VERSION ""

NS_ :

BS_:

BU_: FUSION IVI HMI Meter DataCenter WCM

BO_ 279 FD2_CE100_0: 64 FUSION
 SG_ CreepSW_Sta : 23|1@0+ (1,0) [0|1] "" IVI
 SG_ EngageP_Fail : 22|1@0+ (1,0) [0|1] "" IVI
 SG_ DisengageP_Fail : 21|1@0+ (1,0) [0|1] "" IVI
 SG_ FalseNPrevent_Sta : 20|1@0+ (1,0) [0|1] "" IVI
 SG_ DynoModeStaChk : 19|2@0+ (1,0) [0|2] "" IVI
 SG_ CoastDwModeStaChk : 17|2@0+ (1,0) [0|2] "" IVI
 SG_ DemoModeStaChk : 31|2@0+ (1,0) [0|2] "" IVI
 SG_ MSA_Crl_Sta : 29|3@0+ (1,0) [0|7] "" IVI
 SG_ CC_Crl_Sta : 26|3@0+ (1,0) [0|7] "" IVI
 SG_ LVChrgFuncStaChk : 39|2@0+ (1,0) [0|2] "" IVI
 SG_ ShiftGearPosn : 37|3@0+ (1,0) [0|7] "" IVI,HMI,Meter,DataCenter
 SG_ PwrSta : 34|3@0+ (1,0) [0|7] "" IVI,HMI,Meter,WCM,DataCenter
 SG_ XWDMode : 47|2@0+ (1,0) [0|2] "" IVI
 SG_ CCU_ACLampSts : 45|1@0+ (1,0) [0|1] "" IVI,HMI
 SG_ CCU_Dispaly_Request : 44|1@0+ (1,0) [0|1] "" IVI
 SG_ CCU_EcoSts : 43|1@0+ (1,0) [0|1] "" IVI
 SG_ CCU_AutoMidLampSts : 42|1@0+ (1,0) [0|1] "" IVI
 SG_ CCU_AutoLampSts : 41|1@0+ (1,0) [0|1] "" IVI,HMI,DataCenter
 SG_ CCU_ACMaxLampSts : 40|1@0+ (1,0) [0|1] "" IVI
 SG_ CCU_RrOnOffLampSts : 55|1@0+ (1,0) [0|1] "" IVI
 SG_ sigWindDirZon1St : 54|3@0+ (1,0) [0|7] "" IVI,HMI
 SG_ CCU_FrtOnOffLampSts : 51|1@0+ (1,0) [0|1] "" IVI
 SG_ sigWindDirZon3St : 50|3@0+ (1,0) [0|7] "" IVI
 SG_ sigAirIntenZon1St : 63|4@0+ (1,0) [0|15] "" IVI,HMI
 SG_ sigAirIntenZon3St : 59|4@0+ (1,0) [0|15] "" IVI
 SG_ CCU_SyncLampSts : 71|1@0+ (1,0) [0|1] "" IVI
 SG_ sigDfrstSt : 70|1@0+ (1,0) [0|1] "" IVI,HMI
 SG_ sigSetTempZon3St : 69|6@0+ (0.5,17) [17|32] "Deg^C" IVI
 SG_ sigRecircSt : 79|1@0+ (1,0) [0|1] "" IVI,HMI
 SG_ sigHvacSt : 78|1@0+ (1,0) [0|1] "" IVI
 SG_ sigSetTempZon2St : 77|6@0+ (0.5,17) [17|32] "Deg^C" IVI,HMI
 SG_ VCUBrkSWSta : 87|2@0+ (1,0) [0|2] "" IVI
 SG_ sigSetTempZon1St : 85|6@0+ (0.5,17) [17|32] "Deg^C" IVI,HMI
 SG_ sigCbnAirT : 95|8@0+ (0.5,-40) [-40|85] "Deg^C" IVI
 SG_ sigAmbAirT : 103|8@0+ (0.5,-40) [-40|85] "Deg^C" IVI
 SG_ FD_AGS_Cmd : 111|8@0+ (1,0) [0|255] "" IVI
 SG_ SysPwrSta : 119|4@0+ (1,0) [0|15] "" IVI
 SG_ MCUActDisFail : 115|1@0+ (1,0) [0|1] "" IVI
 SG_ PwrStaONTOIVIPopReq : 114|1@0+ (1,0) [0|1] "" IVI
 SG_ VCUFLDoorSta : 113|1@0+ (1,0) [0|1] "" IVI
 SG_ VCUFRDoorSta : 112|1@0+ (1,0) [0|1] "" IVI
 SG_ VCURLDoorSta : 127|1@0+ (1,0) [0|1] "" IVI
 SG_ VCURRDoorSta : 126|1@0+ (1,0) [0|1] "" IVI
 SG_ HVRlyOpFail : 125|1@0+ (1,0) [0|1] "" IVI
 SG_ SysAllowReadySta : 124|1@0+ (1,0) [0|1] "" IVI
 SG_ PwrStaONTOIVIPopT : 123|12@0+ (1,0) [0|4095] "SECOND" IVI
 SG_ Req_V2LSwOn : 140|1@0+ (1,0) [0|1] "" IVI
 SG_ Req_V2L_IVI_Popup : 139|4@0+ (1,0) [0|7] "" IVI
 SG_ MeterIndSpeed_raw32 : 151|8@0+ (1,0) [0|255] "" IVI,Meter
 SG_ DISC_Sta : 159|2@0+ (1,0) [0|3] "" IVI
 SG_ DISC_ButtSta : 143|1@0+ (1,0) [0|1] "" IVI
 SG_ CCMSA_SpdWar : 167|1@0+ (1,0) [0|1] "" IVI
 SG_ ActAPSPosn : 175|8@0+ (0.394,0) [0|100.076] "%" IVI
 SG_ VCUHoodSWSta : 166|1@0+ (1,0) [0|1] "" IVI
 SG_ VCUTailgateSWSta : 165|1@0+ (1,0) [0|1] "" IVI
 SG_ FD_EPB_Error : 177|2@0+ (1,0) [0|2] "" IVI,Meter
 SG_ FD_Park_Brake_Warning : 189|2@0+ (1,0) [0|2] "" IVI,Meter
 SG_ FD_TCS_Indicator : 163|2@0+ (1,0) [0|2] "" IVI,Meter
 SG_ FD_ABS_Warning : 183|2@0+ (1,0) [0|2] "" IVI,Meter
 SG_ FD_Steering_Warning : 161|2@0+ (1,0) [0|2] "" IVI,Meter
 SG_ FD_HV_Battery_Fault : 191|2@0+ (1,0) [0|2] "" IVI,Meter
 SG_ FD_EDrive_System : 179|2@0+ (1,0) [0|2] "" IVI,Meter
 SG_ FD_Battery_Charge_Warning : 181|2@0+ (1,0) [0|2] "" IVI,Meter
 SG_ FD_Power_limitation : 187|2@0+ (1,0) [0|2] "" IVI,Meter
 SG_ FD_Telltale_Fail : 164|1@0+ (1,0) [0|1] "" IVI,Meter
 SG_ FeatSetSpdFinal_raw32 : 199|8@0+ (1,0) [0|255] "" IVI
 SG_ Eng_ActvDmpDisabSta : 153|2@0+ (1,0) [0|2] "" IVI
 SG_ Eng_CoastDwSta : 155|2@0+ (1,0) [0|2] "" IVI
 SG_ Eng_PwrLockSta : 185|2@0+ (1,0) [0|2] "" IVI
 SG_ EDriveSysErr_AccPedalErr : 141|1@0+ (1,0) [0|1] "" IVI,Meter
 SG_ EDriveSysErr_MCUErr : 203|1@0+ (1,0) [0|1] "" IVI,Meter
 SG_ EDriveSysErr_ShifterErr : 223|1@0+ (1,0) [0|1] "" IVI,Meter
 SG_ EDriveSysErr_VCUErr : 142|1@0+ (1,0) [0|1] "" IVI,Meter
 SG_ Eng_AGSCloseSta : 222|1@0+ (1,0) [0|1] "" IVI
 SG_ Dimmer : 254|7@0+ (1,0) [0|100] "%" IVI
 SG_ VehMalfunLevel : 202|3@0+ (1,0) [0|5] "" IVI
 SG_ AntitheftSta : 244|2@0+ (1,0) [0|3] "" IVI,DataCenter
 SG_ Dr_SeatSta : 239|2@0+ (1,0) [0|2] "" IVI
 SG_ EVDriveMode : 157|2@0+ (1,0) [0|2] "" IVI
 SG_ AllDoorSW : 205|1@0+ (1,0) [0|1] "" IVI
 SG_ BCM_DoorLock_Sta : 240|1@0+ (1,0) [0|1] "" IVI,DataCenter
 SG_ BrakeLamp : 236|1@0+ (1,0) [0|1] "" IVI
 SG_ DoorLockIND : 204|1@0+ (1,0) [0|1] "" IVI
 SG_ DrDoorSW : 225|1@0+ (1,0) [0|1] "" IVI
 SG_ FollowMe : 242|1@0+ (1,0) [0|1] "" IVI
 SG_ Fr_FogLamp : 237|1@0+ (1,0) [0|1] "" IVI
 SG_ HazardSW : 227|1@0+ (1,0) [0|1] "" IVI
 SG_ HoodSW : 213|1@0+ (1,0) [0|1] "" IVI
 SG_ HVSysErr_IsolationErr : 210|1@0+ (1,0) [0|1] "" IVI,Meter
 SG_ HVSysErr_PackErr : 211|1@0+ (1,0) [0|1] "" IVI,Meter
 SG_ HVSysErr_RelayErr : 212|1@0+ (1,0) [0|1] "" IVI,Meter
 SG_ H_Beam : 226|1@0+ (1,0) [0|1] "" IVI
 SG_ LBSD : 230|1@0+ (1,0) [0|1] "" IVI
 SG_ LDRL : 233|1@0+ (1,0) [0|1] "" IVI
 SG_ LimphomeAct : 207|1@0+ (1,0) [0|1] "" IVI,Meter
 SG_ LockSetting : 247|1@0+ (1,0) [0|1] "" IVI
 SG_ LTurnLP : 246|1@0+ (1,0) [0|1] "" IVI,Meter
 SG_ LVSysErr_PwrOutpErr : 208|1@0+ (1,0) [0|1] "" IVI,Meter
 SG_ L_Beam : 224|1@0+ (1,0) [0|1] "" IVI
 SG_ PAS_Sta_F_Sys : 214|1@0+ (1,0) [0|1] "" IVI
 SG_ PosLamp : 232|1@0+ (1,0) [0|1] "" IVI
 SG_ PsDoorSW : 229|1@0+ (1,0) [0|1] "" IVI
 SG_ PwrStaErr : 209|1@0+ (1,0) [0|1] "" IVI,Meter
 SG_ RBSD : 241|1@0+ (1,0) [0|1] "" IVI
 SG_ RDRL : 234|1@0+ (1,0) [0|1] "" IVI
 SG_ ReverseLamp : 235|1@0+ (1,0) [0|1] "" IVI
 SG_ RLDoorSW : 231|1@0+ (1,0) [0|1] "" IVI
 SG_ RRDoorSW : 206|1@0+ (1,0) [0|1] "" IVI
 SG_ Rr_Defog : 215|1@0+ (1,0) [0|1] "" IVI,HMI
 SG_ Rr_FogLamp : 228|1@0+ (1,0) [0|1] "" IVI
 SG_ RTurnLP : 245|1@0+ (1,0) [0|1] "" IVI,Meter
 SG_ Tailgate_SW : 255|1@0+ (1,0) [0|1] "" IVI
 SG_ FD_EBMErrSta : 221|2@0+ (1,0) [0|2] "" IVI,Meter
 SG_ APMDoorControlSta : 219|1@0+ (1,0) [0|1] "" IVI
 SG_ Req_Internal_V2L_Status_Lamp : 217|2@0+ (1,0) [0|3] "" IVI
 SG_ VCU_OPDHold : 218|1@0+ (1,0) [0|1] "" IVI
 SG_ DimmerEN : 15|1@0+ (1,0) [0|1] "" Vector__XXX
 SG_ FDC_VCU_PwrSaveReq_Cmd : 14|1@0+ (1,0) [0|1] "" IVI
 SG_ FDC_THCM_LEVentY_Sta : 7|7@0+ (1,0) [0|127] "%" IVI
 SG_ FDC_THCM_REVentY_Sta : 263|7@0+ (1,0) [0|127] "%" IVI
 SG_ FDC_THCM_CLEVentY_Sta : 271|7@0+ (1,0) [0|127] "%" IVI
 SG_ FDC_THCM_CREVentY_Sta : 279|7@0+ (1,0) [0|127] "%" IVI
 SG_ FDC_THCM_LEVentZ_Sta : 287|7@0+ (1,0) [0|127] "%" IVI
 SG_ FDC_THCM_REVentZ_Sta : 295|7@0+ (1,0) [0|127] "%" IVI
 SG_ FDC_THCM_CLEVentZ_Sta : 303|7@0+ (1,0) [0|127] "%" IVI
 SG_ FDC_THCM_CREVentZ_Sta : 311|7@0+ (1,0) [0|127] "%" IVI
 SG_ FDC_THCM_LEVentMode_Sta : 13|3@0+ (1,0) [0|7] "" IVI
 SG_ FDC_THCM_REVentMode_Sta : 10|3@0+ (1,0) [0|7] "" IVI
 SG_ FDC_THCM_LVent_Sta : 0|1@0+ (1,0) [0|1] "" IVI
 SG_ FDC_THCM_CLVent_Sta : 256|1@0+ (1,0) [0|1] "" IVI
 SG_ FDC_THCM_RVent_Sta : 264|1@0+ (1,0) [0|1] "" IVI
 SG_ FDC_THCM_CRVent_Sta : 272|1@0+ (1,0) [0|1] "" IVI
 SG_ LVSilentChrgSta : 319|2@0+ (1,0) [0|3] "" IVI,DataCenter
 SG_ FDC_THCM_PreWPTCHeat_Sta : 317|2@0+ (1,0) [0|3] "" IVI
 SG_ FDC_RAPS_ErrWarn_Sta : 315|3@0+ (1,0) [0|7] "" IVI
 SG_ FDC_V2L_IVIV2LDischarg_Cmd : 327|2@0+ (1,0) [0|3] "" IVI
 SG_ FDC_BCM_HMIKey1Func_Sta : 335|4@0+ (1,0) [0|15] "" HMI
 SG_ FDC_BCM_HMIKey2Func_Sta : 331|4@0+ (1,0) [0|15] "" HMI
 SG_ FDC_BCM_HMIKey3Func_Sta : 343|4@0+ (1,0) [0|15] "" HMI
 SG_ FDC_BCM_HMIKey4Func_Sta : 339|4@0+ (1,0) [0|15] "" HMI
 SG_ FDC_BCM_HMIKey5Func_Sta : 351|4@0+ (1,0) [0|15] "" HMI
 SG_ FDC_BCM_HMIKey6Func_Sta : 347|4@0+ (1,0) [0|15] "" HMI
 SG_ FDC_BCM_HMIKey7Func_Sta : 359|4@0+ (1,0) [0|15] "" HMI
 SG_ FDC_BCM_HMIKey8Func_Sta : 355|4@0+ (1,0) [0|15] "" HMI
 SG_ LVSilentChrgReq : 280|1@0+ (1,0) [0|1] "" IVI,DataCenter
 SG_ FDC_BCM_AutoWipHSpdEN_Sta : 288|1@0+ (1,0) [0|1] "" IVI
 SG_ FDC_VCU_LVChrgFreq_Sta : 325|2@0+ (1,0) [0|3] "" IVI,Meter,DataCenter
 SG_ FDC_VCU_TrailerDisOPD_Sta : 296|1@0+ (1,0) [0|1] "" IVI
 SG_ FDC_VCU_LVStaTooLow_Sta : 304|1@0+ (1,0) [0|1] "" IVI,Meter,DataCenter
 SG_ FDC_VCU_LVStaDropQuick_Sta : 312|1@0+ (1,0) [0|1] "" IVI,Meter,DataCenter

BO_ 435 GW2_C10_0: 32 FUSION
 SG_ VehSpeed : 23|12@0+ (0.125,0) [0|255.875] "km/h" IVI,HMI,Meter,WCM
 SG_ LF_WhlRotDir : 45|2@0+ (1,0) [0|3] "" IVI
 SG_ RF_WhlRotDir : 47|2@0+ (1,0) [0|3] "" IVI
 SG_ RF_PulseCount : 71|8@0+ (1,0) [0|255] "" IVI
 SG_ RF_PulseCount_V : 55|1@0+ (1,0) [0|1] "" IVI
 SG_ LF_PulseCount_V : 54|1@0+ (1,0) [0|1] "" IVI
 SG_ LF_PulseCount : 79|8@0+ (1,0) [0|255] "" IVI
 SG_ RR_PulseCount_V : 53|1@0+ (1,0) [0|1] "" IVI
 SG_ RR_WhlRotDir : 43|2@0+ (1,0) [0|3] "" IVI
 SG_ RR_PulseCount : 87|8@0+ (1,0) [0|255] "" IVI
 SG_ LR_PulseCount_V : 52|1@0+ (1,0) [0|1] "" IVI
 SG_ LR_WhlRotDir : 41|2@0+ (1,0) [0|3] "" IVI
 SG_ LR_PulseCount : 95|8@0+ (1,0) [0|255] "" IVI
 SG_ ESC_BeepReq : 111|1@0+ (1,0) [0|1] "" IVI
 SG_ ESC_OFF_Status : 99|2@0+ (1,0) [0|2] "" IVI
 SG_ HDD_Failed : 108|1@0+ (1,0) [0|1] "" IVI
 SG_ AVH_Failed : 107|1@0+ (1,0) [0|1] "" IVI
 SG_ HSA_Failed : 106|1@0+ (1,0) [0|1] "" IVI
 SG_ PBA_Failed : 105|1@0+ (1,0) [0|1] "" IVI
 SG_ HBB_Failed : 104|1@0+ (1,0) [0|1] "" IVI
 SG_ ESC_Failed : 119|1@0+ (1,0) [0|1] "" IVI
 SG_ TCS_Failed : 118|1@0+ (1,0) [0|1] "" IVI
 SG_ ABS_Failed : 117|1@0+ (1,0) [0|1] "" IVI
 SG_ EBD_Failed : 116|1@0+ (1,0) [0|1] "" IVI
 SG_ HDD_Active : 115|1@0+ (1,0) [0|1] "" IVI
 SG_ ESS_Active : 114|1@0+ (1,0) [0|1] "" IVI
 SG_ BTCS_Active : 113|1@0+ (1,0) [0|1] "" IVI
 SG_ Amber_WnlmpSta : 112|1@0+ (1,0) [0|1] "" IVI,Meter
 SG_ AVH_Active : 127|1@0+ (1,0) [0|1] "" IVI
 SG_ HSA_Active : 126|1@0+ (1,0) [0|1] "" IVI
 SG_ PBA_Active : 125|1@0+ (1,0) [0|1] "" IVI
 SG_ HBB_Active : 124|1@0+ (1,0) [0|1] "" IVI
 SG_ ABS_Active : 123|1@0+ (1,0) [0|1] "" IVI
 SG_ ESC_WnlmpSta : 97|2@0+ (1,0) [0|2] "" IVI,Meter
 SG_ ESC_Off_lmpSta : 120|1@0+ (1,0) [0|1] "" IVI
 SG_ ABS_WnlmpSta : 109|1@0+ (1,0) [0|1] "" IVI,Meter
 SG_ Red_WnlmpSta : 122|1@0+ (1,0) [0|1] "" IVI
 SG_ eBST_BeepReq : 100|1@0+ (1,0) [0|1] "" IVI
 SG_ eBST_RedWnlmpSta : 101|1@0+ (1,0) [0|1] "" IVI
 SG_ eBST_AmberWnlmpSta : 103|1@0+ (1,0) [0|1] "" IVI,Meter
 SG_ LowBrakeFluid_Sta : 102|1@0+ (1,0) [0|1] "" IVI
 SG_ HVBattVolt : 132|13@0+ (0.1,0) [0|819] "V" IVI
 SG_ DCDCAuxCur : 51|12@0+ (0.1,0) [0|409.5] "A" IVI
 SG_ HVBattCurr : 150|15@0+ (0.1,-1000) [-1000|2276.5] "A" IVI
 SG_ DCDCAuxVolt : 167|8@0+ (0.047,8) [8|19.938] "V" IVI
 SG_ Meter_Ind_VehSpeed : 27|12@0+ (0.125,0) [0|300] "km/h" IVI
 SG_ ESC_ADAS_Sta : 135|3@0+ (1,0) [0|6] "" IVI
 SG_ AEBAvail : 110|1@0+ (1,0) [0|1] "" IVI
 SG_ BrkDiscTempSta : 175|1@0+ (1,0) [0|1] "" IVI
 SG_ BrkSw_Sta : 121|1@0+ (1,0) [0|1] "" IVI
 SG_ BrkSw_V : 151|1@0+ (1,0) [0|1] "" IVI
 SG_ EBMErrSta : 174|2@0+ (1,0) [0|2] "" IVI,Meter
 SG_ EBMRLampSta : 172|2@0+ (1,0) [0|2] "" IVI,Meter
 SG_ LADB_Hibeam_Indication : 183|1@0+ (1,0) [0|1] "" IVI,Meter
 SG_ LADB_Operation_Status : 182|1@0+ (1,0) [0|1] "" IVI,Meter
 SG_ LADB_Warning : 181|1@0+ (1,0) [0|1] "" IVI,Meter
 SG_ LLB_Warning : 180|1@0+ (1,0) [0|1] "" IVI,Meter
 SG_ LAHB_Warning : 179|1@0+ (1,0) [0|1] "" IVI,Meter
 SG_ FLTurn_Light_Warning : 178|1@0+ (1,0) [0|1] "" IVI,Meter
 SG_ LDRL_Warning : 177|1@0+ (1,0) [0|1] "" IVI,Meter
 SG_ Lposition_Lamp_Warning : 176|1@0+ (1,0) [0|1] "" IVI,Meter
 SG_ RADB_Hibeam_Indication : 191|1@0+ (1,0) [0|1] "" IVI,Meter
 SG_ RADB_Operation_Status : 190|1@0+ (1,0) [0|1] "" IVI,Meter
 SG_ RADB_Warning : 189|1@0+ (1,0) [0|1] "" IVI,Meter
 SG_ RLB_Warning : 188|1@0+ (1,0) [0|1] "" IVI,Meter
 SG_ RAHB_Warning : 187|1@0+ (1,0) [0|1] "" IVI,Meter
 SG_ FRTurn_Light_Warning : 186|1@0+ (1,0) [0|1] "" IVI,Meter
 SG_ RDRL_Warning : 185|1@0+ (1,0) [0|1] "" IVI,Meter
 SG_ Rposition_Lamp_Warning : 184|1@0+ (1,0) [0|1] "" IVI,Meter
 SG_ SAS_Angle : 231|16@0+ (0.1,-900) [-900|900] "Deg" IVI
 SG_ CrashOutputSts : 247|8@0+ (1,0) [0|255] "" IVI
 SG_ EpasFailed : 217|2@0+ (1,0) [0|2] "" IVI,Meter
 SG_ AirBagFailCmd : 219|1@0+ (1,0) [0|1] "" IVI
 SG_ DriverSeatBeltCmd : 199|1@0+ (1,0) [0|1] "" IVI
 SG_ DrPMMLVOutPErrLmp : 206|1@0+ (1,0) [0|1] "" IVI,Meter
 SG_ DrPMMSysErrLmp : 207|1@0+ (1,0) [0|1] "" IVI,Meter
 SG_ DrSCPSysErrLmp : 205|1@0+ (1,0) [0|1] "" IVI,Meter
 SG_ FireDetErr : 220|1@0+ (1,0) [0|1] "" IVI
 SG_ FrPMMLimpHomeActReq : 204|1@0+ (1,0) [0|1] "" IVI,Meter
 SG_ HVBattErr : 218|1@0+ (1,0) [0|1] "" IVI,Meter
 SG_ PABSwitchCmd : 192|1@0+ (1,0) [0|1] "" IVI
 SG_ PsngrSeatBeltCmd : 197|1@0+ (1,0) [0|1] "" IVI
 SG_ RCenterSeatBeltCmd : 193|1@0+ (1,0) [0|1] "" IVI
 SG_ RDriverSeatBeltCmd : 198|1@0+ (1,0) [0|1] "" IVI
 SG_ RPsngrSeatBeltCmd : 196|1@0+ (1,0) [0|1] "" IVI
 SG_ SAS_V : 221|1@0+ (1,0) [0|1] "" IVI
 SG_ TLHPsngrSeatBeltCmd : 195|1@0+ (1,0) [0|1] "" IVI
 SG_ TRHPsngrSeatBeltCmd : 194|1@0+ (1,0) [0|1] "" IVI
 SG_ ABM_Passenger_ODS_Sta : 203|1@0+ (1,0) [0|1] "" IVI,Meter
 SG_ ABM_RearPassengerLH_ODS_Sta : 202|1@0+ (1,0) [0|1] "" IVI,Meter
 SG_ ABM_RearPassengerCTR_ODS_Sta : 201|1@0+ (1,0) [0|1] "" IVI,Meter
 SG_ ABM_RearPassengerRH_ODS_Sta : 200|1@0+ (1,0) [0|1] "" IVI,Meter
 SG_ LADBErr : 208|1@0+ (1,0) [0|1] "" IVI,Meter
 SG_ LH_BeamErr : 210|1@0+ (1,0) [0|1] "" IVI,Meter
 SG_ LL_BeamErr : 209|1@0+ (1,0) [0|1] "" IVI,Meter
 SG_ RADBErr : 168|1@0+ (1,0) [0|1] "" IVI,Meter
 SG_ RH_BeamErr : 170|1@0+ (1,0) [0|1] "" IVI,Meter
 SG_ RL_BeamErr : 169|1@0+ (1,0) [0|1] "" IVI,Meter
 SG_ RLTurnLPErr : 223|1@0+ (1,0) [0|1] "" IVI,Meter
 SG_ RRTurnLPErr : 222|1@0+ (1,0) [0|1] "" IVI,Meter
 SG_ FLTurnLPErr : 215|1@0+ (1,0) [0|1] "" IVI,Meter
 SG_ FRTurnLPErr : 214|1@0+ (1,0) [0|1] "" IVI,Meter

BO_ 372 GW2_CE200_0: 32 FUSION
 SG_ ADAS_VehSpdLim : 23|8@0+ (1,0) [0|254] "" IVI
 SG_ ADAS_LFC_Warn_Sound : 31|8@0+ (1,0) [0|255] "" IVI
 SG_ ACC_ObjDist : 98|11@0+ (0.1,0) [0|204.6] "m" IVI
 SG_ ACC_ObjRelSpd : 82|11@0+ (0.1,-100) [-100|104.6] "m/s" IVI
 SG_ ADAS_CAM_SpdLim : 44|5@0+ (1,0) [0|31] "" IVI
 SG_ ADAS_SLIF_SpdLim : 36|5@0+ (1,0) [0|31] "" IVI
 SG_ ADAS_ISA_Sta : 87|4@0+ (1,0) [0|6] "" IVI
 SG_ ADAS_WarningMsg : 55|4@0+ (1,0) [0|15] "" IVI
 SG_ ACC_ObjDstLvl : 70|3@0+ (1,0) [0|7] "" IVI
 SG_ ADAS_ACC_Sta : 47|3@0+ (1,0) [0|7] "" IVI
 SG_ ADAS_AEBReq : 115|3@0+ (1,0) [0|7] "" IVI
 SG_ ADAS_AEB_Sta : 66|3@0+ (1,0) [0|7] "" IVI
 SG_ ADAS_FCW_Sta : 39|3@0+ (1,0) [0|7] "" IVI
 SG_ ADAS_LaneModeL : 118|3@0+ (1,0) [0|7] "" IVI
 SG_ ADAS_LaneModeR : 190|3@0+ (1,0) [0|7] "" IVI
 SG_ ADAS_LDW_Sta : 78|3@0+ (1,0) [0|7] "" IVI
 SG_ ADAS_LFC_Sta : 102|3@0+ (1,0) [0|7] "" IVI
 SG_ ADAS_LKA_Sta : 187|3@0+ (1,0) [0|7] "" IVI
 SG_ ADAS_SLIF_Sta : 74|3@0+ (1,0) [0|5] "" IVI
 SG_ ADAS_LFC_Hands_Off_Warning : 207|2@0+ (1,0) [0|3] "" IVI
 SG_ ACC_TakeoverReq : 83|1@0+ (1,0) [0|1] "" IVI
 SG_ ActBrkLamp_Sta : 119|1@0+ (1,0) [0|1] "" IVI
 SG_ ADAS_FCW_Mute : 191|1@0+ (1,0) [0|1] "" IVI
 SG_ ADAS_FltWrnReq : 103|1@0+ (1,0) [0|1] "" IVI
 SG_ ADAS_LDW_Mute : 99|1@0+ (1,0) [0|1] "" IVI
 SG_ LVDA_Mute_Sta : 135|2@0+ (1,0) [0|3] "" IVI
 SG_ LKA_HOD_Display_Warning : 67|1@0+ (1,0) [0|1] "" IVI
 SG_ LKA_HOD_Sound_Warning : 75|1@0+ (1,0) [0|1] "" IVI
 SG_ LVDA_ACCStatusInformation : 2|1@0+ (1,0) [0|1] "" IVI
 SG_ LVDA_Disabled : 3|1@0+ (1,0) [0|1] "" IVI
 SG_ LVDA_Failinfo : 59|1@0+ (1,0) [0|1] "" IVI
 SG_ LVDA_Warning : 63|1@0+ (1,0) [0|1] "" IVI
 SG_ ISA_WarningMsg : 51|4@0+ (1,0) [0|6] "" IVI
 SG_ ForceLowBeam : 1|2@0+ (1,0) [0|2] "" IVI
 SG_ CameraBlockage : 4|1@0+ (1,0) [0|1] "" IVI
 SG_ HazardWarningReq : 15|1@0+ (1,0) [0|1] "" IVI
 SG_ LeftTurnLightReq : 71|1@0+ (1,0) [0|1] "" IVI
 SG_ Target_Type : 11|4@0+ (1,0) [0|15] "" IVI
 SG_ RightTurnLightReq : 79|1@0+ (1,0) [0|1] "" IVI
 SG_ ADAS_FCW_Sensitivity : 6|1@0+ (1,0) [0|1] "" IVI
 SG_ ADAS_LDW_Sensitivity : 5|1@0+ (1,0) [0|1] "" IVI
 SG_ MCU_B_R_RealPwrKw_Sta : 159|16@0+ (0.1,-530) [-530|6023.4] "KW" IVI
 SG_ MCU_B_F_RealPwrKw_Sta : 143|16@0+ (0.1,-530) [-530|6023.4] "KW" IVI
 SG_ HVBSOH : 175|8@0+ (0.4,0) [0|100] "%" IVI
 SG_ FDC_BCM_TimeGapLevel_Sta : 14|3@0+ (1,0) [0|7] "" IVI
 SG_ HVBPwrAvailChrg : 235|12@0+ (0.2,0) [0|819] "KW" IVI
 SG_ HVBPwrAvailChrg30 : 231|12@0+ (0.2,0) [0|819] "KW" IVI
 SG_ HVBPwrAvailChrg60 : 211|12@0+ (0.2,0) [0|819] "KW" IVI
 SG_ HVBFullChrgPwr : 205|10@0+ (0.1,0) [0|102.2] "KWh" IVI

BO_ 450 GW2_CE100_0: 32 FUSION
 SG_ HVBChrgErr : 23|8@0+ (1,0) [0|255] "" IVI
 SG_ V2LSta : 31|2@0+ (1,0) [0|3] "" IVI
 SG_ DisChrgPlugErr : 29|2@0+ (1,0) [0|3] "" IVI
 SG_ ExtChrgSta : 27|2@0+ (1,0) [0|3] "" IVI
 SG_ ChrgPlugSta : 25|2@0+ (1,0) [0|3] "" IVI
 SG_ HVBOvrTempErr : 39|1@0+ (1,0) [0|1] "" IVI
 SG_ OBC_AC_Cur_Lim : 38|2@0+ (1,0) [0|3] "" IVI
 SG_ HVBOvrTempWarn : 36|2@0+ (1,0) [0|2] "" IVI
 SG_ Shifter_Fail_sta : 34|3@0+ (1,0) [0|7] "" IVI
 SG_ Shifter_Handle_Cmd : 47|8@0+ (1,0) [0|255] "" IVI
 SG_ OBCACVoltInf : 55|12@0+ (0.1,0) [0|409.4] "V" IVI
 SG_ OBCFaultSta : 59|2@0+ (1,0) [0|3] "" IVI
 SG_ OBCACCurrInf : 57|10@0+ (0.125,-40) [-40|87.75] "A" IVI
 SG_ FrntPTCLeActHeatPwr : 79|8@0+ (25,0) [0|6375] "W" IVI
 SG_ FrntPTCRiActHeatPwr : 87|8@0+ (25,0) [0|6375] "W" IVI
 SG_ FrntPTCRearLeActHeatPwr : 95|8@0+ (25,0) [0|6375] "W" IVI
 SG_ FrntPTCRearRiActHeatPwr : 103|8@0+ (25,0) [0|6375] "W" IVI
 SG_ HVBContactorSta : 111|1@0+ (1,0) [0|1] "" IVI
 SG_ RLS_Lamp_Sta : 110|1@0+ (1,0) [0|1] "" IVI
 SG_ SWC_ACC_Sta : 119|1@0+ (1,0) [0|1] "" IVI
 SG_ SWC_Down_Sta : 118|1@0+ (1,0) [0|1] "" IVI
 SG_ SWC_RegenUp : 117|1@0+ (1,0) [0|1] "" IVI
 SG_ SWC_Left_Sta : 116|1@0+ (1,0) [0|1] "" IVI
 SG_ SWC_mode_Sta : 115|1@0+ (1,0) [0|1] "" IVI
 SG_ SWC_Right_Sta : 114|1@0+ (1,0) [0|1] "" IVI
 SG_ SWC_Trip_Sta : 113|1@0+ (1,0) [0|1] "" IVI
 SG_ SWC_Up_Sta : 112|1@0+ (1,0) [0|1] "" IVI
 SG_ SWC_LKA_Sta : 127|1@0+ (1,0) [0|1] "" IVI
 SG_ SWC_Undefined_Sta : 135|1@0+ (1,0) [0|1] "" IVI
 SG_ SWC_VR_Sta : 143|1@0+ (1,0) [0|1] "" IVI
 SG_ ChargeInletLockSta : 151|1@0+ (1,0) [0|1] "" IVI
 SG_ COMP_ActualPwr : 180|13@0+ (1,0) [0|6000] "W" IVI
 SG_ MainRlyPosSta : 199|8@0+ (1,0) [0|255] "" IVI
 SG_ MainRlyNegSta : 207|8@0+ (1,0) [0|255] "" IVI
 SG_ P_Dkey_Show_IVI : 215|4@0+ (1,0) [0|15] "" IVI
 SG_ P_KeyMiss : 211|1@0+ (1,0) [0|1] "" IVI
 SG_ P_UID_LowPower : 231|1@0+ (1,0) [0|1] "" IVI
 SG_ HVBMTempMax : 239|8@0+ (1,-40) [-40|213] "Deg^C" IVI
 SG_ TBOX_NET_SIG_STR : 219|4@0+ (1,0) [0|8] "" IVI
 SG_ TBOX_TEST_STATUS : 227|4@0+ (1,0) [0|15] "" IVI
 SG_ CbnPreACEnaReq : 229|2@0+ (1,0) [0|3] "" IVI
 SG_ Re_Radio : 181|1@0+ (1,0) [0|1] "" IVI
 SG_ TrailerModeSta : 255|2@0+ (1,0) [0|3] "" IVI
 SG_ TrailerCheck : 253|1@0+ (1,0) [0|1] "" IVI
 SG_ SWC_RegenDown : 230|1@0+ (1,0) [0|1] "" IVI
 SG_ FDC_BCM_FWipSw_Sta : 109|3@0+ (1,0) [0|7] "" IVI
 SG_ FDC_BCM_TurnSw_Sta : 106|2@0+ (1,0) [0|3] "" IVI,Meter
 SG_ FDC_BCM_DimSw : 104|1@0+ (1,0) [0|1] "" IVI
 SG_ OBCACCSLimit : 15|8@0+ (1,0) [0|80] "A" IVI
 SG_ ZFR_BCM_ChargerDoorSW_Sta : 126|1@0+ (1,0) [0|1] "" IVI
 SG_ DKC_KeyType_Sta : 125|2@0+ (1,0) [0|3] "" IVI
 SG_ DKC_KeyNum_Sta : 123|4@0+ (1,0) [0|15] "" IVI
 SG_ ZFR_EChrg_Active_Sta : 210|3@0+ (1,0) [0|7] "" IVI
 SG_ ZFR_EChrg_Sys_Sta : 183|2@0+ (1,0) [0|3] "" IVI
 SG_ ZFR_EChrg_OperationDeny_Cmd : 252|2@0+ (1,0) [0|3] "" IVI
 SG_ ZFR_EChrg_WashMode_Sta : 250|1@0+ (1,0) [0|1] "" IVI
 SG_ EBMSta : 134|3@0+ (1,0) [0|7] "" IVI

BO_ 528 FD2_C20_0: 32 FUSION
 SG_ USS_Sta_FCL : 7|1@0+ (1,0) [0|1] "" IVI
 SG_ USS_Sta_FCR : 6|1@0+ (1,0) [0|1] "" IVI
 SG_ USS_Sta_FLL : 5|1@0+ (1,0) [0|1] "" IVI
 SG_ USS_Sta_FLR : 4|1@0+ (1,0) [0|1] "" IVI
 SG_ USS_Sta_FML : 3|1@0+ (1,0) [0|1] "" IVI
 SG_ USS_Sta_FMR : 2|1@0+ (1,0) [0|1] "" IVI
 SG_ USS_Sta_RCL : 1|1@0+ (1,0) [0|1] "" IVI
 SG_ USS_Sta_RCR : 0|1@0+ (1,0) [0|1] "" IVI
 SG_ USS_Sta_RLL : 15|1@0+ (1,0) [0|1] "" IVI
 SG_ USS_Sta_RLR : 14|1@0+ (1,0) [0|1] "" IVI
 SG_ USS_Sta_RML : 13|1@0+ (1,0) [0|1] "" IVI
 SG_ USS_Sta_RMR : 12|1@0+ (1,0) [0|1] "" IVI
 SG_ PAS_A_FCR : 23|4@0+ (1,0) [0|15] "" IVI
 SG_ PAS_A_FML : 19|4@0+ (1,0) [0|15] "" IVI
 SG_ PAS_A_FMR : 31|4@0+ (1,0) [0|15] "" IVI
 SG_ PAS_A_RCL : 27|4@0+ (1,0) [0|15] "" IVI
 SG_ PAS_A_RCR : 39|4@0+ (1,0) [0|15] "" IVI
 SG_ PAS_A_RML : 35|4@0+ (1,0) [0|15] "" IVI
 SG_ PAS_A_RMR : 47|4@0+ (1,0) [0|15] "" IVI
 SG_ PAS_SNSR_Layout : 43|4@0+ (1,0) [0|15] "" IVI
 SG_ PAS_D_FCL : 119|8@0+ (1,0) [0|150] "" IVI
 SG_ PAS_D_FCR : 127|8@0+ (1,0) [0|150] "" IVI
 SG_ PAS_D_FML : 135|8@0+ (1,0) [0|150] "" IVI
 SG_ PAS_D_FMR : 143|8@0+ (1,0) [0|150] "" IVI
 SG_ APS_ExitCondition : 151|8@0+ (1,0) [0|255] "" IVI
 SG_ APS_SW_Ver : 167|8@0+ (1,0) [0|255] "" IVI
 SG_ PAS_D_RCL : 175|8@0+ (1,0) [0|150] "" IVI
 SG_ PAS_D_RCR : 183|8@0+ (1,0) [0|150] "" IVI
 SG_ PAS_D_RML : 191|8@0+ (1,0) [0|150] "" IVI
 SG_ PAS_D_RMR : 199|8@0+ (1,0) [0|150] "" IVI
 SG_ APS_RQ_Display : 207|8@0+ (1,0) [0|255] "" IVI
 SG_ PAS_Chime : 223|4@0+ (1,0) [0|15] "" IVI
 SG_ PAS_A_FCL : 219|4@0+ (1,0) [0|15] "" IVI
 SG_ APS_Sta_System : 250|3@0+ (1,0) [0|7] "" IVI
 SG_ CAAS_Sta : 253|3@0+ (1,0) [0|7] "" IVI
 SG_ FDC_VCU_RegenMode_Sta : 74|3@0+ (1,0) [0|7] "" IVI,Meter
 SG_ FDC_VMC_SpdCtrlMode_Sta : 10|3@0+ (1,0) [0|7] "" IVI
 SG_ FDC_VMC_SpdCtrl_Sta : 11|1@0+ (1,0) [0|1] "" IVI
 SG_ FDC_VMC_SetSpd_Sta : 63|8@0+ (1,0) [0|255] "km/h" IVI
 SG_ FDC_VMC_SetSpdDisp_Sta : 55|8@0+ (1,0) [0|255] "" IVI
 SG_ VMC_VCU_CC_Crl_Sta : 66|3@0+ (1,0) [0|6] "" IVI
 SG_ VMC_VCU_MSA_Crl_Sta : 70|3@0+ (1,0) [0|6] "" IVI
 SG_ FDC_VCU_RegenLimInd_Sta : 71|1@0+ (1,0) [0|1] "" IVI,Meter
 SG_ FDC_VCU_SmartEco_Sta : 75|1@0+ (1,0) [0|1] "" IVI
 SG_ FDC_VCU_SmartEcoSpdLim_Sta : 67|1@0+ (1,0) [0|1] "" IVI,Meter
 SG_ DISC_DISCTargetSpd : 99|12@0+ (0.125,0) [0|255.875] "km/h" IVI
 SG_ FDC_VCU_SimSound_Cmd : 95|12@0+ (0.1,-204.7) [-204.7|204.8] "%" IVI

BO_ 823 GW2_CE1000_0: 48 FUSION
 SG_ ACChrgCurrDis : 94|15@0+ (0.1,-1000) [-1000|2276.5] "A" IVI
 SG_ RemainChrgTime : 75|12@0+ (1,0) [0|4094] "MINUTE" IVI
 SG_ HVBChrgPwr : 57|10@0+ (0.1,0) [0|102.2] "KWh" IVI
 SG_ HVBattSOCDis : 119|8@0+ (0.4,0) [0|100] "%" IVI,Meter
 SG_ HVBattSOC : 127|8@0+ (0.4,0) [0|100] "%" IVI
 SG_ Charge_Percent_Set : 111|8@0+ (1,0) [0|100] "%" IVI
 SG_ TBOX_HW_VER : 135|32@0+ (1,0) [0|4.294967295E9] "" IVI
 SG_ TBOX_SW_VER : 167|32@0+ (1,0) [0|4.294967295E9] "" IVI
 SG_ Rr_MCU3_SW_Ver : 215|16@0+ (1,0) [0|65535] "" IVI
 SG_ Rr_MCU3_HW_Ver : 199|16@0+ (1,0) [0|65535] "" IVI
 SG_ Fr_MCU_SW_Ver : 247|16@0+ (1,0) [0|65535] "" IVI
 SG_ Fr_MCU_HW_Ver : 231|16@0+ (1,0) [0|65535] "" IVI
 SG_ Rr_MCU3_SW_Ver_Nidec : 279|16@0+ (1,0) [0|65535] "" IVI
 SG_ Rr_MCU3_HW_Ver_Nidec : 263|16@0+ (1,0) [0|65535] "" IVI
 SG_ PSEAT_SW_Ver : 375|16@0+ (1,0) [0|65535] "" IVI
 SG_ PSEAT_HW_Ver : 359|16@0+ (1,0) [0|65535] "" IVI
 SG_ Fr_MCU_SW_Ver_Nidec : 311|16@0+ (1,0) [0|65535] "" IVI
 SG_ Fr_MCU_HW_Ver_Nidec : 295|16@0+ (1,0) [0|65535] "" IVI
 SG_ DSEAT_SW_Ver : 343|16@0+ (1,0) [0|65535] "" IVI
 SG_ DSEAT_HW_Ver : 327|16@0+ (1,0) [0|65535] "" IVI
 SG_ PTG_HW_Ver : 63|5@0+ (1,0) [0|31] "" IVI
 SG_ PTG_SW_Ver : 55|5@0+ (1,0) [0|31] "" IVI
 SG_ HVBChrgPwrTotal : 7|18@0+ (1,0) [0|262143] "KWh" IVI
 SG_ HVBDrvPwrTotal : 21|18@0+ (1,0) [0|262143] "KWh" IVI
 SG_ HVBDrvPwr : 35|10@0+ (0.1,0) [0|102.2] "KWh" IVI

BO_ 963 FD2_Version: 48 FUSION
 SG_ FUSION_SW_Var1 : 135|8@0+ (1,0) [0|255] "" IVI
 SG_ FUSION_SW_Country2 : 127|8@0+ (1,0) [0|255] "" IVI
 SG_ FUSION_SW_Country1 : 119|8@0+ (1,0) [0|255] "" IVI
 SG_ FUSION_SW_Patch2 : 111|8@0+ (1,0) [0|255] "" IVI
 SG_ FUSION_SW_Patch1 : 103|8@0+ (1,0) [0|255] "" IVI
 SG_ FUSION_SW_Minor2 : 95|8@0+ (1,0) [0|255] "" IVI
 SG_ FUSION_SW_Minor1 : 87|8@0+ (1,0) [0|255] "" IVI
 SG_ FUSION_SW_Major2 : 79|8@0+ (1,0) [0|255] "" IVI
 SG_ FUSION_SW_Major1 : 71|8@0+ (1,0) [0|255] "" IVI
 SG_ FUSION_SW_Controller2 : 63|8@0+ (1,0) [0|255] "" IVI
 SG_ FUSION_SW_Controller1 : 55|8@0+ (1,0) [0|255] "" IVI
 SG_ FUSION_SW_CarModel3 : 47|8@0+ (1,0) [0|255] "" IVI
 SG_ FUSION_SW_CarModel2 : 39|8@0+ (1,0) [0|255] "" IVI
 SG_ FUSION_SW_CarModel1 : 31|8@0+ (1,0) [0|255] "" IVI
 SG_ FUSION_HW_Ver3 : 23|8@0+ (1,0) [0|255] "" IVI
 SG_ FUSION_HW_Ver2 : 15|8@0+ (1,0) [0|255] "" IVI
 SG_ FUSION_HW_Ver1 : 7|8@0+ (1,0) [0|255] "" IVI
 SG_ FUSION_SW_dash1 : 191|8@0+ (1,0) [0|255] "" IVI
 SG_ FUSION_SW_change1 : 199|8@0+ (1,0) [0|255] "" IVI
 SG_ FUSION_SW_change2 : 207|8@0+ (1,0) [0|255] "" IVI
 SG_ FUSION_SW_dash2 : 215|8@0+ (1,0) [0|255] "" IVI
 SG_ FUSION_SW_SHA1 : 223|8@0+ (1,0) [0|255] "" IVI
 SG_ FUSION_SW_SHA2 : 231|8@0+ (1,0) [0|255] "" IVI
 SG_ FUSION_SW_SHA3 : 239|8@0+ (1,0) [0|255] "" IVI
 SG_ FUSION_SW_SHA4 : 247|8@0+ (1,0) [0|255] "" IVI
 SG_ FUSION_SW_SHA5 : 255|8@0+ (1,0) [0|255] "" IVI
 SG_ FUSION_SW_SHA6 : 263|8@0+ (1,0) [0|255] "" IVI
 SG_ FUSION_SW_SHA7 : 271|8@0+ (1,0) [0|255] "" IVI
 SG_ FUSION_SW_SHA8 : 279|8@0+ (1,0) [0|255] "" IVI
 SG_ FUSION_SW_Var5 : 183|8@0+ (1,0) [0|255] "" IVI
 SG_ FUSION_SW_Var4 : 175|8@0+ (1,0) [0|255] "" IVI
 SG_ FUSION_SW_Var3 : 167|8@0+ (1,0) [0|255] "" IVI
 SG_ FUSION_SW_Var2 : 159|8@0+ (1,0) [0|255] "" IVI
 SG_ FUSION_SW_ECUGen2 : 151|8@0+ (1,0) [0|255] "" IVI
 SG_ FUSION_SW_ECUGen1 : 143|8@0+ (1,0) [0|255] "" IVI

BO_ 1077 FD2_CE200_1: 32 FUSION
 SG_ TPMSWarnIndi : 23|2@0+ (1,0) [0|3] "" IVI,DataCenter
 SG_ TPMS_Res_Butt_Allow : 21|1@0+ (1,0) [0|1] "" IVI
 SG_ AutoLTips : 19|2@0+ (1,0) [0|3] "" IVI
 SG_ TPMS_Cali_Butt_Allow : 20|1@0+ (1,0) [0|1] "" IVI
 SG_ CWheelTips : 17|2@0+ (1,0) [0|3] "" IVI
 SG_ LRWheelTemp : 31|8@0+ (1,-40) [-40|215] "Deg^C" IVI
 SG_ RRWheelTemp : 39|8@0+ (1,-40) [-40|215] "Deg^C" IVI
 SG_ LFWheelTemp : 47|8@0+ (1,-40) [-40|215] "Deg^C" IVI
 SG_ RFWheelTemp : 55|8@0+ (1,-40) [-40|215] "Deg^C" IVI
 SG_ LRWheelPress : 63|8@0+ (1,0) [0|250] "" IVI,DataCenter
 SG_ RRWheelPress : 71|8@0+ (1,0) [0|250] "" IVI,DataCenter
 SG_ LFWheelPress : 79|8@0+ (1,0) [0|250] "" IVI,DataCenter
 SG_ RFWheelPress : 87|8@0+ (1,0) [0|250] "" IVI,DataCenter
 SG_ LRWheelDebug : 103|1@0+ (1,0) [0|1] "" IVI
 SG_ RRWheelDebug : 102|1@0+ (1,0) [0|1] "" IVI
 SG_ LFWheelDebug : 101|1@0+ (1,0) [0|1] "" IVI
 SG_ RFWheelDebug : 100|1@0+ (1,0) [0|1] "" IVI
 SG_ LRBatWarn : 99|1@0+ (1,0) [0|1] "" IVI,DataCenter
 SG_ RRBatWarn : 98|1@0+ (1,0) [0|1] "" IVI,DataCenter
 SG_ LFBatWarn : 97|1@0+ (1,0) [0|1] "" IVI,DataCenter
 SG_ RFBatWarn : 96|1@0+ (1,0) [0|1] "" IVI,DataCenter
 SG_ LRSensorFail : 111|1@0+ (1,0) [0|1] "" IVI,DataCenter
 SG_ RRSensorFail : 110|1@0+ (1,0) [0|1] "" IVI,DataCenter
 SG_ LFSensorFail : 109|1@0+ (1,0) [0|1] "" IVI,DataCenter
 SG_ RFSensorFail : 108|1@0+ (1,0) [0|1] "" IVI,DataCenter
 SG_ LRWheelTmpIndi : 107|1@0+ (1,0) [0|1] "" IVI
 SG_ RRWheelTmpIndi : 106|1@0+ (1,0) [0|1] "" IVI
 SG_ LFWheelTmpIndi : 105|1@0+ (1,0) [0|1] "" IVI
 SG_ RFWheelTmpIndi : 104|1@0+ (1,0) [0|1] "" IVI
 SG_ LRPressIndi : 119|2@0+ (1,0) [0|3] "" IVI,DataCenter
 SG_ RRPressIndi : 117|2@0+ (1,0) [0|3] "" IVI,DataCenter
 SG_ LFPressIndi : 115|2@0+ (1,0) [0|3] "" IVI,DataCenter
 SG_ RFPressIndi : 113|2@0+ (1,0) [0|3] "" IVI,DataCenter
 SG_ RRWheelPSW : 127|8@0+ (1,0) [0|200] "" IVI,DataCenter
 SG_ RFWheelPSW : 135|8@0+ (1,0) [0|200] "" IVI,DataCenter
 SG_ LFWheelPSW : 143|8@0+ (1,0) [0|200] "" IVI,DataCenter
 SG_ LRWheelPSW : 151|8@0+ (1,0) [0|200] "" IVI,DataCenter
 SG_ LFWheelShield : 231|1@0+ (1,0) [0|1] "" IVI
 SG_ LRWheelShield : 230|1@0+ (1,0) [0|1] "" IVI
 SG_ RFWheelShield : 229|1@0+ (1,0) [0|1] "" IVI
 SG_ RRWheelShield : 228|1@0+ (1,0) [0|1] "" IVI
 SG_ FDC_BCM_AmbBrightSta_Sta : 158|7@0+ (1,0) [0|127] "%" IVI
 SG_ FDC_BCM_AmbColorSta_Sta : 165|6@0+ (1,0) [0|63] "" IVI
 SG_ FDC_BCM_AmbDimEN_Sta : 166|1@0+ (1,0) [0|1] "" IVI
 SG_ FDC_BCM_AmbFunEN_Sta : 167|1@0+ (1,0) [0|1] "" IVI
 SG_ FDC_BCM_AmbLinkDriSta_Sta : 171|1@0+ (1,0) [0|1] "" IVI
 SG_ FDC_BCM_AmbODAEN_Sta : 224|1@0+ (1,0) [0|1] "" IVI
 SG_ FDC_BCM_AmbPwrWarnEN_Sta : 225|1@0+ (1,0) [0|1] "" IVI
 SG_ FDC_BCM_AmbWelEN_Sta : 159|1@0+ (1,0) [0|1] "" IVI
 SG_ FDC_BCM_UserNow_Sta : 170|3@0+ (1,0) [0|7] "" IVI
 SG_ FDC_BCM_TurnSwTSetSta_Sta : 227|2@0+ (1,0) [0|3] "" IVI
 SG_ FDC_BCM_PTGOpenHeight_Sta : 174|3@0+ (1,0) [0|7] "" IVI
 SG_ FDC_BCM_LockAlarm_Cmd : 217|2@0+ (1,0) [0|2] "" IVI
 SG_ FDC_BCM_Acc1Sta_Sta : 183|2@0+ (1,0) [0|2] "" IVI
 SG_ FDC_BCM_Acc2Sta_Sta : 191|2@0+ (1,0) [0|2] "" IVI
 SG_ FDC_BCM_Acc3Sta_Sta : 199|2@0+ (1,0) [0|2] "" IVI
 SG_ FDC_BCM_Acc4Sta_Sta : 207|2@0+ (1,0) [0|2] "" IVI
 SG_ FDC_BCM_Acc5Sta_Sta : 215|2@0+ (1,0) [0|2] "" IVI
 SG_ FDC_BCM_Key1Acc_Sta : 178|3@0+ (1,0) [0|7] "" IVI
 SG_ FDC_BCM_Key2Acc_Sta : 181|3@0+ (1,0) [0|7] "" IVI
 SG_ FDC_BCM_Key3Acc_Sta : 186|3@0+ (1,0) [0|7] "" IVI
 SG_ FDC_BCM_Key4Acc_Sta : 189|3@0+ (1,0) [0|7] "" IVI
 SG_ FDC_BCM_Key5Acc_Sta : 194|3@0+ (1,0) [0|7] "" IVI
 SG_ FDC_BCM_Key6Acc_Sta : 197|3@0+ (1,0) [0|7] "" IVI
 SG_ FDC_BCM_Key7Acc_Sta : 202|3@0+ (1,0) [0|7] "" IVI
 SG_ FDC_BCM_Key8Acc_Sta : 205|3@0+ (1,0) [0|7] "" IVI
 SG_ FDC_BCM_Key9Acc_Sta : 210|3@0+ (1,0) [0|7] "" IVI
 SG_ FDC_BCM_Key10Acc_Sta : 213|3@0+ (1,0) [0|7] "" IVI
 SG_ FDC_BCM_FollowMeENFun_Sta : 218|1@0+ (1,0) [0|1] "" IVI
 SG_ FDC_BCM_RmLpModeENFun_Sta : 219|1@0+ (1,0) [0|1] "" IVI,HMI
 SG_ FDC_BCM_WalkInUnLkEnFun_Sta : 220|1@0+ (1,0) [0|1] "" IVI
 SG_ FDC_BCM_WalkOutLkEnFun_Sta : 221|1@0+ (1,0) [0|1] "" IVI
 SG_ FDC_SPTG_SPTGENFun_Sta : 222|1@0+ (1,0) [0|1] "" IVI
 SG_ FDC_DKC_DkeyShowIVI_Sta : 235|4@0+ (1,0) [0|15] "" IVI
 SG_ FDC_DKC_KeyMiss_Sta : 223|1@0+ (1,0) [0|1] "" IVI
 SG_ FDC_DKC_UIDLowPower_Sta : 236|1@0+ (1,0) [0|1] "" IVI
 SG_ FDC_FGS_AirInt_Sta : 247|2@0+ (1,0) [0|3] "" IVI
 SG_ FDC_FGS_FGSCh_Sta : 239|2@0+ (1,0) [0|3] "" IVI
 SG_ FDC_FGS_IONSW_Sta : 237|1@0+ (1,0) [0|1] "" IVI
 SG_ FDC_BCM_CLWinLockDr_Sta : 245|1@0+ (1,0) [0|1] "" IVI
 SG_ FDC_THCM_APTCWarning_Sta : 175|1@0+ (1,0) [0|1] "" IVI,DataCenter
 SG_ FDC_THCM_APTCForceOFF_Sta : 244|1@0+ (1,0) [0|1] "" IVI
 SG_ FDC_DKC_KeyNum_Sta : 243|4@0+ (1,0) [0|15] "" IVI
 SG_ FDC_DKC_KeyType_Sta : 255|2@0+ (1,0) [0|3] "" IVI
 SG_ FDC_THCM_AirIntZ3_Sta : 250|3@0+ (1,0) [0|7] "" IVI
 SG_ FDC_BCM_AutoLock_Sta : 252|1@0+ (1,0) [0|1] "" IVI
 SG_ FDC_BCM_AutoUnlock_Sta : 253|1@0+ (1,0) [0|1] "" IVI
 SG_ FDC_BCM_DSEATentryfset_Sta : 251|1@0+ (1,0) [0|1] "" IVI
 SG_ FDC_BCM_HBeamADB_Cmd : 95|2@0+ (1,0) [0|3] "" IVI

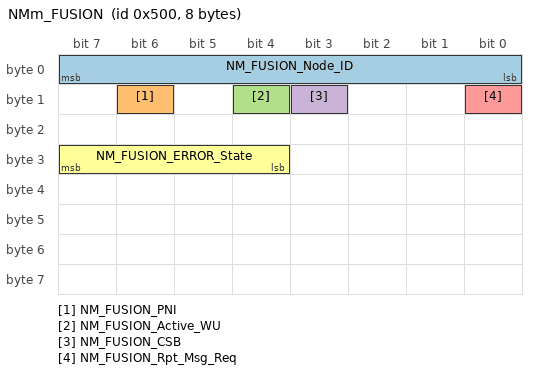
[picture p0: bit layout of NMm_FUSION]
BO_ 1280 NMm_FUSION: 8 FUSION
 SG_ NM_FUSION_Node_ID : 7|8@0+ (1,0) [0|127] "" IVI,HMI,Meter
 SG_ NM_FUSION_PNI : 14|1@0+ (1,0) [0|1] "" IVI,HMI,Meter
 SG_ NM_FUSION_Active_WU : 12|1@0+ (1,0) [0|1] "" IVI,HMI,Meter
 SG_ NM_FUSION_CSB : 11|1@0+ (1,0) [0|1] "" IVI,HMI,Meter
 SG_ NM_FUSION_Rpt_Msg_Req : 8|1@0+ (1,0) [0|1] "" IVI,HMI,Meter
 SG_ NM_FUSION_ERROR_State : 31|4@0+ (1,0) [0|8] "" IVI,HMI,Meter

BO_ 1666 DiagPhysReqToMeter: 8 FUSION
 SG_ DiagPhysReqToMeter : 7|64@0+ (1,0) [0|0] "" Meter

BO_ 1696 DiagPhysReqToIVI: 8 FUSION
 SG_ DiagPhysReqToIVI : 7|64@0+ (1,0) [0|0] "" IVI

BO_ 1714 DiagPhysReqToHMI: 64 FUSION
 SG_ DiagPhysReqToHMI : 7|64@0+ (1,0) [0|0] "" HMI

BO_ 2000 DiagFuncReqFT: 8 FUSION
 SG_ DiagFuncReqFT : 7|64@0+ (1,0) [0|0] "" IVI,HMI,Meter,WCM

BO_ 1080 FD2_OTA1: 12 FUSION
 SG_ OTA_Progress_Rate : 7|8@0+ (1,0) [0|102] "%" IVI,DataCenter
 SG_ OTA_DL_Available : 8|1@0+ (1,0) [0|1] "" IVI
 SG_ OTA_Mode : 9|1@0+ (1,0) [0|1] "" IVI
 SG_ OTA_Network_Type : 11|2@0+ (1,0) [0|3] "" IVI
 SG_ OTA_MDA_Status : 52|5@0+ (1,0) [0|14] "" IVI,DataCenter
 SG_ OTA_Updating_ECU_8bit : 23|8@0+ (1,0) [0|255] "" IVI,DataCenter
 SG_ OTA_Update_Available : 62|1@0+ (1,0) [0|1] "" IVI
 SG_ OTA_InVehicle_FW : 29|2@0+ (1,0) [0|2] "" IVI
 SG_ OTA_DL_Speed : 27|20@0+ (1,0) [0|1048575] "Kb/s" IVI
 SG_ OTA_TBOXResetReq : 30|1@0+ (1,0) [0|1] "" Vector__XXX
 SG_ OTA_Lock_Req : 31|1@0+ (1,0) [0|1] "" Vector__XXX
 SG_ OTA_Remained_Time : 58|11@0+ (10,0) [0|1081] "SECOND" IVI
 SG_ OTA_Permit_Agreed : 63|1@0+ (1,0) [0|1] "" IVI
 SG_ OTA_Debug_Code : 79|8@0+ (1,0) [0|65] "" IVI
 SG_ OTA_Emergency_Sta : 61|2@0+ (1,0) [0|3] "" IVI

BO_ 517 SRR1: 8 FUSION
 SG_ SRR1_Chksum : 7|8@0+ (1,0) [0|255] "" IVI
 SG_ SRR1_LifeCount : 11|4@0+ (1,0) [0|14] "" IVI
 SG_ SRR_ODA_Sta : 18|3@0+ (1,0) [0|7] "" IVI
 SG_ SRR_BSD_Sta : 26|3@0+ (1,0) [0|7] "" IVI
 SG_ SRR_RCTA_Sta : 30|3@0+ (1,0) [0|7] "" IVI
 SG_ SRR_ODA_WarnR : 33|2@0+ (1,0) [0|3] "" IVI
 SG_ SRR_ODA_WarnL : 35|2@0+ (1,0) [0|3] "" IVI
 SG_ SRR_ODA_SoundR : 36|1@0+ (1,0) [0|1] "" IVI
 SG_ SRR_ODA_SoundL : 37|1@0+ (1,0) [0|1] "" IVI
 SG_ SRR_ODA_Mute : 38|1@0+ (1,0) [0|1] "" IVI
 SG_ SRR_BSD_WarnR : 41|2@0+ (1,0) [0|3] "" IVI
 SG_ SRR_BSD_WarnL : 43|2@0+ (1,0) [0|3] "" IVI
 SG_ SRR_BSD_SoundR : 44|1@0+ (1,0) [0|1] "" IVI
 SG_ SRR_BSD_SoundL : 45|1@0+ (1,0) [0|1] "" IVI
 SG_ SRR_BSD_Mute : 46|1@0+ (1,0) [0|1] "" IVI
 SG_ SRR_RCTA_WarnR : 48|1@0+ (1,0) [0|1] "" IVI
 SG_ SRR_RCTA_WarnL : 49|1@0+ (1,0) [0|1] "" IVI

BO_ 965 ZONE_DR_Version: 48 FUSION
 SG_ ZONE_DR_SW_Var1 : 135|8@0+ (1,0) [0|255] "" IVI
 SG_ ZONE_DR_SW_Country2 : 127|8@0+ (1,0) [0|255] "" IVI
 SG_ ZONE_DR_SW_Country1 : 119|8@0+ (1,0) [0|255] "" IVI
 SG_ ZONE_DR_SW_Patch2 : 111|8@0+ (1,0) [0|255] "" IVI
 SG_ ZONE_DR_SW_Patch1 : 103|8@0+ (1,0) [0|255] "" IVI
 SG_ ZONE_DR_SW_Minor2 : 95|8@0+ (1,0) [0|255] "" IVI
 SG_ ZONE_DR_SW_Minor1 : 87|8@0+ (1,0) [0|255] "" IVI
 SG_ ZONE_DR_SW_Major2 : 79|8@0+ (1,0) [0|255] "" IVI
 SG_ ZONE_DR_SW_Major1 : 71|8@0+ (1,0) [0|255] "" IVI
 SG_ ZONE_DR_SW_Controller2 : 63|8@0+ (1,0) [0|255] "" IVI
 SG_ ZONE_DR_SW_Controller1 : 55|8@0+ (1,0) [0|255] "" IVI
 SG_ ZONE_DR_SW_CarModel3 : 47|8@0+ (1,0) [0|255] "" IVI
 SG_ ZONE_DR_SW_CarModel2 : 39|8@0+ (1,0) [0|255] "" IVI
 SG_ ZONE_DR_SW_CarModel1 : 31|8@0+ (1,0) [0|255] "" IVI
 SG_ ZONE_DR_HW_Ver3 : 23|8@0+ (1,0) [0|255] "" IVI
 SG_ ZONE_DR_HW_Ver2 : 15|8@0+ (1,0) [0|255] "" IVI
 SG_ ZONE_DR_HW_Ver1 : 7|8@0+ (1,0) [0|255] "" IVI
 SG_ ZONE_DR_SW_dash1 : 191|8@0+ (1,0) [0|255] "" IVI
 SG_ ZONE_DR_SW_change1 : 199|8@0+ (1,0) [0|255] "" IVI
 SG_ ZONE_DR_SW_change2 : 207|8@0+ (1,0) [0|255] "" IVI
 SG_ ZONE_DR_SW_dash2 : 215|8@0+ (1,0) [0|255] "" IVI
 SG_ ZONE_DR_SW_SHA1 : 223|8@0+ (1,0) [0|255] "" IVI
 SG_ ZONE_DR_SW_SHA2 : 231|8@0+ (1,0) [0|255] "" IVI
 SG_ ZONE_DR_SW_SHA3 : 239|8@0+ (1,0) [0|255] "" IVI
 SG_ ZONE_DR_SW_SHA4 : 247|8@0+ (1,0) [0|255] "" IVI
 SG_ ZONE_DR_SW_SHA5 : 255|8@0+ (1,0) [0|255] "" IVI
 SG_ ZONE_DR_SW_SHA6 : 263|8@0+ (1,0) [0|255] "" IVI
 SG_ ZONE_DR_SW_SHA7 : 271|8@0+ (1,0) [0|255] "" IVI
 SG_ ZONE_DR_SW_SHA8 : 279|8@0+ (1,0) [0|255] "" IVI
 SG_ ZONE_DR_SW_Var5 : 183|8@0+ (1,0) [0|255] "" IVI
 SG_ ZONE_DR_SW_Var4 : 175|8@0+ (1,0) [0|255] "" IVI
 SG_ ZONE_DR_SW_Var3 : 167|8@0+ (1,0) [0|255] "" IVI
 SG_ ZONE_DR_SW_Var2 : 159|8@0+ (1,0) [0|255] "" IVI
 SG_ ZONE_DR_SW_ECUGen2 : 151|8@0+ (1,0) [0|255] "" IVI
 SG_ ZONE_DR_SW_ECUGen1 : 143|8@0+ (1,0) [0|255] "" IVI

CM_ SG_ 279 CreepSW_Sta "creep switch state";
CM_ SG_ 279 EngageP_Fail "engage P gear failure";
CM_ SG_ 279 DisengageP_Fail "disengage P gear failure";
CM_ SG_ 279 FalseNPrevent_Sta "False N prevention state";
CM_ SG_ 279 DynoModeStaChk "Dyno mode state check";
CM_ SG_ 279 CoastDwModeStaChk "Coastdown mode state check";
CM_ SG_ 279 DemoModeStaChk "Demo mode state check";
CM_ SG_ 279 MSA_Crl_Sta "MSA Status";
CM_ SG_ 279 CC_Crl_Sta "Cruise Control Status";
CM_ SG_ 279 LVChrgFuncStaChk "Silent charging function state check";
CM_ SG_ 279 ShiftGearPosn "EV Selector Position Status/ Selector Position Status Signal Failure";
CM_ SG_ 279 PwrSta "Vehicle Power Status";
CM_ SG_ 279 XWDMode "Driving Wheel Selection Mode (RWD/FWD/AWD)";
CM_ SG_ 279 CCU_ACLampSts "Climate AC lamp state";
CM_ SG_ 279 CCU_Dispaly_Request "Air Conditioner display reuqest trigger";
CM_ SG_ 279 CCU_EcoSts "Economic mode status";
CM_ SG_ 279 CCU_AutoMidLampSts "Climate air conditionning middle left automatic mode lamp state";
CM_ SG_ 279 CCU_AutoLampSts "Climate air conditionning Front  automatic mode lamp state";
CM_ SG_ 279 CCU_ACMaxLampSts "Climate AC Max lamp state";
CM_ SG_ 279 CCU_RrOnOffLampSts "Rear Climate On Off lamp state";
CM_ SG_ 279 sigWindDirZon1St "Feedback: WInd DirectionZone 1. 
Feed, Body, WIndscreen and/or Auto";
CM_ SG_ 279 CCU_FrtOnOffLampSts "Front Climate On Off lamp state";
CM_ SG_ 279 sigWindDirZon3St "Feedback: WInd DirectionZone 3. 
Feed, Body and/or Auto";
CM_ SG_ 279 sigAirIntenZon1St "Feedback FAN Level/Air Intensirty : 0-Max or Auto for zone 1";
CM_ SG_ 279 sigAirIntenZon3St "Feedback FAN Level/Air Intensirty : 0-Max or Auto for zone 3";
CM_ SG_ 279 CCU_SyncLampSts "Climate SYNC lamp state";
CM_ SG_ 279 sigDfrstSt "Defrost Status in the HVAC (ON / AUTO)";
CM_ SG_ 279 sigSetTempZon3St "Feedback: Temperature set in the HVAC for Zone 3";
CM_ SG_ 279 sigRecircSt "Recirculation Status in the HVAC (Fre/Rec/Auto)";
CM_ SG_ 279 sigHvacSt "Status of the HVAC (ON / OFF)";
CM_ SG_ 279 sigSetTempZon2St "Feedback: Temperature set in the HVAC for Zone 2";
CM_ SG_ 279 VCUBrkSWSta "VCU brake SW state";
CM_ SG_ 279 sigSetTempZon1St "Feedback: Temperature set in the HVAC for Zone 1";
CM_ SG_ 279 sigCbnAirT "Cabin air temperature";
CM_ SG_ 279 sigAmbAirT "Environment temperature (outside ambient vehicle temperature)";
CM_ SG_ 279 FD_AGS_Cmd "Fusion Domain AGS Position Request";
CM_ SG_ 279 SysPwrSta "System power mode";
CM_ SG_ 279 MCUActDisFail "MCU active discharge fail";
CM_ SG_ 279 PwrStaONTOIVIPopReq "Power state ON timeout IVI popup";
CM_ SG_ 279 VCUFLDoorSta "VCU FL door state";
CM_ SG_ 279 VCUFRDoorSta "VCU FR door state";
CM_ SG_ 279 VCURLDoorSta "VCU RL door state";
CM_ SG_ 279 VCURRDoorSta "VCU RR door state";
CM_ SG_ 279 HVRlyOpFail "HV relay opend fail";
CM_ SG_ 279 SysAllowReadySta "System allow  to ready state";
CM_ SG_ 279 PwrStaONTOIVIPopT "Count down time value for power state ON timeout IVI popup";
CM_ SG_ 279 Req_V2LSwOn "FD asks IVI popup wording for SW on.";
CM_ SG_ 279 Req_V2L_IVI_Popup "FD asks IVI popup wording for V2L fault.";
CM_ SG_ 279 MeterIndSpeed_raw32 "Meter Speed (if IVI2 Distance_unit = 0x0, then UNIT = KPH, else UNIT = MPH)";
CM_ SG_ 279 DISC_Sta "DISC States";
CM_ SG_ 279 DISC_ButtSta "DISC button States ON/OFF";
CM_ SG_ 279 CCMSA_SpdWar "CC/MSA downslope overspeed warning";
CM_ SG_ 279 ActAPSPosn "Accelerator Actual Position";
CM_ SG_ 279 VCUHoodSWSta "VCU hood SW state";
CM_ SG_ 279 VCUTailgateSWSta "VCU Tailgate SW state";
CM_ SG_ 279 FD_EPB_Error "EPB_Error by FD";
CM_ SG_ 279 FD_Park_Brake_Warning "Park_Brake_Warning by FD";
CM_ SG_ 279 FD_TCS_Indicator "TCS_Indicator by FD";
CM_ SG_ 279 FD_ABS_Warning "ABS_Warning by FD";
CM_ SG_ 279 FD_Steering_Warning "Steering_Warning by FD";
CM_ SG_ 279 FD_HV_Battery_Fault "HV_Battery_Fault by FD";
CM_ SG_ 279 FD_EDrive_System "EDrive_System by FD";
CM_ SG_ 279 FD_Battery_Charge_Warning "Battery_Charge_Warning by FD";
CM_ SG_ 279 FD_Power_limitation "Power_limitation by FD";
CM_ SG_ 279 FD_Telltale_Fail "Telltaile function fail flag by FD";
CM_ SG_ 279 FeatSetSpdFinal_raw32 "Final Feature Set Speed  (if IVI2 Distance_unit = 0x0, then UNIT = KPH, else UNIT = MPH)";
CM_ SG_ 279 Eng_ActvDmpDisabSta "MCU active damping disable display status";
CM_ SG_ 279 Eng_CoastDwSta "coast down tq map display status";
CM_ SG_ 279 Eng_PwrLockSta "power lock display status";
CM_ SG_ 279 EDriveSysErr_AccPedalErr "EDrive system acceleration pedal error";
CM_ SG_ 279 EDriveSysErr_MCUErr "EDrive system MCU error";
CM_ SG_ 279 EDriveSysErr_ShifterErr "EDrive system Shifter error";
CM_ SG_ 279 EDriveSysErr_VCUErr "EDrive system Fusion VCU error";
CM_ SG_ 279 Eng_AGSCloseSta "AGS close display status";
CM_ SG_ 279 Dimmer "Dimmer";
CM_ SG_ 279 VehMalfunLevel "Vehicle malfunction level";
CM_ SG_ 279 AntitheftSta "Anti-theft Status";
CM_ SG_ 279 Dr_SeatSta "Driver seat switch state";
CM_ SG_ 279 EVDriveMode "Driving Mode";
CM_ SG_ 279 AllDoorSW "All Door Switch";
CM_ SG_ 279 BCM_DoorLock_Sta "BCM Unlock Single Door Setting";
CM_ SG_ 279 BrakeLamp "BrakeLamp";
CM_ SG_ 279 DoorLockIND "Door Lock Indicator";
CM_ SG_ 279 DrDoorSW "Driver Side Door Switch";
CM_ SG_ 279 FollowMe "Follow Me Home Signal";
CM_ SG_ 279 Fr_FogLamp "Front Fog Lamp";
CM_ SG_ 279 HazardSW "Hazard SW";
CM_ SG_ 279 HoodSW "Hood Switch";
CM_ SG_ 279 HVSysErr_IsolationErr "HV isolation error";
CM_ SG_ 279 HVSysErr_PackErr "HV battery pack error";
CM_ SG_ 279 HVSysErr_RelayErr "HV battery relay error";
CM_ SG_ 279 H_Beam "High Beam";
CM_ SG_ 279 LBSD "Left BSD";
CM_ SG_ 279 LDRL "Left DRL";
CM_ SG_ 279 LimphomeAct "Limp-home mode active";
CM_ SG_ 279 LockSetting "BCM Unlock Single Door Setting";
CM_ SG_ 279 LTurnLP "Left Turn Lamp";
CM_ SG_ 279 LVSysErr_PwrOutpErr "LV power output error";
CM_ SG_ 279 L_Beam "Low Beam";
CM_ SG_ 279 PAS_Sta_F_Sys "PBS_SYS_FAIL";
CM_ SG_ 279 PosLamp "PositionLamp";
CM_ SG_ 279 PsDoorSW "Passenger Side Door Switch";
CM_ SG_ 279 PwrStaErr "Power state error";
CM_ SG_ 279 RBSD "Right BSD";
CM_ SG_ 279 RDRL "Right DRL";
CM_ SG_ 279 ReverseLamp "ReverseLamp";
CM_ SG_ 279 RLDoorSW "Rear Left Door Switch";
CM_ SG_ 279 RRDoorSW "Rear Right Door Switch";
CM_ SG_ 279 Rr_Defog "Rear Defog";
CM_ SG_ 279 Rr_FogLamp "Rear Fog Lamp";
CM_ SG_ 279 RTurnLP "Right Turn Lamp";
CM_ SG_ 279 Tailgate_SW "Tailgate Switch";
CM_ SG_ 279 FD_EBMErrSta "EBM Error Status by FD";
CM_ SG_ 279 APMDoorControlSta "APM Door Control Function Status
FDC BCM Tx";
CM_ SG_ 279 Req_Internal_V2L_Status_Lamp "FD_V2L sends Status Lamp request of Internal V2L";
CM_ SG_ 279 VCU_OPDHold "One-pedal Brake Hold";
CM_ SG_ 279 DimmerEN "Dimmer Enable";
CM_ SG_ 279 FDC_VCU_PwrSaveReq_Cmd "VCU power save request";
CM_ SG_ 279 FDC_THCM_LEVentY_Sta "Y Status of Electric Vent on LH";
CM_ SG_ 279 FDC_THCM_REVentY_Sta "Y Status of Electric Vent on RH";
CM_ SG_ 279 FDC_THCM_CLEVentY_Sta "Y Status of Electric Vent on CTR-LH";
CM_ SG_ 279 FDC_THCM_CREVentY_Sta "Y Status of Electric Vent on CTR-RH";
CM_ SG_ 279 FDC_THCM_LEVentZ_Sta "Z Status of Electric Vent on LH";
CM_ SG_ 279 FDC_THCM_REVentZ_Sta "Z Status of Electric Vent on RH";
CM_ SG_ 279 FDC_THCM_CLEVentZ_Sta "Z Status of Electric Vent on CTR-LH";
CM_ SG_ 279 FDC_THCM_CREVentZ_Sta "Z Status of Electric Vent on CTR-RH";
CM_ SG_ 279 FDC_THCM_LEVentMode_Sta "Electric Vent Mode on Left Side";
CM_ SG_ 279 FDC_THCM_REVentMode_Sta "Electric Vent Mode on Right Side";
CM_ SG_ 279 FDC_THCM_LVent_Sta "LH Vent on off";
CM_ SG_ 279 FDC_THCM_CLVent_Sta "CTR-LH Vent on off";
CM_ SG_ 279 FDC_THCM_RVent_Sta "RH Vent on off";
CM_ SG_ 279 FDC_THCM_CRVent_Sta "CTR-RH Vent on off";
CM_ SG_ 279 LVSilentChrgSta "LV Silent Chrge State";
CM_ SG_ 279 FDC_THCM_PreWPTCHeat_Sta "WPTC PreHeat State";
CM_ SG_ 279 FDC_RAPS_ErrWarn_Sta "RAPS error warn status";
CM_ SG_ 279 FDC_V2L_IVIV2LDischarg_Cmd "Request IVI report V2L discharg";
CM_ SG_ 279 FDC_BCM_HMIKey1Func_Sta "HMI Key 1 Setting Function";
CM_ SG_ 279 FDC_BCM_HMIKey2Func_Sta "HMI Key 2 Setting Function";
CM_ SG_ 279 FDC_BCM_HMIKey3Func_Sta "HMI Key 3 Setting Function";
CM_ SG_ 279 FDC_BCM_HMIKey4Func_Sta "HMI Key 4 Setting Function";
CM_ SG_ 279 FDC_BCM_HMIKey5Func_Sta "HMI Key 5 Setting Function";
CM_ SG_ 279 FDC_BCM_HMIKey6Func_Sta "HMI Key 6 Setting Function";
CM_ SG_ 279 FDC_BCM_HMIKey7Func_Sta "HMI Key 7 Setting Function";
CM_ SG_ 279 FDC_BCM_HMIKey8Func_Sta "HMI Key 8 Setting Function";
CM_ SG_ 279 LVSilentChrgReq "LV Silent Chrge Request";
CM_ SG_ 279 FDC_BCM_AutoWipHSpdEN_Sta "Front Wiper Auto High Speed Enable Status";
CM_ SG_ 279 FDC_VCU_LVChrgFreq_Sta "LV charge frequently level";
CM_ SG_ 279 FDC_VCU_TrailerDisOPD_Sta "Trailer mode disable OPD popup";
CM_ SG_ 279 FDC_VCU_LVStaTooLow_Sta "LV state too low flag";
CM_ SG_ 279 FDC_VCU_LVStaDropQuick_Sta "LV state drop quickly flag";
CM_ SG_ 435 VehSpeed "Vehicle Speed";
CM_ SG_ 435 LF_WhlRotDir "Left Front Wheel Rotation Direction";
CM_ SG_ 435 RF_WhlRotDir "Right Front Wheel Rotation Direction";
CM_ SG_ 435 RF_PulseCount "Right Front Wheel Pulse Counter";
CM_ SG_ 435 RF_PulseCount_V "Right Front Wheel Pulse Counter Validity";
CM_ SG_ 435 LF_PulseCount_V "Left Front Wheel Pulse Counter Validity";
CM_ SG_ 435 LF_PulseCount "Left Front Wheel Pulse Counter";
CM_ SG_ 435 RR_PulseCount_V "Right Rear Wheel Pulse Counter Validity";
CM_ SG_ 435 RR_WhlRotDir "Right Rear Wheel Rotation Direction";
CM_ SG_ 435 RR_PulseCount "Right Rear Wheel Pulse Counter";
CM_ SG_ 435 LR_PulseCount_V "Left Rear Wheel Pulse Counter Validity";
CM_ SG_ 435 LR_WhlRotDir "Left Rear Wheel Rotation Direction";
CM_ SG_ 435 LR_PulseCount "Left Rear Wheel Pulse Counter";
CM_ SG_ 435 ESC_BeepReq "ESC Beep Sound Request";
CM_ SG_ 435 ESC_OFF_Status "Electronic Stability Control OFF Status";
CM_ SG_ 435 HDD_Failed "Hydraulic Dynamic Deceleration Failed";
CM_ SG_ 435 AVH_Failed "Auto Hold Failed";
CM_ SG_ 435 HSA_Failed "Hill Start Assist Failed";
CM_ SG_ 435 PBA_Failed "Panic Brake Assist Failed";
CM_ SG_ 435 HBB_Failed "Hydraulic Brake Boost Failed";
CM_ SG_ 435 ESC_Failed "Electronic Stability Control Failed";
CM_ SG_ 435 TCS_Failed "Traction Control System Failed";
CM_ SG_ 435 ABS_Failed "Antilock Brake System Failed";
CM_ SG_ 435 EBD_Failed "EBD System Failed";
CM_ SG_ 435 HDD_Active "Hydraulic Dynamic Deceleration Active";
CM_ SG_ 435 ESS_Active "Emergency Stop Signaling Active";
CM_ SG_ 435 BTCS_Active "Brake Traction Control System Active";
CM_ SG_ 435 Amber_WnlmpSta "Amber Warning Lamp Status";
CM_ SG_ 435 AVH_Active "Auto Hold Active";
CM_ SG_ 435 HSA_Active "Hill Start Assist Active";
CM_ SG_ 435 PBA_Active "Panic Brake Assist Active";
CM_ SG_ 435 HBB_Active "Hydraulic Brake Boost Active";
CM_ SG_ 435 ABS_Active "Antilock Brake System Active";
CM_ SG_ 435 ESC_WnlmpSta "ESC Warning Lamp Status";
CM_ SG_ 435 ESC_Off_lmpSta "ESC Off Warning Lamp Status";
CM_ SG_ 435 ABS_WnlmpSta "ABS Warning Lamp Status";
CM_ SG_ 435 Red_WnlmpSta "Red Warning Lamp Status";
CM_ SG_ 435 eBST_BeepReq "eBST Beep Sound Request";
CM_ SG_ 435 eBST_RedWnlmpSta "eBST Red Warning Lamp Status";
CM_ SG_ 435 eBST_AmberWnlmpSta "eBST Amber Warning Lamp Status";
CM_ SG_ 435 LowBrakeFluid_Sta "Low Brake Fluid Status";
CM_ SG_ 435 HVBattVolt "HV battery pack Volt";
CM_ SG_ 435 DCDCAuxCur "DC/DC Output Current";
CM_ SG_ 435 HVBattCurr "HV battery pack current";
CM_ SG_ 435 DCDCAuxVolt "DC/DC Output Volt";
CM_ SG_ 435 Meter_Ind_VehSpeed "Meter Indicated Vehicle Speed";
CM_ SG_ 435 ESC_ADAS_Sta "Resopnse Status to ADAS Request";
CM_ SG_ 435 AEBAvail "AEB Availability";
CM_ SG_ 435 BrkDiscTempSta "Brake Disc Temperature Status";
CM_ SG_ 435 BrkSw_Sta "Brake switch signal status";
CM_ SG_ 435 BrkSw_V "Brake switch signal Vaild";
CM_ SG_ 435 EBMErrSta "EBM Error Status";
CM_ SG_ 435 EBMRLampSta "EBM Red Lamp Status";
CM_ SG_ 435 LADB_Hibeam_Indication "LADB_Hibeam_Indication";
CM_ SG_ 435 LADB_Operation_Status "LADB_Operation_Status";
CM_ SG_ 435 LADB_Warning "LADB_Warning";
CM_ SG_ 435 LLB_Warning "LLB_Warning";
CM_ SG_ 435 LAHB_Warning "LAHB_Warning";
CM_ SG_ 435 FLTurn_Light_Warning "FLTurn Light_Warning";
CM_ SG_ 435 LDRL_Warning "LDRL_Warning";
CM_ SG_ 435 Lposition_Lamp_Warning "LPosition Lamp_Warning";
CM_ SG_ 435 RADB_Hibeam_Indication "RADB_Hibeam_Indication";
CM_ SG_ 435 RADB_Operation_Status "RADB_Operation_Status";
CM_ SG_ 435 RADB_Warning "RADB_Warning";
CM_ SG_ 435 RLB_Warning "RLB_Warning";
CM_ SG_ 435 RAHB_Warning "RAHB_Warning";
CM_ SG_ 435 FRTurn_Light_Warning "FRTurn Light_Warning";
CM_ SG_ 435 RDRL_Warning "RDRL_Warning";
CM_ SG_ 435 Rposition_Lamp_Warning "RPosition Lamp_Warning";
CM_ SG_ 435 SAS_Angle "Absoluted Steering Wheel Angle
(Positive value is clockwise.
When not being calibrated, invalid = 'FFFFh')";
CM_ SG_ 435 CrashOutputSts "Crash Output Status";
CM_ SG_ 435 EpasFailed "Epas Failed";
CM_ SG_ 435 AirBagFailCmd "Airbag system lamp status";
CM_ SG_ 435 DriverSeatBeltCmd "Driver Seat Belt lamp status";
CM_ SG_ 435 DrPMMLVOutPErrLmp "PMM LV output error lamp request";
CM_ SG_ 435 DrPMMSysErrLmp "PMM system error lamp request";
CM_ SG_ 435 DrSCPSysErrLmp "SCP system error lamp  request ";
CM_ SG_ 435 FireDetErr "Fire detector";
CM_ SG_ 435 FrPMMLimpHomeActReq "PMM Limp Home act request";
CM_ SG_ 435 HVBattErr "Battery error (HVBattFault)";
CM_ SG_ 435 PABSwitchCmd "PAB Switch lamp status";
CM_ SG_ 435 PsngrSeatBeltCmd "Passenger Seat Belt lamp status";
CM_ SG_ 435 RCenterSeatBeltCmd "Rear center seat belt lamp status";
CM_ SG_ 435 RDriverSeatBeltCmd "Rear driver seat belt lamp status";
CM_ SG_ 435 RPsngrSeatBeltCmd "Rear passenger seat belt lamp status";
CM_ SG_ 435 SAS_V "Steering Wheel Angle validity ( Status of Senosr Failure)";
CM_ SG_ 435 TLHPsngrSeatBeltCmd "Third LH seatbelt lamp status";
CM_ SG_ 435 TRHPsngrSeatBeltCmd "Third RH seatbelt lamp status";
CM_ SG_ 435 ABM_Passenger_ODS_Sta "Passenger ODS  status on CAN Bus";
CM_ SG_ 435 ABM_RearPassengerLH_ODS_Sta "Rear Left Passenger ODS  status on CAN Bus";
CM_ SG_ 435 ABM_RearPassengerCTR_ODS_Sta "Rear Middle Passenger ODS  status on CAN Bus";
CM_ SG_ 435 ABM_RearPassengerRH_ODS_Sta "Rear Right Passenger ODS  status on CAN Bus";
CM_ SG_ 435 LADBErr "Left ADB Error";
CM_ SG_ 435 LH_BeamErr "Left High Beam Error";
CM_ SG_ 435 LL_BeamErr "Left Low Beam Error";
CM_ SG_ 435 RADBErr "Right ADB Error";
CM_ SG_ 435 RH_BeamErr "Right High Beam Error";
CM_ SG_ 435 RL_BeamErr "Right Low Beam Error";
CM_ SG_ 435 RLTurnLPErr "Rear Left Turn Lamp Err";
CM_ SG_ 435 RRTurnLPErr "Rear Right Turn Lamp Err";
CM_ SG_ 435 FLTurnLPErr "Front Left Turn Lamp Error";
CM_ SG_ 435 FRTurnLPErr "Front Right Turn Lamp Error";
CM_ SG_ 372 ADAS_VehSpdLim "Vehicle Speed Limit(if Distance_unit = 0x0, then UNIT = km/h, else  UNIT = mph)";
CM_ SG_ 372 ADAS_LFC_Warn_Sound "LFC Warning Sound";
CM_ SG_ 372 ACC_ObjDist "Object distance";
CM_ SG_ 372 ACC_ObjRelSpd "Object relative speed";
CM_ SG_ 372 ADAS_CAM_SpdLim "ADAS Camera Speed Limitation";
CM_ SG_ 372 ADAS_SLIF_SpdLim "ADAS SLIF Speed Limitation";
CM_ SG_ 372 ADAS_ISA_Sta "ISA Status";
CM_ SG_ 372 ADAS_WarningMsg "ADAS Warning Message";
CM_ SG_ 372 ACC_ObjDstLvl "Object distance level (lvl.1 ~ lvl.4)";
CM_ SG_ 372 ADAS_ACC_Sta "ACC Status";
CM_ SG_ 372 ADAS_AEBReq "AEB Request";
CM_ SG_ 372 ADAS_AEB_Sta "AEB Status";
CM_ SG_ 372 ADAS_FCW_Sta "FCW Status";
CM_ SG_ 372 ADAS_LaneModeL "Left Lane Mode";
CM_ SG_ 372 ADAS_LaneModeR "Right Lane Mode";
CM_ SG_ 372 ADAS_LDW_Sta "LDW Status";
CM_ SG_ 372 ADAS_LFC_Sta "LFC Status";
CM_ SG_ 372 ADAS_LKA_Sta "LKA Status";
CM_ SG_ 372 ADAS_SLIF_Sta "SLIF Status";
CM_ SG_ 372 ADAS_LFC_Hands_Off_Warning "LFC Hands-Off Warning";
CM_ SG_ 372 ACC_TakeoverReq "ACC takeover request";
CM_ SG_ 372 ActBrkLamp_Sta "Active Brake Lamp Status";
CM_ SG_ 372 ADAS_FCW_Mute "FCW Mute Status";
CM_ SG_ 372 ADAS_FltWrnReq "ADAS Fault Warning Request";
CM_ SG_ 372 ADAS_LDW_Mute "LDW Mute Status";
CM_ SG_ 372 LVDA_Mute_Sta "LVDA USM Setting";
CM_ SG_ 372 LKA_HOD_Display_Warning "LKA hands-off detection display warning signal";
CM_ SG_ 372 LKA_HOD_Sound_Warning "LKA hands-off detection sound warning signal";
CM_ SG_ 372 LVDA_ACCStatusInformation "ACC status information for LVDA";
CM_ SG_ 372 LVDA_Disabled "LVDA_Disabled";
CM_ SG_ 372 LVDA_Failinfo "LVDA Failinfo";
CM_ SG_ 372 LVDA_Warning "LVDA Warning";
CM_ SG_ 372 ISA_WarningMsg "ISA Warning Message";
CM_ SG_ 372 ForceLowBeam "Force Low Beam";
CM_ SG_ 372 CameraBlockage "Camera Blockage";
CM_ SG_ 372 HazardWarningReq "Hazard Warning Request";
CM_ SG_ 372 LeftTurnLightReq "Left Turning Light Request";
CM_ SG_ 372 Target_Type "Target Type";
CM_ SG_ 372 RightTurnLightReq "Right Turning Light Request";
CM_ SG_ 372 ADAS_FCW_Sensitivity "ADAS FCW Sensitivity";
CM_ SG_ 372 ADAS_LDW_Sensitivity "ADAS LDW Sensitivity";
CM_ SG_ 372 MCU_B_R_RealPwrKw_Sta "Rear Real Power_Kw";
CM_ SG_ 372 MCU_B_F_RealPwrKw_Sta "Front Real Power_Kw";
CM_ SG_ 372 HVBSOH "Battery SOH";
CM_ SG_ 372 FDC_BCM_TimeGapLevel_Sta "FDC BCM Time Gap Level";
CM_ SG_ 372 HVBPwrAvailChrg "HV battery available charging power";
CM_ SG_ 372 HVBPwrAvailChrg30 "HV battery available charging power 30 second";
CM_ SG_ 372 HVBPwrAvailChrg60 "HV battery available charging power 60 second";
CM_ SG_ 372 HVBFullChrgPwr "Full charge energy";
CM_ SG_ 450 HVBChrgErr "HVB Charge Error";
CM_ SG_ 450 V2LSta "V2L Adapter Status";
CM_ SG_ 450 DisChrgPlugErr "(Dis)Charger plug Error
0x0 : Normal
0x1 : plug-in incomplete
0x2 : (un)lock request invalid";
CM_ SG_ 450 ExtChrgSta "External charging status";
CM_ SG_ 450 ChrgPlugSta "Charger plug status";
CM_ SG_ 450 HVBOvrTempErr "Over temperature";
CM_ SG_ 450 OBC_AC_Cur_Lim "OBC AC Current Limit";
CM_ SG_ 450 HVBOvrTempWarn "Over temperature warn";
CM_ SG_ 450 Shifter_Fail_sta "Shifter fail status";
CM_ SG_ 450 Shifter_Handle_Cmd "Shifter Control Unit handle Command(PRND)";
CM_ SG_ 450 OBCACVoltInf "OBC AC Voltage Information";
CM_ SG_ 450 OBCFaultSta "OBC Fault Status";
CM_ SG_ 450 OBCACCurrInf "OBC AC Current Information";
CM_ SG_ 450 FrntPTCLeActHeatPwr "Front PTC Left Actual Heat Power";
CM_ SG_ 450 FrntPTCRiActHeatPwr "Front PTC Right Actual Heat Power";
CM_ SG_ 450 FrntPTCRearLeActHeatPwr "Frnt PTC Rear Left Actual Heat Power 0x00-0xC8:actual value; 0xC9-0xFE:Reserved";
CM_ SG_ 450 HVBContactorSta "HV battery contactor closed status";
CM_ SG_ 450 RLS_Lamp_Sta "Lampstatus";
CM_ SG_ 450 SWC_ACC_Sta "ACC Button Status";
CM_ SG_ 450 SWC_Down_Sta "DOWN Button Status";
CM_ SG_ 450 SWC_RegenUp "Regen Up";
CM_ SG_ 450 SWC_Left_Sta "Seek Backward track/radio";
CM_ SG_ 450 SWC_mode_Sta "Mode Button Status";
CM_ SG_ 450 SWC_Right_Sta "Seek Forward track/radio";
CM_ SG_ 450 SWC_Trip_Sta "Trip Button Status";
CM_ SG_ 450 SWC_Up_Sta "UP Button Status";
CM_ SG_ 450 SWC_LKA_Sta "LKA Button Status";
CM_ SG_ 450 SWC_Undefined_Sta "Undefined button Status";
CM_ SG_ 450 SWC_VR_Sta "VR Button Status";
CM_ SG_ 450 ChargeInletLockSta "Charge Inlet lock signal status";
CM_ SG_ 450 COMP_ActualPwr "COMP actual power";
CM_ SG_ 450 MainRlyPosSta "MainRlyPosSta";
CM_ SG_ 450 MainRlyNegSta "MainRlyNegSta";
CM_ SG_ 450 P_Dkey_Show_IVI "Digital key IVI Show";
CM_ SG_ 450 P_KeyMiss "DKC Key Miss";
CM_ SG_ 450 P_UID_LowPower "DKC UID low battery display";
CM_ SG_ 450 HVBMTempMax "HV battery maximum module temperature";
CM_ SG_ 450 TBOX_NET_SIG_STR "TBOX Network Signal Strength";
CM_ SG_ 450 TBOX_TEST_STATUS "TBOX Self Test Status";
CM_ SG_ 450 CbnPreACEnaReq "Cabin Preconditioning Air condition open enable";
CM_ SG_ 450 Re_Radio "Remote Radio on/off";
CM_ SG_ 450 TrailerModeSta "Trailer Mode Status";
CM_ SG_ 450 TrailerCheck "Trailer Mode Check";
CM_ SG_ 450 SWC_RegenDown "Regen Down";
CM_ SG_ 450 FDC_BCM_FWipSw_Sta "(FD_BCM combines the results of CAN CSW and LIN CSW)";
CM_ SG_ 450 FDC_BCM_TurnSw_Sta "CSW_TurnSw_Sta_CANbus (FD_BCM combines the results of CAN CSW and LIN CSW)";
CM_ SG_ 450 FDC_BCM_DimSw "CSW_DimSw (FD_BCM combines the results of CAN CSW and LIN CSW)";
CM_ SG_ 450 OBCACCSLimit "OBC AC Charger station Limit";
CM_ SG_ 450 ZFR_BCM_ChargerDoorSW_Sta "Charger Door Switch Status";
CM_ SG_ 450 DKC_KeyType_Sta "DKC current key type";
CM_ SG_ 450 DKC_KeyNum_Sta "DKC current key number";
CM_ SG_ 450 ZFR_EChrg_Active_Sta "EChrgPort active State";
CM_ SG_ 450 ZFR_EChrg_Sys_Sta "EChrgPort system State";
CM_ SG_ 450 ZFR_EChrg_OperationDeny_Cmd "EChrgPort operation deny";
CM_ SG_ 450 ZFR_EChrg_WashMode_Sta "EChrgPort Wash mode";
CM_ SG_ 450 EBMSta "EBM Status";
CM_ SG_ 528 USS_Sta_FCL "USS FCL Fault status";
CM_ SG_ 528 USS_Sta_FCR "USS FCR Fault status";
CM_ SG_ 528 USS_Sta_FLL "USS FLL Fault status";
CM_ SG_ 528 USS_Sta_FLR "USS FLR Fault status";
CM_ SG_ 528 USS_Sta_FML "USS FML Fault status";
CM_ SG_ 528 USS_Sta_FMR "USS FMR Fault status";
CM_ SG_ 528 USS_Sta_RCL "USS RCL Fault status";
CM_ SG_ 528 USS_Sta_RCR "USS RCR Fault status";
CM_ SG_ 528 USS_Sta_RLL "USS RLL Fault status";
CM_ SG_ 528 USS_Sta_RLR "USS RLR Fault status";
CM_ SG_ 528 USS_Sta_RML "USS RML Fault status";
CM_ SG_ 528 USS_Sta_RMR "USS RMR Fault status";
CM_ SG_ 528 PAS_A_FCR "To show the level of distance detected from sensor FCR";
CM_ SG_ 528 PAS_A_FML "To show the level of distance detected from sensor FML";
CM_ SG_ 528 PAS_A_FMR "To show the level of distance detected from sensor FMR";
CM_ SG_ 528 PAS_A_RCL "To show the level of distance detected from sensor RCL";
CM_ SG_ 528 PAS_A_RCR "To show the level of distance detected from sensor RCR";
CM_ SG_ 528 PAS_A_RML "To show the level of distance detected from sensor RML";
CM_ SG_ 528 PAS_A_RMR "To show the level of distance detected from sensor RMR";
CM_ SG_ 528 PAS_SNSR_Layout "To show the sensor layout";
CM_ SG_ 528 PAS_D_FCL "To show the distance detected from sensor FCL";
CM_ SG_ 528 PAS_D_FCR "To show the distance detected from sensor FCR";
CM_ SG_ 528 PAS_D_FML "To show the distance detected from sensor FML";
CM_ SG_ 528 PAS_D_FMR "To show the distance detected from sensor FMR";
CM_ SG_ 528 APS_ExitCondition "APS Disable Cause";
CM_ SG_ 528 APS_SW_Ver "APS Software Version Number";
CM_ SG_ 528 PAS_D_RCL "To show the distance detected from sensor RCL";
CM_ SG_ 528 PAS_D_RCR "To show the distance detected from sensor RCR";
CM_ SG_ 528 PAS_D_RML "To show the distance detected from sensor RML";
CM_ SG_ 528 PAS_D_RMR "To show the distance detected from sensor RMR";
CM_ SG_ 528 APS_RQ_Display "Request to show the APA operation";
CM_ SG_ 528 PAS_Chime "The types of chime for PSS system";
CM_ SG_ 528 PAS_A_FCL "To show the level of distance detected from sensor FCL";
CM_ SG_ 528 APS_Sta_System "The operation status of APA system";
CM_ SG_ 528 CAAS_Sta "The operation status of CAAS";
CM_ SG_ 528 FDC_VCU_RegenMode_Sta "Regen Mode";
CM_ SG_ 528 FDC_VMC_SpdCtrlMode_Sta "Speed Control Function Mode";
CM_ SG_ 528 FDC_VMC_SpdCtrl_Sta "Speed Control Function Status";
CM_ SG_ 528 FDC_VMC_SetSpd_Sta "speed setting under speed control function";
CM_ SG_ 528 FDC_VMC_SetSpdDisp_Sta "displayed set speed
if IVI2 Distance_unit = 0x0, then unit = kph, else unit = mph";
CM_ SG_ 528 VMC_VCU_CC_Crl_Sta "Cruise control control state";
CM_ SG_ 528 VMC_VCU_MSA_Crl_Sta "MSA control control state";
CM_ SG_ 528 FDC_VCU_RegenLimInd_Sta "Regen Temporary Limit Indicator";
CM_ SG_ 528 FDC_VCU_SmartEco_Sta "smart ECO mode VCU state";
CM_ SG_ 528 FDC_VCU_SmartEcoSpdLim_Sta "Speed limit during smart ECO";
CM_ SG_ 528 DISC_DISCTargetSpd "DISC Target Speed";
CM_ SG_ 528 FDC_VCU_SimSound_Cmd "Simulated Sound Command";
CM_ SG_ 823 ACChrgCurrDis "HVB AC charge current max display";
CM_ SG_ 823 RemainChrgTime "Remaining charge time";
CM_ SG_ 823 HVBChrgPwr "Total Charge kWh";
CM_ SG_ 823 HVBattSOCDis "HV battery pack Display SOC";
CM_ SG_ 823 HVBattSOC "HV battery pack SOC";
CM_ SG_ 823 Charge_Percent_Set "Charge_Percent_Set";
CM_ SG_ 823 TBOX_HW_VER "TBOX HW Ver., 4 byte ASCII Code";
CM_ SG_ 823 TBOX_SW_VER "TBOX SW Ver., 4 byte ASCII Code";
CM_ SG_ 823 Rr_MCU3_SW_Ver "Rear MCU Software version";
CM_ SG_ 823 Rr_MCU3_HW_Ver "Rear MCU Hardware version";
CM_ SG_ 823 Fr_MCU_SW_Ver "Front MCU Software version";
CM_ SG_ 823 Fr_MCU_HW_Ver "Front MCU Hardware version";
CM_ SG_ 823 Rr_MCU3_SW_Ver_Nidec "Rear MCU Software version from Nidec";
CM_ SG_ 823 Rr_MCU3_HW_Ver_Nidec "Rear MCU Hardware version from Nidec";
CM_ SG_ 823 PSEAT_SW_Ver "Passenger Seat Software Version Number";
CM_ SG_ 823 PSEAT_HW_Ver "Passenger Seat Hardware Version Number";
CM_ SG_ 823 Fr_MCU_SW_Ver_Nidec "Front MCU Software version from Nidec";
CM_ SG_ 823 Fr_MCU_HW_Ver_Nidec "Front MCU Hardware version from Nidec";
CM_ SG_ 823 DSEAT_SW_Ver "Driver Seat Software Version Number";
CM_ SG_ 823 DSEAT_HW_Ver "Driver Seat Hardware Version Number";
CM_ SG_ 823 PTG_HW_Ver "Power Tail Gate ECU Hardware Version";
CM_ SG_ 823 PTG_SW_Ver "Power Tail Gate ECU Software Version";
CM_ SG_ 823 HVBChrgPwrTotal "Total Charge kWh accumulation";
CM_ SG_ 823 HVBDrvPwrTotal "Total Discharge kWh accumulation";
CM_ SG_ 823 HVBDrvPwr "Total drive kWh";
CM_ SG_ 963 FUSION_SW_Var1 "software version car model variation 1";
CM_ SG_ 963 FUSION_SW_Country2 "software version country of target market character 2";
CM_ SG_ 963 FUSION_SW_Country1 "software version country of target market character 1";
CM_ SG_ 963 FUSION_SW_Patch2 "software version patch character 2";
CM_ SG_ 963 FUSION_SW_Patch1 "software version patch character 1";
CM_ SG_ 963 FUSION_SW_Minor2 "software version minor character 2";
CM_ SG_ 963 FUSION_SW_Minor1 "software version minor character 1";
CM_ SG_ 963 FUSION_SW_Major2 "software version major character 2";
CM_ SG_ 963 FUSION_SW_Major1 "software version major character 1";
CM_ SG_ 963 FUSION_SW_Controller2 "software version controller character 2";
CM_ SG_ 963 FUSION_SW_Controller1 "software version controller character 1";
CM_ SG_ 963 FUSION_SW_CarModel3 "software version car model character 3";
CM_ SG_ 963 FUSION_SW_CarModel2 "software version car model character 2";
CM_ SG_ 963 FUSION_SW_CarModel1 "software version car model character 1";
CM_ SG_ 963 FUSION_HW_Ver3 "hardware version character 3";
CM_ SG_ 963 FUSION_HW_Ver2 "hardware version character 2";
CM_ SG_ 963 FUSION_HW_Ver1 "hardware version character 1";
CM_ SG_ 963 FUSION_SW_dash1 "software version dash character 1";
CM_ SG_ 963 FUSION_SW_change1 "software version number of change 1";
CM_ SG_ 963 FUSION_SW_change2 "software version number of change 2";
CM_ SG_ 963 FUSION_SW_dash2 "software version dash character 2";
CM_ SG_ 963 FUSION_SW_SHA1 "software version SHA character 1";
CM_ SG_ 963 FUSION_SW_SHA2 "software version SHA character 2";
CM_ SG_ 963 FUSION_SW_SHA3 "software version SHA character 3";
CM_ SG_ 963 FUSION_SW_SHA4 "software version SHA character 4";
CM_ SG_ 963 FUSION_SW_SHA5 "software version SHA character 5";
CM_ SG_ 963 FUSION_SW_SHA6 "software version SHA character 6";
CM_ SG_ 963 FUSION_SW_SHA7 "software version SHA character 7";
CM_ SG_ 963 FUSION_SW_SHA8 "software version SHA character 8";
CM_ SG_ 963 FUSION_SW_Var5 "software version car model variation 5";
CM_ SG_ 963 FUSION_SW_Var4 "software version car model variation 4";
CM_ SG_ 963 FUSION_SW_Var3 "software version car model variation 3";
CM_ SG_ 963 FUSION_SW_Var2 "software version car model variation 2";
CM_ SG_ 963 FUSION_SW_ECUGen2 "ECU generation 2";
CM_ SG_ 963 FUSION_SW_ECUGen1 "ECU generation 1";
CM_ SG_ 1077 TPMSWarnIndi "TPMS Warning Indicator";
CM_ SG_ 1077 TPMS_Res_Butt_Allow "TPMS Reset Button Allowable";
CM_ SG_ 1077 AutoLTips "Auto location Tips";
CM_ SG_ 1077 TPMS_Cali_Butt_Allow "TPMS Tire calibrate Button Allowable";
CM_ SG_ 1077 CWheelTips "Calibrate Wheel Tips";
CM_ SG_ 1077 LRWheelTemp "Left_Rear_Temperature";
CM_ SG_ 1077 RRWheelTemp "Right_Rear_Temperature";
CM_ SG_ 1077 LFWheelTemp "Left_Forward Temperature";
CM_ SG_ 1077 RFWheelTemp "Right_Forward Temperature";
CM_ SG_ 1077 LRWheelPress "Left_Rear_Wheel Pressure";
CM_ SG_ 1077 RRWheelPress "Right_Rear_Wheel Pressure";
CM_ SG_ 1077 LFWheelPress "Left_Forward Wheel Pressure";
CM_ SG_ 1077 RFWheelPress "Right_Forward Wheel Pressure";
CM_ SG_ 1077 LRWheelDebug "Left_Rear_wheel debug";
CM_ SG_ 1077 RRWheelDebug "Right_Rear_wheel debug";
CM_ SG_ 1077 LFWheelDebug "Left_Forward wheel debug";
CM_ SG_ 1077 RFWheelDebug "Right_Forward wheel debug";
CM_ SG_ 1077 LRBatWarn "Left_Rear_Wheel Battery Warning";
CM_ SG_ 1077 RRBatWarn "Right_Rear_Wheel Battery Warning";
CM_ SG_ 1077 LFBatWarn "Left_Forward Wheel Battery Warning";
CM_ SG_ 1077 RFBatWarn "Right_Forward Wheel Battery Warning";
CM_ SG_ 1077 LRSensorFail "Left_Rear_Wheel Sensor Fail Indicator";
CM_ SG_ 1077 RRSensorFail "Right_Rear_Wheel Sensor Fail Indicator";
CM_ SG_ 1077 LFSensorFail "Left_Forward Wheel Sensor Fail Indicator";
CM_ SG_ 1077 RFSensorFail "Right_Forward Wheel Sensor Fail Indicator";
CM_ SG_ 1077 LRWheelTmpIndi "Left_Rear_Wheel Temperature Warning Indicator";
CM_ SG_ 1077 RRWheelTmpIndi "Right_Rear_Wheel Temperature Warning Indicator";
CM_ SG_ 1077 LFWheelTmpIndi "Left_Forward Wheel Temperature Warning Indicator";
CM_ SG_ 1077 RFWheelTmpIndi "Right_Forward Wheel Temperature Warning Indicator";
CM_ SG_ 1077 LRPressIndi "Left_Rear_Wheel Pressure Warning Indicator";
CM_ SG_ 1077 RRPressIndi "Right_Rear_Wheel Pressure Warning Indicator";
CM_ SG_ 1077 LFPressIndi "Left_Forward Wheel Pressure Warning Indicator";
CM_ SG_ 1077 RFPressIndi "Right_Forward Wheel Pressure Warning Indicator";
CM_ SG_ 1077 RRWheelPSW "Right_Rear_Wheel PressureSetWarm";
CM_ SG_ 1077 RFWheelPSW "Right_Forward Wheel PressureSetWarm";
CM_ SG_ 1077 LFWheelPSW "Left_Forward Wheel PressureSetWarm";
CM_ SG_ 1077 LRWheelPSW "Left_Rear_Wheel PressureSetWarm";
CM_ SG_ 1077 LFWheelShield "Left Front tire pressure and temperature data shielding";
CM_ SG_ 1077 LRWheelShield "Left Rear tire pressure and temperature data shielding";
CM_ SG_ 1077 RFWheelShield "Right Front tire pressure and temperature data shielding";
CM_ SG_ 1077 RRWheelShield "Right Rear tire pressure and temperature data shielding";
CM_ SG_ 1077 FDC_BCM_AmbBrightSta_Sta "Amblight Brightness by user setting";
CM_ SG_ 1077 FDC_BCM_AmbColorSta_Sta "Amblight Color by user setting";
CM_ SG_ 1077 FDC_BCM_AmbDimEN_Sta "Amblight DimInDark function enable status by user setting";
CM_ SG_ 1077 FDC_BCM_AmbFunEN_Sta "Amblight Function enable status by user setting";
CM_ SG_ 1077 FDC_BCM_AmbLinkDriSta_Sta "Amblight LINKtoDRIVE function enable status by user setting";
CM_ SG_ 1077 FDC_BCM_AmbODAEN_Sta "Amblight ODA&BSD warning function enable status by user setting";
CM_ SG_ 1077 FDC_BCM_AmbPwrWarnEN_Sta "Amblight Power Warning function enable status by user setting";
CM_ SG_ 1077 FDC_BCM_AmbWelEN_Sta "Amblight Welcome mode enable status by user setting";
CM_ SG_ 1077 FDC_BCM_UserNow_Sta "Current User Number";
CM_ SG_ 1077 FDC_BCM_TurnSwTSetSta_Sta "Turn Switch Time Set status";
CM_ SG_ 1077 FDC_BCM_PTGOpenHeight_Sta "PTG max open height";
CM_ SG_ 1077 FDC_BCM_LockAlarm_Cmd "Lock alarm command";
CM_ SG_ 1077 FDC_BCM_Acc1Sta_Sta "User 1 account status";
CM_ SG_ 1077 FDC_BCM_Acc2Sta_Sta "User 2 account status";
CM_ SG_ 1077 FDC_BCM_Acc3Sta_Sta "User 3 account status";
CM_ SG_ 1077 FDC_BCM_Acc4Sta_Sta "User 4 account status";
CM_ SG_ 1077 FDC_BCM_Acc5Sta_Sta "User 5 account status";
CM_ SG_ 1077 FDC_BCM_Key1Acc_Sta "Key 1 linked user number";
CM_ SG_ 1077 FDC_BCM_Key2Acc_Sta "Key 2 linked user number";
CM_ SG_ 1077 FDC_BCM_Key3Acc_Sta "Key 3 linked user number";
CM_ SG_ 1077 FDC_BCM_Key4Acc_Sta "Key 4 linked user number";
CM_ SG_ 1077 FDC_BCM_Key5Acc_Sta "Key 5 linked user number";
CM_ SG_ 1077 FDC_BCM_Key6Acc_Sta "Key 6 linked user number";
CM_ SG_ 1077 FDC_BCM_Key7Acc_Sta "Key 7 linked user number";
CM_ SG_ 1077 FDC_BCM_Key8Acc_Sta "Key 8 linked user number";
CM_ SG_ 1077 FDC_BCM_Key9Acc_Sta "Key 9 linked user number";
CM_ SG_ 1077 FDC_BCM_Key10Acc_Sta "Key 10 linked user number";
CM_ SG_ 1077 FDC_BCM_FollowMeENFun_Sta "FollowMeHome function status";
CM_ SG_ 1077 FDC_BCM_RmLpModeENFun_Sta "RoomLamp Mode function status";
CM_ SG_ 1077 FDC_BCM_WalkInUnLkEnFun_Sta "Walk In Unlock function status";
CM_ SG_ 1077 FDC_BCM_WalkOutLkEnFun_Sta "Walk Out Lock function status";
CM_ SG_ 1077 FDC_SPTG_SPTGENFun_Sta "SPTG function status";
CM_ SG_ 1077 FDC_DKC_DkeyShowIVI_Sta "Digital key IVI Show";
CM_ SG_ 1077 FDC_DKC_KeyMiss_Sta "DKC Key Miss";
CM_ SG_ 1077 FDC_DKC_UIDLowPower_Sta "DKC UID low battery display";
CM_ SG_ 1077 FDC_FGS_AirInt_Sta "FDC_FGS_AirInt_Sta";
CM_ SG_ 1077 FDC_FGS_FGSCh_Sta "FDC_FGS_FGSCh_Sta";
CM_ SG_ 1077 FDC_FGS_IONSW_Sta "FDC_FGS_IONSW_Sta";
CM_ SG_ 1077 FDC_BCM_CLWinLockDr_Sta "Close window after door locked function status";
CM_ SG_ 1077 FDC_THCM_APTCWarning_Sta "APTC Fail Warning";
CM_ SG_ 1077 FDC_THCM_APTCForceOFF_Sta "APTC Fault Force OFF";
CM_ SG_ 1077 FDC_DKC_KeyNum_Sta "DKC current key number";
CM_ SG_ 1077 FDC_DKC_KeyType_Sta "FDC DKC current key type";
CM_ SG_ 1077 FDC_THCM_AirIntZ3_Sta "Air Volume state in Zone 3";
CM_ SG_ 1077 FDC_BCM_AutoLock_Sta "Auto Speed Lock function enable status";
CM_ SG_ 1077 FDC_BCM_AutoUnlock_Sta "Auto Unlock function enable status";
CM_ SG_ 1077 FDC_BCM_DSEATentryfset_Sta "Driver Seat Entry on/off function status";
CM_ SG_ 1077 FDC_BCM_HBeamADB_Cmd "FDC_BCM_HBeamADB_Cmd";
CM_ SG_ 1280 NM_FUSION_Node_ID "Source Node Identifier";
CM_ SG_ 1280 NM_FUSION_PNI "Partial Network Information Bit (PNI)";
CM_ SG_ 1280 NM_FUSION_Active_WU "Active Wakeup Bit";
CM_ SG_ 1280 NM_FUSION_CSB "NM Coordinator Sleep Bit";
CM_ SG_ 1280 NM_FUSION_Rpt_Msg_Req "Repeat Message Request";
CM_ SG_ 1280 NM_FUSION_ERROR_State "Defined Error states of the CAN Controller";
CM_ SG_ 1666 DiagPhysReqToMeter "Diagnostic Physical Request to Meter";
CM_ SG_ 1696 DiagPhysReqToIVI "Diagnostic Physical Request to IVI";
CM_ SG_ 1714 DiagPhysReqToHMI "Diagnostic Physical Request to HMI";
CM_ SG_ 2000 DiagFuncReqFT "Diagnostic Functional Request from Tester";
CM_ SG_ 1080 OTA_Progress_Rate "MDA download or update progress rate";
CM_ SG_ 1080 OTA_DL_Available "Fusion MDA available for download";
CM_ SG_ 1080 OTA_Mode "Vehicel OTA mode Status";
CM_ SG_ 1080 OTA_Network_Type "Vehicle Network Type";
CM_ SG_ 1080 OTA_MDA_Status "Fusion Master OTA agent status";
CM_ SG_ 1080 OTA_Updating_ECU_8bit "Fusion MDA is updating ECU";
CM_ SG_ 1080 OTA_Update_Available "Fusion MDA available for update";
CM_ SG_ 1080 OTA_InVehicle_FW "In Vehicle Firmware Version Status";
CM_ SG_ 1080 OTA_DL_Speed "Firmware Package download speed";
CM_ SG_ 1080 OTA_TBOXResetReq "TBOX Reset Request";
CM_ SG_ 1080 OTA_Lock_Req "OTA Lock request to DKC";
CM_ SG_ 1080 OTA_Remained_Time "Download/Upgrade Estimated Time";
CM_ SG_ 1080 OTA_Permit_Agreed "Download/Upgrade coundition check result";
CM_ SG_ 1080 OTA_Debug_Code "OTA Error Code for Debug";
CM_ SG_ 1080 OTA_Emergency_Sta "Fusion emergency state";
CM_ SG_ 517 SRR1_Chksum "Checksum of SRR1(AUTOSAR E2E profile 1)

Polynomial 0x1D (x^8+x^4+x^3+x^2+1) Both start value and XOR value are 0x00.
";
CM_ SG_ 517 SRR1_LifeCount "SRR1 4-bit rolling counter
It starts counting from 0, ends at 14 and returns to zero (0~14).";
CM_ SG_ 517 SRR_ODA_Sta "Status of ODA";
CM_ SG_ 517 SRR_BSD_Sta "Status of BSD";
CM_ SG_ 517 SRR_RCTA_Sta "Status of RCTA";
CM_ SG_ 517 SRR_ODA_WarnR "ODA Warning Right";
CM_ SG_ 517 SRR_ODA_WarnL "ODA Warning Left";
CM_ SG_ 517 SRR_ODA_SoundR "ODA Sound Right";
CM_ SG_ 517 SRR_ODA_SoundL "ODA Sound Left";
CM_ SG_ 517 SRR_ODA_Mute "ODA Mute Status";
CM_ SG_ 517 SRR_BSD_WarnR "BSD Warning Right";
CM_ SG_ 517 SRR_BSD_WarnL "BSD Warning Left";
CM_ SG_ 517 SRR_BSD_SoundR "BSD Sound Right";
CM_ SG_ 517 SRR_BSD_SoundL "BSD Sound Left";
CM_ SG_ 517 SRR_BSD_Mute "BSD Mute status";
CM_ SG_ 517 SRR_RCTA_WarnR "RCTA Warning Right";
CM_ SG_ 517 SRR_RCTA_WarnL "RCTA Warning Left";
CM_ SG_ 965 ZONE_DR_SW_Var1 "software version car model variation 1";
CM_ SG_ 965 ZONE_DR_SW_Country2 "software version country of target market character 2";
CM_ SG_ 965 ZONE_DR_SW_Country1 "software version country of target market character 1";
CM_ SG_ 965 ZONE_DR_SW_Patch2 "software version patch character 2";
CM_ SG_ 965 ZONE_DR_SW_Patch1 "software version patch character 1";
CM_ SG_ 965 ZONE_DR_SW_Minor2 "software version minor character 2";
CM_ SG_ 965 ZONE_DR_SW_Minor1 "software version minor character 1";
CM_ SG_ 965 ZONE_DR_SW_Major2 "software version major character 2";
CM_ SG_ 965 ZONE_DR_SW_Major1 "software version major character 1";
CM_ SG_ 965 ZONE_DR_SW_Controller2 "software version controller character 2";
CM_ SG_ 965 ZONE_DR_SW_Controller1 "software version controller character 1";
CM_ SG_ 965 ZONE_DR_SW_CarModel3 "software version car model character 3";
CM_ SG_ 965 ZONE_DR_SW_CarModel2 "software version car model character 2";
CM_ SG_ 965 ZONE_DR_SW_CarModel1 "software version car model character 1";
CM_ SG_ 965 ZONE_DR_HW_Ver3 "ZONE_DR hardware version character 3";
CM_ SG_ 965 ZONE_DR_HW_Ver2 "ZONE_DR hardware version character 2";
CM_ SG_ 965 ZONE_DR_HW_Ver1 "ZONE_DR hardware version character 1";
CM_ SG_ 965 ZONE_DR_SW_dash1 "software version dash character 1";
CM_ SG_ 965 ZONE_DR_SW_change1 "software version number of change 1";
CM_ SG_ 965 ZONE_DR_SW_change2 "software version number of change 2";
CM_ SG_ 965 ZONE_DR_SW_dash2 "software version dash character 2";
CM_ SG_ 965 ZONE_DR_SW_SHA1 "software version SHA character 1";
CM_ SG_ 965 ZONE_DR_SW_SHA2 "software version SHA character 2";
CM_ SG_ 965 ZONE_DR_SW_SHA3 "software version SHA character 3";
CM_ SG_ 965 ZONE_DR_SW_SHA4 "software version SHA character 4";
CM_ SG_ 965 ZONE_DR_SW_SHA5 "software version SHA character 5";
CM_ SG_ 965 ZONE_DR_SW_SHA6 "software version SHA character 6";
CM_ SG_ 965 ZONE_DR_SW_SHA7 "software version SHA character 7";
CM_ SG_ 965 ZONE_DR_SW_SHA8 "software version SHA character 8";
CM_ SG_ 965 ZONE_DR_SW_Var5 "software version car model variation 5";
CM_ SG_ 965 ZONE_DR_SW_Var4 "software version car model variation 4";
CM_ SG_ 965 ZONE_DR_SW_Var3 "software version car model variation 3";
CM_ SG_ 965 ZONE_DR_SW_Var2 "software version car model variation 2";
CM_ SG_ 965 ZONE_DR_SW_ECUGen2 "ECU generation 2";
CM_ SG_ 965 ZONE_DR_SW_ECUGen1 "ECU generation 1";

BA_DEF_ "NmType" STRING ;
BA_DEF_ "VersionYear" INT 2010 2999;
BA_DEF_ "ProtocolType" STRING ;
BA_DEF_ "NmMessageCount" INT 0 255;
BA_DEF_ "NmBaseAddress" HEX 1280 1407;
BA_DEF_ "Manufacturer" STRING ;
BA_DEF_ "DBName" STRING ;
BA_DEF_ "BusType" STRING ;
BA_DEF_ "Baudrate" INT 0 1000000;
BA_DEF_ "Datarate" INT 0 2000000;
BA_DEF_ BO_ "GenMsgSendType" ENUM "Cycle","NoMsgSendType","IfActive","Event","CA","CE";
BA_DEF_ BO_ "GenMsgNrOfRepetition" INT 0 0;
BA_DEF_ BO_ "GenMsgILSupport" ENUM "No","Yes";
BA_DEF_ BO_ "GenMsgCycleTime" INT 0 0;
BA_DEF_ BO_ "DiagResponse" ENUM "No","Yes";
BA_DEF_ BO_ "DiagRequest" ENUM "No","Yes";
BA_DEF_ BO_ "NmMessage" ENUM "No","Yes";
BA_DEF_ BO_ "VFrameFormat" ENUM "StandardCAN","ExtendedCAN","reserved","reserved","reserved","reserved","reserved","reserved","reserved","reserved","reserved","reserved","reserved","reserved","StandardCAN_FD","ExtendedCAN_FD";
BA_DEF_ BO_ "DataID" STRING ;
BA_DEF_ BO_ "DoIPLogicalAddress" STRING ;
BA_DEF_ BO_ "CANFD_BRS" ENUM "0","1";
BA_DEF_ BO_ "GenMsgRequestable" INT 0 1;
BA_DEF_ SG_ "GenSigInvalidValue" HEX 0 0;
BA_DEF_ SG_ "GenSigStartValue" HEX 0 0;
BA_DEF_ SG_ "GenSigInactiveValue" HEX 0 0;
BA_DEF_ SG_ "GenSigRoutingTimeoutValue_String" STRING ;
BA_DEF_ SG_ "DataCenterDataType" STRING ;
BA_DEF_ SG_ "GenSigRoutingTimeoutValue" HEX 0 0;
BA_DEF_ SG_ "GenSigSendType" ENUM "Cycle","OnWrite","OnWriteWithRepetition","OnChange","OnChangeWithRepetition","IfActive","IfActiveWithRepetition","NoSigSendType","vector_leerstring";
BA_DEF_ SG_ "SigType" ENUM "Default","Range","RangeSigned","ASCII","Discrete","Control","ReferencePGN","DTC","StringDelimiter","StringLength","StringLengthControl","MessageCounter","MessageChecksum";
BA_DEF_ SG_ "GenSigILSupport" ENUM "No","Yes";
BA_DEF_ BU_ "NodeLayerModules" STRING ;
BA_DEF_ BU_ "ILUsed" ENUM "No","Yes";
BA_DEF_ BU_ "NmNodeAddress" HEX 0 255;
BA_DEF_ BU_ "NmCAN" INT 1 2;
BA_DEF_ BU_ "NmStationAddress" HEX 0 255;
BA_DEF_ BU_ "CANFD_CANFD_Gateway" ENUM "Yes","No";
BA_DEF_ BU_ "BootloaderNode" ENUM "No","Yes";
BA_DEF_DEF_ "NmType" "AUTOSAR";
BA_DEF_DEF_ "VersionYear" 2024;
BA_DEF_DEF_ "ProtocolType" "CAN";
BA_DEF_DEF_ "NmMessageCount" 128;
BA_DEF_DEF_ "NmBaseAddress" 1280;
BA_DEF_DEF_ "Manufacturer" "";
BA_DEF_DEF_ "DBName" "";
BA_DEF_DEF_ "BusType" "CAN";
BA_DEF_DEF_ "Baudrate" 500000;
BA_DEF_DEF_ "Datarate" 2000000;
BA_DEF_DEF_ "GenMsgSendType" "Cycle";
BA_DEF_DEF_ "GenMsgNrOfRepetition" 0;
BA_DEF_DEF_ "GenMsgILSupport" "Yes";
BA_DEF_DEF_ "GenMsgCycleTime" 100;
BA_DEF_DEF_ "DiagResponse" "No";
BA_DEF_DEF_ "DiagRequest" "No";
BA_DEF_DEF_ "NmMessage" "No";
BA_DEF_DEF_ "VFrameFormat" "StandardCAN";
BA_DEF_DEF_ "DataID" "";
BA_DEF_DEF_ "DoIPLogicalAddress" "";
BA_DEF_DEF_ "CANFD_BRS" "1";
BA_DEF_DEF_ "GenMsgRequestable" 1;
BA_DEF_DEF_ "GenSigInvalidValue" 0;
BA_DEF_DEF_ "GenSigStartValue" 0;
BA_DEF_DEF_ "GenSigInactiveValue" 0;
BA_DEF_DEF_ "GenSigRoutingTimeoutValue_String" "";
BA_DEF_DEF_ "DataCenterDataType" "";
BA_DEF_DEF_ "GenSigRoutingTimeoutValue" 0;
BA_DEF_DEF_ "GenSigSendType" "Cycle";
BA_DEF_DEF_ "SigType" "Default";
BA_DEF_DEF_ "GenSigILSupport" "Yes";
BA_DEF_DEF_ "NodeLayerModules" "CANoeILNLVector.dll";
BA_DEF_DEF_ "ILUsed" "Yes";
BA_DEF_DEF_ "NmNodeAddress" 0;
BA_DEF_DEF_ "NmCAN" 2;
BA_DEF_DEF_ "NmStationAddress" 0;
BA_DEF_DEF_ "CANFD_CANFD_Gateway" "No";
BA_DEF_DEF_ "BootloaderNode" "No";
BA_ "BusType" "CAN FD";
BA_ "ProtocolType" "CAN FD";
BA_ "Manufacturer" "FVT";
BA_ "DBName" "CAN2";
BA_ "CANFD_CANFD_Gateway" BU_ FUSION 0;
BA_ "BootloaderNode" BU_ HMI 1;
BA_ "BootloaderNode" BU_ Meter 1;
BA_ "BootloaderNode" BU_ WCM 1;
BA_ "GenMsgNrOfRepetition" BO_ 279 1;
BA_ "GenMsgSendType" BO_ 279 5;
BA_ "VFrameFormat" BO_ 279 14;
BA_ "GenMsgCycleTime" BO_ 435 10;
BA_ "VFrameFormat" BO_ 435 14;
BA_ "GenMsgNrOfRepetition" BO_ 372 1;
BA_ "GenMsgCycleTime" BO_ 372 200;
BA_ "GenMsgSendType" BO_ 372 5;
BA_ "VFrameFormat" BO_ 372 14;
BA_ "GenMsgNrOfRepetition" BO_ 450 1;
BA_ "GenMsgSendType" BO_ 450 5;
BA_ "VFrameFormat" BO_ 450 14;
BA_ "GenMsgCycleTime" BO_ 528 20;
BA_ "VFrameFormat" BO_ 528 14;
BA_ "GenMsgNrOfRepetition" BO_ 823 1;
BA_ "GenMsgCycleTime" BO_ 823 1000;
BA_ "GenMsgSendType" BO_ 823 5;
BA_ "VFrameFormat" BO_ 823 14;
BA_ "GenMsgCycleTime" BO_ 963 5000;
BA_ "VFrameFormat" BO_ 963 14;
BA_ "GenMsgNrOfRepetition" BO_ 1077 1;
BA_ "GenMsgCycleTime" BO_ 1077 200;
BA_ "GenMsgSendType" BO_ 1077 5;
BA_ "VFrameFormat" BO_ 1077 14;
BA_ "GenMsgCycleTime" BO_ 1280 0;
BA_ "NmMessage" BO_ 1280 1;
BA_ "GenMsgSendType" BO_ 1280 3;
BA_ "GenMsgCycleTime" BO_ 1666 0;
BA_ "DiagRequest" BO_ 1666 1;
BA_ "GenMsgSendType" BO_ 1666 3;
BA_ "VFrameFormat" BO_ 1666 14;
BA_ "DoIPLogicalAddress" BO_ 1666 "0x0682";
BA_ "GenMsgCycleTime" BO_ 1696 0;
BA_ "DiagRequest" BO_ 1696 1;
BA_ "GenMsgSendType" BO_ 1696 3;
BA_ "VFrameFormat" BO_ 1696 14;
BA_ "DoIPLogicalAddress" BO_ 1696 "0x06A0";
BA_ "GenMsgCycleTime" BO_ 1714 0;
BA_ "DiagRequest" BO_ 1714 1;
BA_ "GenMsgSendType" BO_ 1714 3;
BA_ "VFrameFormat" BO_ 1714 14;
BA_ "DoIPLogicalAddress" BO_ 1714 "0x06B2";
BA_ "GenMsgCycleTime" BO_ 2000 0;
BA_ "DiagRequest" BO_ 2000 1;
BA_ "GenMsgSendType" BO_ 2000 3;
BA_ "VFrameFormat" BO_ 2000 14;
BA_ "DoIPLogicalAddress" BO_ 2000 "0xEFFF";
BA_ "GenMsgNrOfRepetition" BO_ 1080 1;
BA_ "GenMsgCycleTime" BO_ 1080 200;
BA_ "GenMsgSendType" BO_ 1080 5;
BA_ "VFrameFormat" BO_ 1080 14;
BA_ "DataID" BO_ 517 "0xFCF9";
BA_ "VFrameFormat" BO_ 517 14;
BA_ "GenMsgCycleTime" BO_ 965 5000;
BA_ "VFrameFormat" BO_ 965 14;
BA_ "GenSigSendType" SG_ 279 CreepSW_Sta 3;
BA_ "GenSigSendType" SG_ 279 EngageP_Fail 3;
BA_ "GenSigSendType" SG_ 279 DisengageP_Fail 3;
BA_ "GenSigSendType" SG_ 279 FalseNPrevent_Sta 3;
BA_ "GenSigInvalidValue" SG_ 279 DynoModeStaChk 3;
BA_ "GenSigInvalidValue" SG_ 279 CoastDwModeStaChk 3;
BA_ "GenSigInvalidValue" SG_ 279 DemoModeStaChk 2;
BA_ "GenSigRoutingTimeoutValue_String" SG_ 279 DemoModeStaChk "0x2";
BA_ "GenSigRoutingTimeoutValue" SG_ 279 DemoModeStaChk 2;
BA_ "GenSigInvalidValue" SG_ 279 MSA_Crl_Sta 6;
BA_ "GenSigRoutingTimeoutValue_String" SG_ 279 MSA_Crl_Sta "0x6";
BA_ "GenSigInactiveValue" SG_ 279 MSA_Crl_Sta 6;
BA_ "GenSigRoutingTimeoutValue" SG_ 279 MSA_Crl_Sta 6;
BA_ "GenSigSendType" SG_ 279 MSA_Crl_Sta 3;
BA_ "DataCenterDataType" SG_ 279 MSA_Crl_Sta "varchar(25)";
BA_ "GenSigInvalidValue" SG_ 279 CC_Crl_Sta 6;
BA_ "GenSigSendType" SG_ 279 CC_Crl_Sta 3;
BA_ "DataCenterDataType" SG_ 279 CC_Crl_Sta "varchar(25)";
BA_ "GenSigInvalidValue" SG_ 279 LVChrgFuncStaChk 2;
BA_ "GenSigRoutingTimeoutValue_String" SG_ 279 LVChrgFuncStaChk "0x2";
BA_ "GenSigRoutingTimeoutValue" SG_ 279 LVChrgFuncStaChk 2;
BA_ "GenSigInvalidValue" SG_ 279 ShiftGearPosn 1;
BA_ "GenSigStartValue" SG_ 279 ShiftGearPosn 1;
BA_ "GenSigRoutingTimeoutValue_String" SG_ 279 ShiftGearPosn "0x1";
BA_ "GenSigInactiveValue" SG_ 279 ShiftGearPosn 1;
BA_ "GenSigRoutingTimeoutValue" SG_ 279 ShiftGearPosn 1;
BA_ "GenSigSendType" SG_ 279 ShiftGearPosn 3;
BA_ "DataCenterDataType" SG_ 279 ShiftGearPosn "Varchar(10)";
BA_ "GenSigInvalidValue" SG_ 279 PwrSta 7;
BA_ "GenSigStartValue" SG_ 279 PwrSta 7;
BA_ "GenSigRoutingTimeoutValue_String" SG_ 279 PwrSta "0x7";
BA_ "GenSigInactiveValue" SG_ 279 PwrSta 7;
BA_ "GenSigRoutingTimeoutValue" SG_ 279 PwrSta 7;
BA_ "GenSigSendType" SG_ 279 PwrSta 3;
BA_ "DataCenterDataType" SG_ 279 PwrSta "Varchar(15)";
BA_ "GenSigSendType" SG_ 279 XWDMode 3;
BA_ "DataCenterDataType" SG_ 279 CCU_ACLampSts "varchar(10)";
BA_ "DataCenterDataType" SG_ 279 CCU_AutoLampSts "Varchar(10)";
BA_ "GenSigInvalidValue" SG_ 279 sigWindDirZon1St 7;
BA_ "GenSigStartValue" SG_ 279 sigWindDirZon1St 7;
BA_ "GenSigRoutingTimeoutValue_String" SG_ 279 sigWindDirZon1St "0x7";
BA_ "GenSigInactiveValue" SG_ 279 sigWindDirZon1St 7;
BA_ "GenSigRoutingTimeoutValue" SG_ 279 sigWindDirZon1St 7;
BA_ "GenSigInvalidValue" SG_ 279 sigWindDirZon3St 7;
BA_ "GenSigStartValue" SG_ 279 sigWindDirZon3St 7;
BA_ "GenSigRoutingTimeoutValue_String" SG_ 279 sigWindDirZon3St "0x7";
BA_ "GenSigInactiveValue" SG_ 279 sigWindDirZon3St 7;
BA_ "GenSigRoutingTimeoutValue" SG_ 279 sigWindDirZon3St 7;
BA_ "DataCenterDataType" SG_ 279 sigWindDirZon3St "varchar(30)";
BA_ "GenSigInvalidValue" SG_ 279 sigAirIntenZon1St 15;
BA_ "GenSigRoutingTimeoutValue_String" SG_ 279 sigAirIntenZon1St "0xF";
BA_ "GenSigRoutingTimeoutValue" SG_ 279 sigAirIntenZon1St 15;
BA_ "DataCenterDataType" SG_ 279 sigAirIntenZon1St "varchar(15)";
BA_ "GenSigInvalidValue" SG_ 279 sigAirIntenZon3St 15;
BA_ "GenSigRoutingTimeoutValue_String" SG_ 279 sigAirIntenZon3St "0xF";
BA_ "GenSigRoutingTimeoutValue" SG_ 279 sigAirIntenZon3St 15;
BA_ "DataCenterDataType" SG_ 279 sigRecircSt "Varchar(10)";
BA_ "GenSigInvalidValue" SG_ 279 VCUBrkSWSta 2;
BA_ "GenSigRoutingTimeoutValue_String" SG_ 279 VCUBrkSWSta "0x2";
BA_ "GenSigRoutingTimeoutValue" SG_ 279 VCUBrkSWSta 2;
BA_ "GenSigSendType" SG_ 279 VCUBrkSWSta 3;
BA_ "DataCenterDataType" SG_ 279 sigSetTempZon1St "float";
BA_ "GenSigInvalidValue" SG_ 279 sigAmbAirT 255;
BA_ "GenSigRoutingTimeoutValue_String" SG_ 279 sigAmbAirT "0xFF";
BA_ "GenSigRoutingTimeoutValue" SG_ 279 sigAmbAirT 255;
BA_ "DataCenterDataType" SG_ 279 sigAmbAirT "Varchar(5)";
BA_ "GenSigSendType" SG_ 279 SysPwrSta 3;
BA_ "GenSigSendType" SG_ 279 MCUActDisFail 3;
BA_ "GenSigSendType" SG_ 279 PwrStaONTOIVIPopReq 3;
BA_ "GenSigSendType" SG_ 279 VCUFLDoorSta 3;
BA_ "GenSigSendType" SG_ 279 VCUFRDoorSta 3;
BA_ "GenSigSendType" SG_ 279 VCURLDoorSta 3;
BA_ "GenSigSendType" SG_ 279 VCURRDoorSta 3;
BA_ "GenSigSendType" SG_ 279 HVRlyOpFail 3;
BA_ "GenSigSendType" SG_ 279 SysAllowReadySta 3;
BA_ "GenSigSendType" SG_ 279 PwrStaONTOIVIPopT 3;
BA_ "GenSigSendType" SG_ 279 Req_V2LSwOn 3;
BA_ "GenSigSendType" SG_ 279 Req_V2L_IVI_Popup 3;
BA_ "GenSigSendType" SG_ 279 VCUHoodSWSta 3;
BA_ "GenSigSendType" SG_ 279 VCUTailgateSWSta 3;
BA_ "GenSigSendType" SG_ 279 FD_EPB_Error 3;
BA_ "GenSigSendType" SG_ 279 FD_Park_Brake_Warning 3;
BA_ "GenSigSendType" SG_ 279 FD_TCS_Indicator 3;
BA_ "GenSigSendType" SG_ 279 FD_ABS_Warning 3;
BA_ "GenSigSendType" SG_ 279 FD_Steering_Warning 3;
BA_ "GenSigSendType" SG_ 279 FD_HV_Battery_Fault 3;
BA_ "GenSigSendType" SG_ 279 FD_EDrive_System 3;
BA_ "GenSigSendType" SG_ 279 FD_Battery_Charge_Warning 3;
BA_ "GenSigSendType" SG_ 279 FD_Power_limitation 3;
BA_ "GenSigRoutingTimeoutValue_String" SG_ 279 FD_Telltale_Fail "0x1";
BA_ "GenSigRoutingTimeoutValue" SG_ 279 FD_Telltale_Fail 1;
BA_ "GenSigSendType" SG_ 279 FD_Telltale_Fail 3;
BA_ "GenSigRoutingTimeoutValue_String" SG_ 279 FeatSetSpdFinal_raw32 "0x0";
BA_ "GenSigSendType" SG_ 279 FeatSetSpdFinal_raw32 3;
BA_ "GenSigInvalidValue" SG_ 279 Eng_ActvDmpDisabSta 2;
BA_ "GenSigRoutingTimeoutValue_String" SG_ 279 Eng_ActvDmpDisabSta "0x2";
BA_ "GenSigRoutingTimeoutValue" SG_ 279 Eng_ActvDmpDisabSta 2;
BA_ "GenSigSendType" SG_ 279 Eng_ActvDmpDisabSta 3;
BA_ "GenSigInvalidValue" SG_ 279 Eng_CoastDwSta 2;
BA_ "GenSigRoutingTimeoutValue_String" SG_ 279 Eng_CoastDwSta "0x2";
BA_ "GenSigRoutingTimeoutValue" SG_ 279 Eng_CoastDwSta 2;
BA_ "GenSigSendType" SG_ 279 Eng_CoastDwSta 3;
BA_ "GenSigInvalidValue" SG_ 279 Eng_PwrLockSta 2;
BA_ "GenSigRoutingTimeoutValue_String" SG_ 279 Eng_PwrLockSta "0x2";
BA_ "GenSigRoutingTimeoutValue" SG_ 279 Eng_PwrLockSta 2;
BA_ "GenSigSendType" SG_ 279 Eng_PwrLockSta 3;
BA_ "GenSigRoutingTimeoutValue_String" SG_ 279 EDriveSysErr_AccPedalErr "0x1";
BA_ "GenSigRoutingTimeoutValue" SG_ 279 EDriveSysErr_AccPedalErr 1;
BA_ "GenSigSendType" SG_ 279 EDriveSysErr_AccPedalErr 3;
BA_ "GenSigRoutingTimeoutValue_String" SG_ 279 EDriveSysErr_MCUErr "0x1";
BA_ "GenSigRoutingTimeoutValue" SG_ 279 EDriveSysErr_MCUErr 1;
BA_ "GenSigSendType" SG_ 279 EDriveSysErr_MCUErr 3;
BA_ "GenSigRoutingTimeoutValue_String" SG_ 279 EDriveSysErr_ShifterErr "0x1";
BA_ "GenSigRoutingTimeoutValue" SG_ 279 EDriveSysErr_ShifterErr 1;
BA_ "GenSigSendType" SG_ 279 EDriveSysErr_ShifterErr 3;
BA_ "GenSigRoutingTimeoutValue_String" SG_ 279 EDriveSysErr_VCUErr "0x1";
BA_ "GenSigRoutingTimeoutValue" SG_ 279 EDriveSysErr_VCUErr 1;
BA_ "GenSigSendType" SG_ 279 EDriveSysErr_VCUErr 3;
BA_ "GenSigSendType" SG_ 279 Eng_AGSCloseSta 3;
BA_ "GenSigInvalidValue" SG_ 279 Dimmer 127;
BA_ "GenSigRoutingTimeoutValue_String" SG_ 279 Dimmer "0x7F";
BA_ "GenSigRoutingTimeoutValue" SG_ 279 Dimmer 127;
BA_ "GenSigSendType" SG_ 279 Dimmer 3;
BA_ "GenSigSendType" SG_ 279 VehMalfunLevel 3;
BA_ "GenSigSendType" SG_ 279 AntitheftSta 3;
BA_ "DataCenterDataType" SG_ 279 AntitheftSta "Varchar(30)";
BA_ "GenSigInvalidValue" SG_ 279 Dr_SeatSta 2;
BA_ "GenSigStartValue" SG_ 279 Dr_SeatSta 2;
BA_ "GenSigRoutingTimeoutValue_String" SG_ 279 Dr_SeatSta "0x2";
BA_ "GenSigInactiveValue" SG_ 279 Dr_SeatSta 2;
BA_ "GenSigRoutingTimeoutValue" SG_ 279 Dr_SeatSta 2;
BA_ "GenSigSendType" SG_ 279 Dr_SeatSta 3;
BA_ "GenSigSendType" SG_ 279 EVDriveMode 3;
BA_ "GenSigSendType" SG_ 279 AllDoorSW 3;
BA_ "GenSigSendType" SG_ 279 BCM_DoorLock_Sta 3;
BA_ "DataCenterDataType" SG_ 279 BCM_DoorLock_Sta "Varchar(7)";
BA_ "GenSigSendType" SG_ 279 BrakeLamp 3;
BA_ "GenSigSendType" SG_ 279 DoorLockIND 3;
BA_ "GenSigSendType" SG_ 279 DrDoorSW 3;
BA_ "GenSigSendType" SG_ 279 Fr_FogLamp 3;
BA_ "GenSigSendType" SG_ 279 HazardSW 3;
BA_ "GenSigSendType" SG_ 279 HoodSW 3;
BA_ "GenSigRoutingTimeoutValue_String" SG_ 279 HVSysErr_IsolationErr "0x1";
BA_ "GenSigRoutingTimeoutValue" SG_ 279 HVSysErr_IsolationErr 1;
BA_ "GenSigSendType" SG_ 279 HVSysErr_IsolationErr 3;
BA_ "GenSigRoutingTimeoutValue_String" SG_ 279 HVSysErr_PackErr "0x1";
BA_ "GenSigRoutingTimeoutValue" SG_ 279 HVSysErr_PackErr 1;
BA_ "GenSigSendType" SG_ 279 HVSysErr_PackErr 3;
BA_ "GenSigRoutingTimeoutValue_String" SG_ 279 HVSysErr_RelayErr "0x1";
BA_ "GenSigRoutingTimeoutValue" SG_ 279 HVSysErr_RelayErr 1;
BA_ "GenSigSendType" SG_ 279 HVSysErr_RelayErr 3;
BA_ "GenSigSendType" SG_ 279 H_Beam 3;
BA_ "GenSigSendType" SG_ 279 LBSD 3;
BA_ "GenSigSendType" SG_ 279 LDRL 3;
BA_ "GenSigSendType" SG_ 279 LimphomeAct 3;
BA_ "GenSigSendType" SG_ 279 LockSetting 3;
BA_ "GenSigSendType" SG_ 279 LTurnLP 3;
BA_ "GenSigRoutingTimeoutValue_String" SG_ 279 LVSysErr_PwrOutpErr "0x1";
BA_ "GenSigRoutingTimeoutValue" SG_ 279 LVSysErr_PwrOutpErr 1;
BA_ "GenSigSendType" SG_ 279 LVSysErr_PwrOutpErr 3;
BA_ "GenSigSendType" SG_ 279 L_Beam 3;
BA_ "GenSigSendType" SG_ 279 PosLamp 3;
BA_ "GenSigSendType" SG_ 279 PsDoorSW 3;
BA_ "GenSigRoutingTimeoutValue_String" SG_ 279 PwrStaErr "0x1";
BA_ "GenSigRoutingTimeoutValue" SG_ 279 PwrStaErr 1;
BA_ "GenSigSendType" SG_ 279 PwrStaErr 3;
BA_ "GenSigSendType" SG_ 279 RBSD 3;
BA_ "GenSigSendType" SG_ 279 RDRL 3;
BA_ "GenSigSendType" SG_ 279 ReverseLamp 3;
BA_ "GenSigSendType" SG_ 279 RLDoorSW 3;
BA_ "GenSigSendType" SG_ 279 RRDoorSW 3;
BA_ "GenSigSendType" SG_ 279 Rr_Defog 3;
BA_ "GenSigSendType" SG_ 279 Rr_FogLamp 3;
BA_ "GenSigSendType" SG_ 279 RTurnLP 3;
BA_ "GenSigSendType" SG_ 279 Tailgate_SW 3;
BA_ "GenSigSendType" SG_ 279 FD_EBMErrSta 3;
BA_ "GenSigSendType" SG_ 279 DimmerEN 3;
BA_ "GenSigSendType" SG_ 279 FDC_VCU_PwrSaveReq_Cmd 3;
BA_ "GenSigInvalidValue" SG_ 279 FDC_THCM_LEVentY_Sta 127;
BA_ "GenSigRoutingTimeoutValue_String" SG_ 279 FDC_THCM_LEVentY_Sta "0x7F";
BA_ "GenSigRoutingTimeoutValue" SG_ 279 FDC_THCM_LEVentY_Sta 127;
BA_ "GenSigInvalidValue" SG_ 279 FDC_THCM_REVentY_Sta 127;
BA_ "GenSigRoutingTimeoutValue_String" SG_ 279 FDC_THCM_REVentY_Sta "0x7F";
BA_ "GenSigRoutingTimeoutValue" SG_ 279 FDC_THCM_REVentY_Sta 127;
BA_ "GenSigInvalidValue" SG_ 279 FDC_THCM_CLEVentY_Sta 127;
BA_ "GenSigRoutingTimeoutValue_String" SG_ 279 FDC_THCM_CLEVentY_Sta "0x7F";
BA_ "GenSigRoutingTimeoutValue" SG_ 279 FDC_THCM_CLEVentY_Sta 127;
BA_ "GenSigInvalidValue" SG_ 279 FDC_THCM_CREVentY_Sta 127;
BA_ "GenSigRoutingTimeoutValue_String" SG_ 279 FDC_THCM_CREVentY_Sta "0x7F";
BA_ "GenSigRoutingTimeoutValue" SG_ 279 FDC_THCM_CREVentY_Sta 127;
BA_ "GenSigInvalidValue" SG_ 279 FDC_THCM_LEVentZ_Sta 127;
BA_ "GenSigRoutingTimeoutValue_String" SG_ 279 FDC_THCM_LEVentZ_Sta "0x7F";
BA_ "GenSigRoutingTimeoutValue" SG_ 279 FDC_THCM_LEVentZ_Sta 127;
BA_ "GenSigInvalidValue" SG_ 279 FDC_THCM_REVentZ_Sta 127;
BA_ "GenSigRoutingTimeoutValue_String" SG_ 279 FDC_THCM_REVentZ_Sta "0x7F";
BA_ "GenSigRoutingTimeoutValue" SG_ 279 FDC_THCM_REVentZ_Sta 127;
BA_ "GenSigInvalidValue" SG_ 279 FDC_THCM_CLEVentZ_Sta 127;
BA_ "GenSigRoutingTimeoutValue_String" SG_ 279 FDC_THCM_CLEVentZ_Sta "0x7F";
BA_ "GenSigRoutingTimeoutValue" SG_ 279 FDC_THCM_CLEVentZ_Sta 127;
BA_ "GenSigInvalidValue" SG_ 279 FDC_THCM_CREVentZ_Sta 127;
BA_ "GenSigRoutingTimeoutValue_String" SG_ 279 FDC_THCM_CREVentZ_Sta "0x7F";
BA_ "GenSigRoutingTimeoutValue" SG_ 279 FDC_THCM_CREVentZ_Sta 127;
BA_ "GenSigRoutingTimeoutValue_String" SG_ 279 FDC_THCM_LEVentMode_Sta "0x0";
BA_ "GenSigSendType" SG_ 279 FDC_THCM_LEVentMode_Sta 3;
BA_ "GenSigRoutingTimeoutValue_String" SG_ 279 FDC_THCM_REVentMode_Sta "0x0";
BA_ "GenSigSendType" SG_ 279 FDC_THCM_REVentMode_Sta 3;
BA_ "GenSigSendType" SG_ 279 FDC_THCM_LVent_Sta 3;
BA_ "GenSigSendType" SG_ 279 FDC_THCM_CLVent_Sta 3;
BA_ "GenSigSendType" SG_ 279 FDC_THCM_RVent_Sta 3;
BA_ "GenSigSendType" SG_ 279 FDC_THCM_CRVent_Sta 3;
BA_ "GenSigInvalidValue" SG_ 279 LVSilentChrgSta 3;
BA_ "GenSigRoutingTimeoutValue_String" SG_ 279 LVSilentChrgSta "0x3";
BA_ "GenSigRoutingTimeoutValue" SG_ 279 LVSilentChrgSta 3;
BA_ "GenSigSendType" SG_ 279 LVSilentChrgSta 3;
BA_ "DataCenterDataType" SG_ 279 LVSilentChrgSta "varchar(15)";
BA_ "GenSigRoutingTimeoutValue_String" SG_ 279 FDC_THCM_PreWPTCHeat_Sta "0x0";
BA_ "GenSigSendType" SG_ 279 FDC_THCM_PreWPTCHeat_Sta 3;
BA_ "GenSigSendType" SG_ 279 FDC_RAPS_ErrWarn_Sta 3;
BA_ "GenSigSendType" SG_ 279 FDC_V2L_IVIV2LDischarg_Cmd 3;
BA_ "GenSigRoutingTimeoutValue_String" SG_ 279 FDC_BCM_HMIKey1Func_Sta "0x0";
BA_ "GenSigSendType" SG_ 279 FDC_BCM_HMIKey1Func_Sta 3;
BA_ "GenSigRoutingTimeoutValue_String" SG_ 279 FDC_BCM_HMIKey2Func_Sta "0x0";
BA_ "GenSigSendType" SG_ 279 FDC_BCM_HMIKey2Func_Sta 3;
BA_ "GenSigRoutingTimeoutValue_String" SG_ 279 FDC_BCM_HMIKey3Func_Sta "0x0";
BA_ "GenSigSendType" SG_ 279 FDC_BCM_HMIKey3Func_Sta 3;
BA_ "GenSigRoutingTimeoutValue_String" SG_ 279 FDC_BCM_HMIKey4Func_Sta "0x0";
BA_ "GenSigSendType" SG_ 279 FDC_BCM_HMIKey4Func_Sta 3;
BA_ "GenSigRoutingTimeoutValue_String" SG_ 279 FDC_BCM_HMIKey5Func_Sta "0x0";
BA_ "GenSigSendType" SG_ 279 FDC_BCM_HMIKey5Func_Sta 3;
BA_ "GenSigRoutingTimeoutValue_String" SG_ 279 FDC_BCM_HMIKey6Func_Sta "0x0";
BA_ "GenSigSendType" SG_ 279 FDC_BCM_HMIKey6Func_Sta 3;
BA_ "GenSigRoutingTimeoutValue_String" SG_ 279 FDC_BCM_HMIKey7Func_Sta "0x0";
BA_ "GenSigSendType" SG_ 279 FDC_BCM_HMIKey7Func_Sta 3;
BA_ "GenSigRoutingTimeoutValue_String" SG_ 279 FDC_BCM_HMIKey8Func_Sta "0x0";
BA_ "GenSigSendType" SG_ 279 FDC_BCM_HMIKey8Func_Sta 3;
BA_ "GenSigSendType" SG_ 279 LVSilentChrgReq 3;
BA_ "DataCenterDataType" SG_ 279 LVSilentChrgReq "varchar(20)";
BA_ "GenSigRoutingTimeoutValue_String" SG_ 279 FDC_BCM_AutoWipHSpdEN_Sta "0x0";
BA_ "GenSigSendType" SG_ 279 FDC_BCM_AutoWipHSpdEN_Sta 3;
BA_ "GenSigSendType" SG_ 279 FDC_VCU_LVChrgFreq_Sta 3;
BA_ "DataCenterDataType" SG_ 279 FDC_VCU_LVChrgFreq_Sta "varchar(20)";
BA_ "GenSigRoutingTimeoutValue_String" SG_ 279 FDC_VCU_TrailerDisOPD_Sta "0x0";
BA_ "GenSigSendType" SG_ 279 FDC_VCU_TrailerDisOPD_Sta 3;
BA_ "GenSigRoutingTimeoutValue_String" SG_ 279 FDC_VCU_LVStaTooLow_Sta "0x0";
BA_ "GenSigSendType" SG_ 279 FDC_VCU_LVStaTooLow_Sta 3;
BA_ "DataCenterDataType" SG_ 279 FDC_VCU_LVStaTooLow_Sta "varchar(20)";
BA_ "GenSigRoutingTimeoutValue_String" SG_ 279 FDC_VCU_LVStaDropQuick_Sta "0x0";
BA_ "GenSigSendType" SG_ 279 FDC_VCU_LVStaDropQuick_Sta 3;
BA_ "DataCenterDataType" SG_ 279 FDC_VCU_LVStaDropQuick_Sta "varchar(20)";
BA_ "GenSigInvalidValue" SG_ 435 VehSpeed 4095;
BA_ "GenSigRoutingTimeoutValue_String" SG_ 435 VehSpeed "0xFFF";
BA_ "GenSigInactiveValue" SG_ 435 VehSpeed 4095;
BA_ "GenSigRoutingTimeoutValue" SG_ 435 VehSpeed 4095;
BA_ "DataCenterDataType" SG_ 435 VehSpeed "Varchar(7)";
BA_ "GenSigInvalidValue" SG_ 435 RF_PulseCount_V 1;
BA_ "GenSigInvalidValue" SG_ 435 LF_PulseCount_V 1;
BA_ "GenSigInvalidValue" SG_ 435 RR_PulseCount_V 1;
BA_ "GenSigInvalidValue" SG_ 435 LR_PulseCount_V 1;
BA_ "DataCenterDataType" SG_ 435 ESC_Failed "Varchar(7)";
BA_ "DataCenterDataType" SG_ 435 TCS_Failed "Varchar(7)";
BA_ "DataCenterDataType" SG_ 435 ABS_Failed "Varchar(7)";
BA_ "DataCenterDataType" SG_ 435 EBD_Failed "Varchar(7)";
BA_ "GenSigRoutingTimeoutValue_String" SG_ 435 Amber_WnlmpSta "0x1";
BA_ "GenSigRoutingTimeoutValue" SG_ 435 Amber_WnlmpSta 1;
BA_ "GenSigRoutingTimeoutValue_String" SG_ 435 ESC_WnlmpSta "0x1";
BA_ "GenSigRoutingTimeoutValue" SG_ 435 ESC_WnlmpSta 1;
BA_ "GenSigRoutingTimeoutValue_String" SG_ 435 ESC_Off_lmpSta "0x1";
BA_ "GenSigRoutingTimeoutValue" SG_ 435 ESC_Off_lmpSta 1;
BA_ "GenSigRoutingTimeoutValue_String" SG_ 435 ABS_WnlmpSta "0x1";
BA_ "GenSigRoutingTimeoutValue" SG_ 435 ABS_WnlmpSta 1;
BA_ "GenSigRoutingTimeoutValue_String" SG_ 435 Red_WnlmpSta "0x1";
BA_ "GenSigRoutingTimeoutValue" SG_ 435 Red_WnlmpSta 1;
BA_ "GenSigInvalidValue" SG_ 435 HVBattVolt 8191;
BA_ "GenSigRoutingTimeoutValue_String" SG_ 435 HVBattVolt "0x1FFF";
BA_ "GenSigInactiveValue" SG_ 435 HVBattVolt 8191;
BA_ "GenSigRoutingTimeoutValue" SG_ 435 HVBattVolt 8191;
BA_ "DataCenterDataType" SG_ 435 HVBattVolt "Varchar(10)";
BA_ "GenSigInvalidValue" SG_ 435 DCDCAuxCur 4095;
BA_ "GenSigRoutingTimeoutValue_String" SG_ 435 DCDCAuxCur "0xFFF";
BA_ "GenSigInactiveValue" SG_ 435 DCDCAuxCur 4095;
BA_ "GenSigRoutingTimeoutValue" SG_ 435 DCDCAuxCur 4095;
BA_ "DataCenterDataType" SG_ 435 DCDCAuxCur "Decimal";
BA_ "GenSigInvalidValue" SG_ 435 HVBattCurr 32767;
BA_ "GenSigStartValue" SG_ 435 HVBattCurr 10000;
BA_ "GenSigRoutingTimeoutValue_String" SG_ 435 HVBattCurr "0x7FFF";
BA_ "GenSigRoutingTimeoutValue" SG_ 435 HVBattCurr 32767;
BA_ "DataCenterDataType" SG_ 435 HVBattCurr "Decimal";
BA_ "GenSigInvalidValue" SG_ 435 DCDCAuxVolt 255;
BA_ "GenSigRoutingTimeoutValue_String" SG_ 435 DCDCAuxVolt "0xFF";
BA_ "GenSigInactiveValue" SG_ 435 DCDCAuxVolt 255;
BA_ "GenSigRoutingTimeoutValue" SG_ 435 DCDCAuxVolt 255;
BA_ "DataCenterDataType" SG_ 435 DCDCAuxVolt "Decimal";
BA_ "GenSigInvalidValue" SG_ 435 Meter_Ind_VehSpeed 4095;
BA_ "GenSigRoutingTimeoutValue_String" SG_ 435 Meter_Ind_VehSpeed "0xFFF";
BA_ "GenSigInactiveValue" SG_ 435 Meter_Ind_VehSpeed 4095;
BA_ "GenSigRoutingTimeoutValue" SG_ 435 Meter_Ind_VehSpeed 4095;
BA_ "GenSigRoutingTimeoutValue_String" SG_ 435 BrkSw_Sta "0x0";
BA_ "GenSigInvalidValue" SG_ 435 BrkSw_V 1;
BA_ "GenSigRoutingTimeoutValue_String" SG_ 435 BrkSw_V "0x1";
BA_ "GenSigRoutingTimeoutValue" SG_ 435 BrkSw_V 1;
BA_ "GenSigInvalidValue" SG_ 435 EBMErrSta 1;
BA_ "GenSigRoutingTimeoutValue_String" SG_ 435 EBMErrSta "0x1";
BA_ "GenSigRoutingTimeoutValue" SG_ 435 EBMErrSta 1;
BA_ "GenSigRoutingTimeoutValue_String" SG_ 435 EBMRLampSta "0x2";
BA_ "GenSigRoutingTimeoutValue" SG_ 435 EBMRLampSta 2;
BA_ "GenSigRoutingTimeoutValue_String" SG_ 435 LADB_Hibeam_Indication "0x0";
BA_ "GenSigRoutingTimeoutValue_String" SG_ 435 LADB_Operation_Status "0x0";
BA_ "GenSigRoutingTimeoutValue_String" SG_ 435 LADB_Warning "0x0";
BA_ "GenSigRoutingTimeoutValue_String" SG_ 435 LLB_Warning "0x0";
BA_ "GenSigRoutingTimeoutValue_String" SG_ 435 LAHB_Warning "0x0";
BA_ "GenSigRoutingTimeoutValue_String" SG_ 435 FLTurn_Light_Warning "0x0";
BA_ "GenSigRoutingTimeoutValue_String" SG_ 435 LDRL_Warning "0x0";
BA_ "GenSigRoutingTimeoutValue_String" SG_ 435 Lposition_Lamp_Warning "0x0";
BA_ "GenSigRoutingTimeoutValue_String" SG_ 435 RADB_Hibeam_Indication "0x0";
BA_ "GenSigRoutingTimeoutValue_String" SG_ 435 RADB_Operation_Status "0x0";
BA_ "GenSigRoutingTimeoutValue_String" SG_ 435 RADB_Warning "0x0";
BA_ "GenSigRoutingTimeoutValue_String" SG_ 435 RLB_Warning "0x0";
BA_ "GenSigRoutingTimeoutValue_String" SG_ 435 RAHB_Warning "0x0";
BA_ "GenSigRoutingTimeoutValue_String" SG_ 435 FRTurn_Light_Warning "0x0";
BA_ "GenSigRoutingTimeoutValue_String" SG_ 435 RDRL_Warning "0x0";
BA_ "GenSigRoutingTimeoutValue_String" SG_ 435 Rposition_Lamp_Warning "0x0";
BA_ "GenSigInvalidValue" SG_ 435 SAS_Angle 65535;
BA_ "GenSigStartValue" SG_ 435 SAS_Angle 9000;
BA_ "GenSigRoutingTimeoutValue_String" SG_ 435 SAS_Angle "0xFFFF";
BA_ "GenSigRoutingTimeoutValue" SG_ 435 SAS_Angle 65535;
BA_ "GenSigInvalidValue" SG_ 435 CrashOutputSts 255;
BA_ "GenSigRoutingTimeoutValue_String" SG_ 435 CrashOutputSts "0xFF";
BA_ "GenSigRoutingTimeoutValue" SG_ 435 CrashOutputSts 255;
BA_ "DataCenterDataType" SG_ 435 CrashOutputSts "Varchar(20)";
BA_ "DataCenterDataType" SG_ 435 EpasFailed "Varchar(10)";
BA_ "GenSigRoutingTimeoutValue_String" SG_ 435 AirBagFailCmd "0x1";
BA_ "GenSigRoutingTimeoutValue" SG_ 435 AirBagFailCmd 1;
BA_ "DataCenterDataType" SG_ 435 AirBagFailCmd "Varchar(10)";
BA_ "DataCenterDataType" SG_ 435 HVBattErr "Varchar(15)";
BA_ "GenSigRoutingTimeoutValue_String" SG_ 435 LADBErr "0x1";
BA_ "GenSigRoutingTimeoutValue" SG_ 435 LADBErr 1;
BA_ "GenSigRoutingTimeoutValue_String" SG_ 435 LH_BeamErr "0x1";
BA_ "GenSigRoutingTimeoutValue" SG_ 435 LH_BeamErr 1;
BA_ "GenSigRoutingTimeoutValue_String" SG_ 435 LL_BeamErr "0x1";
BA_ "GenSigRoutingTimeoutValue" SG_ 435 LL_BeamErr 1;
BA_ "GenSigRoutingTimeoutValue_String" SG_ 435 RADBErr "0x1";
BA_ "GenSigRoutingTimeoutValue" SG_ 435 RADBErr 1;
BA_ "GenSigRoutingTimeoutValue_String" SG_ 435 RH_BeamErr "0x1";
BA_ "GenSigRoutingTimeoutValue" SG_ 435 RH_BeamErr 1;
BA_ "GenSigRoutingTimeoutValue_String" SG_ 435 RL_BeamErr "0x1";
BA_ "GenSigRoutingTimeoutValue" SG_ 435 RL_BeamErr 1;
BA_ "GenSigRoutingTimeoutValue_String" SG_ 435 RLTurnLPErr "0x1";
BA_ "GenSigRoutingTimeoutValue" SG_ 435 RLTurnLPErr 1;
BA_ "GenSigRoutingTimeoutValue_String" SG_ 435 RRTurnLPErr "0x1";
BA_ "GenSigRoutingTimeoutValue" SG_ 435 RRTurnLPErr 1;
BA_ "GenSigRoutingTimeoutValue_String" SG_ 435 FLTurnLPErr "0x1";
BA_ "GenSigRoutingTimeoutValue" SG_ 435 FLTurnLPErr 1;
BA_ "GenSigRoutingTimeoutValue_String" SG_ 435 FRTurnLPErr "0x1";
BA_ "GenSigRoutingTimeoutValue" SG_ 435 FRTurnLPErr 1;
BA_ "GenSigRoutingTimeoutValue_String" SG_ 372 ADAS_VehSpdLim "0x0";
BA_ "GenSigSendType" SG_ 372 ADAS_VehSpdLim 3;
BA_ "GenSigRoutingTimeoutValue_String" SG_ 372 ADAS_LFC_Warn_Sound "0x0";
BA_ "GenSigSendType" SG_ 372 ADAS_LFC_Warn_Sound 3;
BA_ "GenSigInvalidValue" SG_ 372 ACC_ObjDist 2047;
BA_ "GenSigStartValue" SG_ 372 ACC_ObjDist 2046;
BA_ "GenSigRoutingTimeoutValue_String" SG_ 372 ACC_ObjDist "0x7FF";
BA_ "GenSigRoutingTimeoutValue" SG_ 372 ACC_ObjDist 2047;
BA_ "GenSigSendType" SG_ 372 ACC_ObjDist 3;
BA_ "GenSigInvalidValue" SG_ 372 ACC_ObjRelSpd 2047;
BA_ "GenSigRoutingTimeoutValue_String" SG_ 372 ACC_ObjRelSpd "0x7FF";
BA_ "GenSigRoutingTimeoutValue" SG_ 372 ACC_ObjRelSpd 2047;
BA_ "GenSigSendType" SG_ 372 ACC_ObjRelSpd 3;
BA_ "GenSigRoutingTimeoutValue_String" SG_ 372 ADAS_CAM_SpdLim "0x0";
BA_ "GenSigSendType" SG_ 372 ADAS_CAM_SpdLim 3;
BA_ "GenSigRoutingTimeoutValue_String" SG_ 372 ADAS_SLIF_SpdLim "0x0";
BA_ "GenSigSendType" SG_ 372 ADAS_SLIF_SpdLim 3;
BA_ "GenSigInvalidValue" SG_ 372 ADAS_ISA_Sta 6;
BA_ "GenSigRoutingTimeoutValue_String" SG_ 372 ADAS_ISA_Sta "0x0";
BA_ "GenSigSendType" SG_ 372 ADAS_ISA_Sta 3;
BA_ "GenSigRoutingTimeoutValue_String" SG_ 372 ADAS_WarningMsg "0x0";
BA_ "GenSigSendType" SG_ 372 ADAS_WarningMsg 3;
BA_ "GenSigRoutingTimeoutValue_String" SG_ 372 ACC_ObjDstLvl "0x0";
BA_ "GenSigSendType" SG_ 372 ACC_ObjDstLvl 3;
BA_ "GenSigRoutingTimeoutValue_String" SG_ 372 ADAS_ACC_Sta "0x0";
BA_ "GenSigSendType" SG_ 372 ADAS_ACC_Sta 3;
BA_ "DataCenterDataType" SG_ 372 ADAS_ACC_Sta "varchar(25)";
BA_ "GenSigRoutingTimeoutValue_String" SG_ 372 ADAS_AEBReq "0x0";
BA_ "GenSigSendType" SG_ 372 ADAS_AEBReq 3;
BA_ "GenSigRoutingTimeoutValue_String" SG_ 372 ADAS_AEB_Sta "0x0";
BA_ "GenSigSendType" SG_ 372 ADAS_AEB_Sta 3;
BA_ "DataCenterDataType" SG_ 372 ADAS_AEB_Sta "varchar(25)";
BA_ "GenSigRoutingTimeoutValue_String" SG_ 372 ADAS_FCW_Sta "0x0";
BA_ "GenSigSendType" SG_ 372 ADAS_FCW_Sta 3;
BA_ "DataCenterDataType" SG_ 372 ADAS_FCW_Sta "varchar(25)";
BA_ "GenSigRoutingTimeoutValue_String" SG_ 372 ADAS_LaneModeL "0x0";
BA_ "GenSigSendType" SG_ 372 ADAS_LaneModeL 3;
BA_ "GenSigRoutingTimeoutValue_String" SG_ 372 ADAS_LaneModeR "0x0";
BA_ "GenSigSendType" SG_ 372 ADAS_LaneModeR 3;
BA_ "GenSigRoutingTimeoutValue_String" SG_ 372 ADAS_LDW_Sta "0x0";
BA_ "GenSigSendType" SG_ 372 ADAS_LDW_Sta 3;
BA_ "DataCenterDataType" SG_ 372 ADAS_LDW_Sta "varchar(25)";
BA_ "GenSigRoutingTimeoutValue_String" SG_ 372 ADAS_LFC_Sta "0x0";
BA_ "GenSigSendType" SG_ 372 ADAS_LFC_Sta 3;
BA_ "DataCenterDataType" SG_ 372 ADAS_LFC_Sta "varchar(25)";
BA_ "GenSigRoutingTimeoutValue_String" SG_ 372 ADAS_LKA_Sta "0x0";
BA_ "GenSigSendType" SG_ 372 ADAS_LKA_Sta 3;
BA_ "DataCenterDataType" SG_ 372 ADAS_LKA_Sta "varchar(25)";
BA_ "GenSigRoutingTimeoutValue_String" SG_ 372 ADAS_SLIF_Sta "0x0";
BA_ "GenSigSendType" SG_ 372 ADAS_SLIF_Sta 3;
BA_ "DataCenterDataType" SG_ 372 ADAS_SLIF_Sta "varchar(25)";
BA_ "GenSigRoutingTimeoutValue_String" SG_ 372 ADAS_LFC_Hands_Off_Warning "0x0";
BA_ "GenSigSendType" SG_ 372 ADAS_LFC_Hands_Off_Warning 3;
BA_ "GenSigRoutingTimeoutValue_String" SG_ 372 ACC_TakeoverReq "0x0";
BA_ "GenSigSendType" SG_ 372 ACC_TakeoverReq 3;
BA_ "GenSigRoutingTimeoutValue_String" SG_ 372 ActBrkLamp_Sta "0x0";
BA_ "GenSigSendType" SG_ 372 ActBrkLamp_Sta 3;
BA_ "GenSigRoutingTimeoutValue_String" SG_ 372 ADAS_FCW_Mute "0x0";
BA_ "GenSigSendType" SG_ 372 ADAS_FCW_Mute 3;
BA_ "GenSigRoutingTimeoutValue_String" SG_ 372 ADAS_FltWrnReq "0x0";
BA_ "GenSigSendType" SG_ 372 ADAS_FltWrnReq 3;
BA_ "DataCenterDataType" SG_ 372 ADAS_FltWrnReq "Varchar(20)";
BA_ "GenSigRoutingTimeoutValue_String" SG_ 372 ADAS_LDW_Mute "0x0";
BA_ "GenSigSendType" SG_ 372 ADAS_LDW_Mute 3;
BA_ "GenSigInvalidValue" SG_ 372 LVDA_Mute_Sta 3;
BA_ "GenSigRoutingTimeoutValue_String" SG_ 372 LVDA_Mute_Sta "0x0";
BA_ "GenSigSendType" SG_ 372 LVDA_Mute_Sta 3;
BA_ "GenSigRoutingTimeoutValue_String" SG_ 372 LKA_HOD_Display_Warning "0x0";
BA_ "GenSigSendType" SG_ 372 LKA_HOD_Display_Warning 3;
BA_ "GenSigRoutingTimeoutValue_String" SG_ 372 LKA_HOD_Sound_Warning "0x0";
BA_ "GenSigSendType" SG_ 372 LKA_HOD_Sound_Warning 3;
BA_ "GenSigRoutingTimeoutValue_String" SG_ 372 LVDA_ACCStatusInformation "0x0";
BA_ "GenSigSendType" SG_ 372 LVDA_ACCStatusInformation 3;
BA_ "GenSigRoutingTimeoutValue_String" SG_ 372 LVDA_Disabled "0x0";
BA_ "GenSigSendType" SG_ 372 LVDA_Disabled 3;
BA_ "GenSigRoutingTimeoutValue_String" SG_ 372 LVDA_Failinfo "0x0";
BA_ "GenSigSendType" SG_ 372 LVDA_Failinfo 3;
BA_ "GenSigRoutingTimeoutValue_String" SG_ 372 LVDA_Warning "0x0";
BA_ "GenSigSendType" SG_ 372 LVDA_Warning 3;
BA_ "GenSigInvalidValue" SG_ 372 ISA_WarningMsg 6;
BA_ "GenSigRoutingTimeoutValue_String" SG_ 372 ISA_WarningMsg "0x6";
BA_ "GenSigRoutingTimeoutValue" SG_ 372 ISA_WarningMsg 6;
BA_ "GenSigSendType" SG_ 372 ISA_WarningMsg 3;
BA_ "GenSigInvalidValue" SG_ 372 ForceLowBeam 2;
BA_ "GenSigRoutingTimeoutValue_String" SG_ 372 ForceLowBeam "0x2";
BA_ "GenSigRoutingTimeoutValue" SG_ 372 ForceLowBeam 2;
BA_ "GenSigSendType" SG_ 372 ForceLowBeam 3;
BA_ "GenSigRoutingTimeoutValue_String" SG_ 372 CameraBlockage "0x0";
BA_ "GenSigSendType" SG_ 372 CameraBlockage 3;
BA_ "GenSigRoutingTimeoutValue_String" SG_ 372 HazardWarningReq "0x0";
BA_ "GenSigSendType" SG_ 372 HazardWarningReq 3;
BA_ "GenSigRoutingTimeoutValue_String" SG_ 372 LeftTurnLightReq "0x0";
BA_ "GenSigSendType" SG_ 372 LeftTurnLightReq 3;
BA_ "GenSigRoutingTimeoutValue_String" SG_ 372 Target_Type "0x0";
BA_ "GenSigSendType" SG_ 372 Target_Type 3;
BA_ "GenSigRoutingTimeoutValue_String" SG_ 372 RightTurnLightReq "0x0";
BA_ "GenSigSendType" SG_ 372 RightTurnLightReq 3;
BA_ "GenSigRoutingTimeoutValue_String" SG_ 372 ADAS_FCW_Sensitivity "0x0";
BA_ "GenSigSendType" SG_ 372 ADAS_FCW_Sensitivity 3;
BA_ "GenSigRoutingTimeoutValue_String" SG_ 372 ADAS_LDW_Sensitivity "0x0";
BA_ "GenSigSendType" SG_ 372 ADAS_LDW_Sensitivity 3;
BA_ "GenSigInvalidValue" SG_ 372 MCU_B_R_RealPwrKw_Sta 65535;
BA_ "GenSigStartValue" SG_ 372 MCU_B_R_RealPwrKw_Sta 5300;
BA_ "GenSigRoutingTimeoutValue_String" SG_ 372 MCU_B_R_RealPwrKw_Sta "0xFFFF";
BA_ "GenSigInactiveValue" SG_ 372 MCU_B_R_RealPwrKw_Sta 5300;
BA_ "GenSigRoutingTimeoutValue" SG_ 372 MCU_B_R_RealPwrKw_Sta 65535;
BA_ "GenSigInvalidValue" SG_ 372 MCU_B_F_RealPwrKw_Sta 65535;
BA_ "GenSigStartValue" SG_ 372 MCU_B_F_RealPwrKw_Sta 5300;
BA_ "GenSigRoutingTimeoutValue_String" SG_ 372 MCU_B_F_RealPwrKw_Sta "0xFFFF";
BA_ "GenSigInactiveValue" SG_ 372 MCU_B_F_RealPwrKw_Sta 5300;
BA_ "GenSigRoutingTimeoutValue" SG_ 372 MCU_B_F_RealPwrKw_Sta 65535;
BA_ "GenSigInvalidValue" SG_ 372 HVBSOH 255;
BA_ "GenSigRoutingTimeoutValue_String" SG_ 372 HVBSOH "0xFF";
BA_ "GenSigRoutingTimeoutValue" SG_ 372 HVBSOH 255;
BA_ "DataCenterDataType" SG_ 372 HVBSOH "Decimal";
BA_ "GenSigRoutingTimeoutValue_String" SG_ 372 FDC_BCM_TimeGapLevel_Sta "0x0";
BA_ "GenSigSendType" SG_ 372 FDC_BCM_TimeGapLevel_Sta 3;
BA_ "GenSigStartValue" SG_ 372 HVBPwrAvailChrg 1500;
BA_ "DataCenterDataType" SG_ 372 HVBPwrAvailChrg "Decimal";
BA_ "GenSigStartValue" SG_ 372 HVBPwrAvailChrg60 1500;
BA_ "GenSigInvalidValue" SG_ 372 HVBFullChrgPwr 1023;
BA_ "GenSigInvalidValue" SG_ 450 HVBChrgErr 255;
BA_ "GenSigRoutingTimeoutValue_String" SG_ 450 HVBChrgErr "0xFF";
BA_ "GenSigInactiveValue" SG_ 450 HVBChrgErr 255;
BA_ "GenSigRoutingTimeoutValue" SG_ 450 HVBChrgErr 255;
BA_ "GenSigSendType" SG_ 450 HVBChrgErr 3;
BA_ "GenSigInvalidValue" SG_ 450 V2LSta 3;
BA_ "GenSigRoutingTimeoutValue_String" SG_ 450 V2LSta "0x3";
BA_ "GenSigInactiveValue" SG_ 450 V2LSta 3;
BA_ "GenSigRoutingTimeoutValue" SG_ 450 V2LSta 3;
BA_ "GenSigSendType" SG_ 450 V2LSta 3;
BA_ "GenSigSendType" SG_ 450 DisChrgPlugErr 3;
BA_ "GenSigRoutingTimeoutValue_String" SG_ 450 ExtChrgSta "0x3";
BA_ "GenSigRoutingTimeoutValue" SG_ 450 ExtChrgSta 3;
BA_ "GenSigSendType" SG_ 450 ExtChrgSta 3;
BA_ "DataCenterDataType" SG_ 450 ExtChrgSta "Varchar(20)";
BA_ "GenSigRoutingTimeoutValue_String" SG_ 450 ChrgPlugSta "0x0";
BA_ "GenSigSendType" SG_ 450 ChrgPlugSta 3;
BA_ "DataCenterDataType" SG_ 450 ChrgPlugSta "Varchar(20)";
BA_ "GenSigSendType" SG_ 450 HVBOvrTempErr 3;
BA_ "GenSigSendType" SG_ 450 OBC_AC_Cur_Lim 3;
BA_ "GenSigSendType" SG_ 450 HVBOvrTempWarn 3;
BA_ "GenSigRoutingTimeoutValue_String" SG_ 450 Shifter_Fail_sta "0x3";
BA_ "GenSigRoutingTimeoutValue" SG_ 450 Shifter_Fail_sta 3;
BA_ "GenSigSendType" SG_ 450 Shifter_Fail_sta 3;
BA_ "GenSigInvalidValue" SG_ 450 Shifter_Handle_Cmd 255;
BA_ "GenSigRoutingTimeoutValue_String" SG_ 450 Shifter_Handle_Cmd "0xFF";
BA_ "GenSigRoutingTimeoutValue" SG_ 450 Shifter_Handle_Cmd 255;
BA_ "GenSigSendType" SG_ 450 Shifter_Handle_Cmd 3;
BA_ "GenSigInvalidValue" SG_ 450 OBCACVoltInf 4095;
BA_ "GenSigRoutingTimeoutValue_String" SG_ 450 OBCACVoltInf "0xFFF";
BA_ "GenSigInactiveValue" SG_ 450 OBCACVoltInf 4095;
BA_ "GenSigRoutingTimeoutValue" SG_ 450 OBCACVoltInf 4095;
BA_ "GenSigSendType" SG_ 450 OBCFaultSta 3;
BA_ "GenSigStartValue" SG_ 450 OBCACCurrInf 40;
BA_ "GenSigInvalidValue" SG_ 450 FrntPTCLeActHeatPwr 255;
BA_ "GenSigStartValue" SG_ 450 FrntPTCLeActHeatPwr 255;
BA_ "GenSigRoutingTimeoutValue_String" SG_ 450 FrntPTCLeActHeatPwr "0xFF";
BA_ "GenSigInactiveValue" SG_ 450 FrntPTCLeActHeatPwr 255;
BA_ "GenSigRoutingTimeoutValue" SG_ 450 FrntPTCLeActHeatPwr 255;
BA_ "DataCenterDataType" SG_ 450 FrntPTCLeActHeatPwr "INT(4)";
BA_ "GenSigInvalidValue" SG_ 450 FrntPTCRiActHeatPwr 255;
BA_ "GenSigStartValue" SG_ 450 FrntPTCRiActHeatPwr 255;
BA_ "GenSigRoutingTimeoutValue_String" SG_ 450 FrntPTCRiActHeatPwr "0xFF";
BA_ "GenSigInactiveValue" SG_ 450 FrntPTCRiActHeatPwr 255;
BA_ "GenSigRoutingTimeoutValue" SG_ 450 FrntPTCRiActHeatPwr 255;
BA_ "DataCenterDataType" SG_ 450 FrntPTCRiActHeatPwr "INT(4)";
BA_ "GenSigInvalidValue" SG_ 450 FrntPTCRearLeActHeatPwr 255;
BA_ "GenSigStartValue" SG_ 450 FrntPTCRearLeActHeatPwr 255;
BA_ "GenSigRoutingTimeoutValue_String" SG_ 450 FrntPTCRearLeActHeatPwr "0xFF";
BA_ "GenSigInactiveValue" SG_ 450 FrntPTCRearLeActHeatPwr 255;
BA_ "GenSigRoutingTimeoutValue" SG_ 450 FrntPTCRearLeActHeatPwr 255;
BA_ "DataCenterDataType" SG_ 450 FrntPTCRearLeActHeatPwr "INT(4)";
BA_ "GenSigInvalidValue" SG_ 450 FrntPTCRearRiActHeatPwr 255;
BA_ "GenSigStartValue" SG_ 450 FrntPTCRearRiActHeatPwr 255;
BA_ "GenSigRoutingTimeoutValue_String" SG_ 450 FrntPTCRearRiActHeatPwr "0xFF";
BA_ "GenSigInactiveValue" SG_ 450 FrntPTCRearRiActHeatPwr 255;
BA_ "GenSigRoutingTimeoutValue" SG_ 450 FrntPTCRearRiActHeatPwr 255;
BA_ "DataCenterDataType" SG_ 450 FrntPTCRearRiActHeatPwr "INT(4)";
BA_ "GenSigSendType" SG_ 450 HVBContactorSta 3;
BA_ "GenSigSendType" SG_ 450 RLS_Lamp_Sta 3;
BA_ "GenSigSendType" SG_ 450 SWC_ACC_Sta 3;
BA_ "GenSigSendType" SG_ 450 SWC_Down_Sta 3;
BA_ "GenSigSendType" SG_ 450 SWC_RegenUp 3;
BA_ "GenSigSendType" SG_ 450 SWC_Left_Sta 3;
BA_ "GenSigSendType" SG_ 450 SWC_mode_Sta 3;
BA_ "GenSigSendType" SG_ 450 SWC_Right_Sta 3;
BA_ "GenSigSendType" SG_ 450 SWC_Trip_Sta 3;
BA_ "GenSigSendType" SG_ 450 SWC_Up_Sta 3;
BA_ "GenSigSendType" SG_ 450 SWC_LKA_Sta 3;
BA_ "GenSigSendType" SG_ 450 SWC_Undefined_Sta 3;
BA_ "GenSigSendType" SG_ 450 SWC_VR_Sta 3;
BA_ "GenSigSendType" SG_ 450 ChargeInletLockSta 3;
BA_ "DataCenterDataType" SG_ 450 ChargeInletLockSta "Varchar(7)";
BA_ "GenSigInvalidValue" SG_ 450 COMP_ActualPwr 8191;
BA_ "GenSigStartValue" SG_ 450 COMP_ActualPwr 8191;
BA_ "GenSigRoutingTimeoutValue_String" SG_ 450 COMP_ActualPwr "0x1FFF";
BA_ "GenSigInactiveValue" SG_ 450 COMP_ActualPwr 8191;
BA_ "GenSigRoutingTimeoutValue" SG_ 450 COMP_ActualPwr 8191;
BA_ "DataCenterDataType" SG_ 450 COMP_ActualPwr "Varchar(10)";
BA_ "GenSigSendType" SG_ 450 MainRlyPosSta 3;
BA_ "DataCenterDataType" SG_ 450 MainRlyPosSta "Varchar(20)";
BA_ "GenSigSendType" SG_ 450 MainRlyNegSta 3;
BA_ "DataCenterDataType" SG_ 450 MainRlyNegSta "Varchar(20)";
BA_ "GenSigSendType" SG_ 450 P_Dkey_Show_IVI 3;
BA_ "GenSigSendType" SG_ 450 P_KeyMiss 3;
BA_ "GenSigSendType" SG_ 450 P_UID_LowPower 3;
BA_ "DataCenterDataType" SG_ 450 P_UID_LowPower "Varchar(10)";
BA_ "GenSigInvalidValue" SG_ 450 HVBMTempMax 255;
BA_ "GenSigStartValue" SG_ 450 HVBMTempMax 40;
BA_ "GenSigRoutingTimeoutValue_String" SG_ 450 HVBMTempMax "0xFF";
BA_ "GenSigInactiveValue" SG_ 450 HVBMTempMax 255;
BA_ "GenSigRoutingTimeoutValue" SG_ 450 HVBMTempMax 255;
BA_ "DataCenterDataType" SG_ 450 HVBMTempMax "INT(3)";
BA_ "GenSigRoutingTimeoutValue_String" SG_ 450 TBOX_NET_SIG_STR "0x0";
BA_ "GenSigSendType" SG_ 450 TBOX_NET_SIG_STR 3;
BA_ "DataCenterDataType" SG_ 450 TBOX_NET_SIG_STR "Varchar(20)";
BA_ "GenSigInvalidValue" SG_ 450 TBOX_TEST_STATUS 15;
BA_ "GenSigStartValue" SG_ 450 TBOX_TEST_STATUS 15;
BA_ "GenSigRoutingTimeoutValue_String" SG_ 450 TBOX_TEST_STATUS "0xF";
BA_ "GenSigInactiveValue" SG_ 450 TBOX_TEST_STATUS 15;
BA_ "GenSigRoutingTimeoutValue" SG_ 450 TBOX_TEST_STATUS 15;
BA_ "GenSigSendType" SG_ 450 TBOX_TEST_STATUS 3;
BA_ "DataCenterDataType" SG_ 450 TBOX_TEST_STATUS "Varchar(30)";
BA_ "GenSigInvalidValue" SG_ 450 CbnPreACEnaReq 3;
BA_ "GenSigRoutingTimeoutValue_String" SG_ 450 CbnPreACEnaReq "0x3";
BA_ "GenSigRoutingTimeoutValue" SG_ 450 CbnPreACEnaReq 3;
BA_ "GenSigSendType" SG_ 450 CbnPreACEnaReq 3;
BA_ "GenSigSendType" SG_ 450 Re_Radio 3;
BA_ "GenSigSendType" SG_ 450 TrailerModeSta 3;
BA_ "GenSigSendType" SG_ 450 TrailerCheck 3;
BA_ "GenSigSendType" SG_ 450 SWC_RegenDown 3;
BA_ "GenSigInvalidValue" SG_ 450 FDC_BCM_FWipSw_Sta 7;
BA_ "GenSigStartValue" SG_ 450 FDC_BCM_FWipSw_Sta 7;
BA_ "GenSigRoutingTimeoutValue_String" SG_ 450 FDC_BCM_FWipSw_Sta "0x7";
BA_ "GenSigInactiveValue" SG_ 450 FDC_BCM_FWipSw_Sta 7;
BA_ "GenSigRoutingTimeoutValue" SG_ 450 FDC_BCM_FWipSw_Sta 7;
BA_ "GenSigSendType" SG_ 450 FDC_BCM_FWipSw_Sta 3;
BA_ "GenSigInvalidValue" SG_ 450 FDC_BCM_TurnSw_Sta 3;
BA_ "GenSigStartValue" SG_ 450 FDC_BCM_TurnSw_Sta 3;
BA_ "GenSigRoutingTimeoutValue_String" SG_ 450 FDC_BCM_TurnSw_Sta "0x3";
BA_ "GenSigInactiveValue" SG_ 450 FDC_BCM_TurnSw_Sta 3;
BA_ "GenSigRoutingTimeoutValue" SG_ 450 FDC_BCM_TurnSw_Sta 3;
BA_ "GenSigSendType" SG_ 450 FDC_BCM_TurnSw_Sta 3;
BA_ "GenSigSendType" SG_ 450 FDC_BCM_DimSw 3;
BA_ "GenSigInvalidValue" SG_ 450 OBCACCSLimit 255;
BA_ "GenSigStartValue" SG_ 450 OBCACCSLimit 255;
BA_ "GenSigRoutingTimeoutValue_String" SG_ 450 OBCACCSLimit "0xFF";
BA_ "GenSigInactiveValue" SG_ 450 OBCACCSLimit 255;
BA_ "GenSigRoutingTimeoutValue" SG_ 450 OBCACCSLimit 255;
BA_ "GenSigSendType" SG_ 450 OBCACCSLimit 3;
BA_ "GenSigRoutingTimeoutValue_String" SG_ 450 ZFR_BCM_ChargerDoorSW_Sta "0x0";
BA_ "GenSigSendType" SG_ 450 ZFR_BCM_ChargerDoorSW_Sta 3;
BA_ "GenSigSendType" SG_ 450 DKC_KeyType_Sta 3;
BA_ "GenSigInvalidValue" SG_ 450 DKC_KeyNum_Sta 15;
BA_ "GenSigRoutingTimeoutValue_String" SG_ 450 DKC_KeyNum_Sta "0x0";
BA_ "GenSigSendType" SG_ 450 DKC_KeyNum_Sta 3;
BA_ "GenSigRoutingTimeoutValue_String" SG_ 450 ZFR_EChrg_Active_Sta "0x0";
BA_ "GenSigSendType" SG_ 450 ZFR_EChrg_Active_Sta 3;
BA_ "GenSigInvalidValue" SG_ 450 ZFR_EChrg_Sys_Sta 3;
BA_ "GenSigRoutingTimeoutValue_String" SG_ 450 ZFR_EChrg_Sys_Sta "0x3";
BA_ "GenSigRoutingTimeoutValue" SG_ 450 ZFR_EChrg_Sys_Sta 3;
BA_ "GenSigSendType" SG_ 450 ZFR_EChrg_Sys_Sta 3;
BA_ "GenSigRoutingTimeoutValue_String" SG_ 450 ZFR_EChrg_OperationDeny_Cmd "0x0";
BA_ "GenSigSendType" SG_ 450 ZFR_EChrg_OperationDeny_Cmd 3;
BA_ "GenSigRoutingTimeoutValue_String" SG_ 450 ZFR_EChrg_WashMode_Sta "0x0";
BA_ "GenSigSendType" SG_ 450 ZFR_EChrg_WashMode_Sta 3;
BA_ "GenSigInvalidValue" SG_ 450 EBMSta 7;
BA_ "GenSigRoutingTimeoutValue_String" SG_ 450 EBMSta "0x7";
BA_ "GenSigRoutingTimeoutValue" SG_ 450 EBMSta 7;
BA_ "GenSigSendType" SG_ 450 EBMSta 3;
BA_ "GenSigRoutingTimeoutValue_String" SG_ 528 APS_Sta_System "0x0";
BA_ "GenSigInvalidValue" SG_ 528 FDC_VCU_RegenMode_Sta 7;
BA_ "GenSigRoutingTimeoutValue_String" SG_ 528 FDC_VCU_RegenMode_Sta "0x7";
BA_ "GenSigInactiveValue" SG_ 528 FDC_VCU_RegenMode_Sta 7;
BA_ "GenSigRoutingTimeoutValue" SG_ 528 FDC_VCU_RegenMode_Sta 7;
BA_ "GenSigInvalidValue" SG_ 528 FDC_VMC_SpdCtrlMode_Sta 5;
BA_ "GenSigRoutingTimeoutValue_String" SG_ 528 FDC_VMC_SpdCtrlMode_Sta "0x5";
BA_ "GenSigRoutingTimeoutValue" SG_ 528 FDC_VMC_SpdCtrlMode_Sta 5;
BA_ "DataCenterDataType" SG_ 528 FDC_VMC_SpdCtrlMode_Sta "varchar(25)";
BA_ "GenSigInvalidValue" SG_ 528 VMC_VCU_CC_Crl_Sta 6;
BA_ "GenSigInvalidValue" SG_ 528 VMC_VCU_MSA_Crl_Sta 6;
BA_ "GenSigInvalidValue" SG_ 528 DISC_DISCTargetSpd 4095;
BA_ "GenSigRoutingTimeoutValue_String" SG_ 528 DISC_DISCTargetSpd "0xFFF";
BA_ "GenSigRoutingTimeoutValue" SG_ 528 DISC_DISCTargetSpd 4095;
BA_ "GenSigInvalidValue" SG_ 528 FDC_VCU_SimSound_Cmd 4095;
BA_ "GenSigStartValue" SG_ 528 FDC_VCU_SimSound_Cmd 2047;
BA_ "GenSigRoutingTimeoutValue_String" SG_ 528 FDC_VCU_SimSound_Cmd "0xFFF";
BA_ "GenSigInactiveValue" SG_ 528 FDC_VCU_SimSound_Cmd 4095;
BA_ "GenSigRoutingTimeoutValue" SG_ 528 FDC_VCU_SimSound_Cmd 4095;
BA_ "GenSigInvalidValue" SG_ 823 ACChrgCurrDis 32767;
BA_ "GenSigStartValue" SG_ 823 ACChrgCurrDis 10000;
BA_ "GenSigRoutingTimeoutValue_String" SG_ 823 ACChrgCurrDis "0x7FFF";
BA_ "GenSigInactiveValue" SG_ 823 ACChrgCurrDis 32767;
BA_ "GenSigRoutingTimeoutValue" SG_ 823 ACChrgCurrDis 32767;
BA_ "GenSigInvalidValue" SG_ 823 RemainChrgTime 4095;
BA_ "GenSigRoutingTimeoutValue_String" SG_ 823 RemainChrgTime "0xFFF";
BA_ "GenSigInactiveValue" SG_ 823 RemainChrgTime 4095;
BA_ "GenSigRoutingTimeoutValue" SG_ 823 RemainChrgTime 4095;
BA_ "DataCenterDataType" SG_ 823 RemainChrgTime "Varchar(7)";
BA_ "GenSigInvalidValue" SG_ 823 HVBChrgPwr 1023;
BA_ "GenSigRoutingTimeoutValue_String" SG_ 823 HVBChrgPwr "0x3FF";
BA_ "GenSigInactiveValue" SG_ 823 HVBChrgPwr 1023;
BA_ "GenSigRoutingTimeoutValue" SG_ 823 HVBChrgPwr 1023;
BA_ "DataCenterDataType" SG_ 823 HVBChrgPwr "Decimal";
BA_ "GenSigInvalidValue" SG_ 823 HVBattSOCDis 255;
BA_ "GenSigRoutingTimeoutValue_String" SG_ 823 HVBattSOCDis "0xFF";
BA_ "GenSigInactiveValue" SG_ 823 HVBattSOCDis 255;
BA_ "GenSigRoutingTimeoutValue" SG_ 823 HVBattSOCDis 255;
BA_ "DataCenterDataType" SG_ 823 HVBattSOCDis "Decimal";
BA_ "GenSigInvalidValue" SG_ 823 HVBattSOC 255;
BA_ "GenSigRoutingTimeoutValue_String" SG_ 823 HVBattSOC "0xFF";
BA_ "GenSigInactiveValue" SG_ 823 HVBattSOC 255;
BA_ "GenSigRoutingTimeoutValue" SG_ 823 HVBattSOC 255;
BA_ "DataCenterDataType" SG_ 823 HVBattSOC "Decimal";
BA_ "GenSigInvalidValue" SG_ 823 Charge_Percent_Set 101;
BA_ "GenSigStartValue" SG_ 823 Charge_Percent_Set 100;
BA_ "GenSigRoutingTimeoutValue_String" SG_ 823 Charge_Percent_Set "0x65";
BA_ "GenSigRoutingTimeoutValue" SG_ 823 Charge_Percent_Set 101;
BA_ "GenSigSendType" SG_ 823 Charge_Percent_Set 3;
BA_ "DataCenterDataType" SG_ 823 HVBChrgPwrTotal "INT(6)";
BA_ "DataCenterDataType" SG_ 823 HVBDrvPwrTotal "INT(6)";
BA_ "GenSigInvalidValue" SG_ 823 HVBDrvPwr 1023;
BA_ "DataCenterDataType" SG_ 823 HVBDrvPwr "Decimal";
BA_ "GenSigSendType" SG_ 1077 TPMSWarnIndi 3;
BA_ "DataCenterDataType" SG_ 1077 TPMSWarnIndi "Varchar(20)";
BA_ "GenSigSendType" SG_ 1077 TPMS_Res_Butt_Allow 3;
BA_ "GenSigInvalidValue" SG_ 1077 AutoLTips 3;
BA_ "GenSigRoutingTimeoutValue_String" SG_ 1077 AutoLTips "0x3";
BA_ "GenSigRoutingTimeoutValue" SG_ 1077 AutoLTips 3;
BA_ "GenSigSendType" SG_ 1077 AutoLTips 3;
BA_ "GenSigSendType" SG_ 1077 TPMS_Cali_Butt_Allow 3;
BA_ "GenSigInvalidValue" SG_ 1077 CWheelTips 3;
BA_ "GenSigRoutingTimeoutValue_String" SG_ 1077 CWheelTips "0x3";
BA_ "GenSigRoutingTimeoutValue" SG_ 1077 CWheelTips 3;
BA_ "GenSigSendType" SG_ 1077 CWheelTips 3;
BA_ "GenSigInvalidValue" SG_ 1077 LRWheelTemp 255;
BA_ "GenSigRoutingTimeoutValue_String" SG_ 1077 LRWheelTemp "0xFF";
BA_ "GenSigInactiveValue" SG_ 1077 LRWheelTemp 255;
BA_ "GenSigRoutingTimeoutValue" SG_ 1077 LRWheelTemp 255;
BA_ "GenSigSendType" SG_ 1077 LRWheelTemp 3;
BA_ "GenSigInvalidValue" SG_ 1077 RRWheelTemp 255;
BA_ "GenSigRoutingTimeoutValue_String" SG_ 1077 RRWheelTemp "0xFF";
BA_ "GenSigInactiveValue" SG_ 1077 RRWheelTemp 255;
BA_ "GenSigRoutingTimeoutValue" SG_ 1077 RRWheelTemp 255;
BA_ "GenSigSendType" SG_ 1077 RRWheelTemp 3;
BA_ "GenSigInvalidValue" SG_ 1077 LFWheelTemp 255;
BA_ "GenSigRoutingTimeoutValue_String" SG_ 1077 LFWheelTemp "0xFF";
BA_ "GenSigInactiveValue" SG_ 1077 LFWheelTemp 255;
BA_ "GenSigRoutingTimeoutValue" SG_ 1077 LFWheelTemp 255;
BA_ "GenSigSendType" SG_ 1077 LFWheelTemp 3;
BA_ "GenSigInvalidValue" SG_ 1077 RFWheelTemp 255;
BA_ "GenSigRoutingTimeoutValue_String" SG_ 1077 RFWheelTemp "0xFF";
BA_ "GenSigInactiveValue" SG_ 1077 RFWheelTemp 255;
BA_ "GenSigRoutingTimeoutValue" SG_ 1077 RFWheelTemp 255;
BA_ "GenSigSendType" SG_ 1077 RFWheelTemp 3;
BA_ "GenSigSendType" SG_ 1077 LRWheelPress 3;
BA_ "DataCenterDataType" SG_ 1077 LRWheelPress "Decimal";
BA_ "GenSigSendType" SG_ 1077 RRWheelPress 3;
BA_ "DataCenterDataType" SG_ 1077 RRWheelPress "Decimal";
BA_ "GenSigSendType" SG_ 1077 LFWheelPress 3;
BA_ "DataCenterDataType" SG_ 1077 LFWheelPress "Decimal";
BA_ "GenSigSendType" SG_ 1077 RFWheelPress 3;
BA_ "DataCenterDataType" SG_ 1077 RFWheelPress "Decimal";
BA_ "GenSigSendType" SG_ 1077 LRWheelDebug 3;
BA_ "GenSigSendType" SG_ 1077 RRWheelDebug 3;
BA_ "GenSigSendType" SG_ 1077 LFWheelDebug 3;
BA_ "GenSigSendType" SG_ 1077 RFWheelDebug 3;
BA_ "GenSigSendType" SG_ 1077 LRBatWarn 3;
BA_ "DataCenterDataType" SG_ 1077 LRBatWarn "Varchar(7)";
BA_ "GenSigSendType" SG_ 1077 RRBatWarn 3;
BA_ "DataCenterDataType" SG_ 1077 RRBatWarn "Varchar(7)";
BA_ "GenSigSendType" SG_ 1077 LFBatWarn 3;
BA_ "DataCenterDataType" SG_ 1077 LFBatWarn "Varchar(7)";
BA_ "GenSigSendType" SG_ 1077 RFBatWarn 3;
BA_ "DataCenterDataType" SG_ 1077 RFBatWarn "Varchar(7)";
BA_ "GenSigSendType" SG_ 1077 LRSensorFail 3;
BA_ "DataCenterDataType" SG_ 1077 LRSensorFail "Varchar(7)";
BA_ "GenSigSendType" SG_ 1077 RRSensorFail 3;
BA_ "DataCenterDataType" SG_ 1077 RRSensorFail "Varchar(7)";
BA_ "GenSigSendType" SG_ 1077 LFSensorFail 3;
BA_ "DataCenterDataType" SG_ 1077 LFSensorFail "Varchar(7)";
BA_ "GenSigSendType" SG_ 1077 RFSensorFail 3;
BA_ "DataCenterDataType" SG_ 1077 RFSensorFail "Varchar(7)";
BA_ "GenSigSendType" SG_ 1077 LRWheelTmpIndi 3;
BA_ "GenSigSendType" SG_ 1077 RRWheelTmpIndi 3;
BA_ "GenSigSendType" SG_ 1077 LFWheelTmpIndi 3;
BA_ "GenSigSendType" SG_ 1077 RFWheelTmpIndi 3;
BA_ "GenSigInvalidValue" SG_ 1077 LRPressIndi 3;
BA_ "GenSigRoutingTimeoutValue_String" SG_ 1077 LRPressIndi "0x3";
BA_ "GenSigRoutingTimeoutValue" SG_ 1077 LRPressIndi 3;
BA_ "GenSigSendType" SG_ 1077 LRPressIndi 3;
BA_ "DataCenterDataType" SG_ 1077 LRPressIndi "Varchar(20)";
BA_ "GenSigInvalidValue" SG_ 1077 RRPressIndi 3;
BA_ "GenSigRoutingTimeoutValue_String" SG_ 1077 RRPressIndi "0x3";
BA_ "GenSigRoutingTimeoutValue" SG_ 1077 RRPressIndi 3;
BA_ "GenSigSendType" SG_ 1077 RRPressIndi 3;
BA_ "DataCenterDataType" SG_ 1077 RRPressIndi "Varchar(20)";
BA_ "GenSigInvalidValue" SG_ 1077 LFPressIndi 3;
BA_ "GenSigRoutingTimeoutValue_String" SG_ 1077 LFPressIndi "0x3";
BA_ "GenSigRoutingTimeoutValue" SG_ 1077 LFPressIndi 3;
BA_ "GenSigSendType" SG_ 1077 LFPressIndi 3;
BA_ "DataCenterDataType" SG_ 1077 LFPressIndi "Varchar(20)";
BA_ "GenSigInvalidValue" SG_ 1077 RFPressIndi 3;
BA_ "GenSigRoutingTimeoutValue_String" SG_ 1077 RFPressIndi "0x3";
BA_ "GenSigRoutingTimeoutValue" SG_ 1077 RFPressIndi 3;
BA_ "GenSigSendType" SG_ 1077 RFPressIndi 3;
BA_ "DataCenterDataType" SG_ 1077 RFPressIndi "Varchar(20)";
BA_ "GenSigSendType" SG_ 1077 RRWheelPSW 3;
BA_ "DataCenterDataType" SG_ 1077 RRWheelPSW "Decimal";
BA_ "GenSigSendType" SG_ 1077 RFWheelPSW 3;
BA_ "DataCenterDataType" SG_ 1077 RFWheelPSW "Decimal";
BA_ "GenSigSendType" SG_ 1077 LFWheelPSW 3;
BA_ "DataCenterDataType" SG_ 1077 LFWheelPSW "Decimal";
BA_ "GenSigSendType" SG_ 1077 LRWheelPSW 3;
BA_ "DataCenterDataType" SG_ 1077 LRWheelPSW "Decimal";
BA_ "GenSigSendType" SG_ 1077 LFWheelShield 3;
BA_ "GenSigSendType" SG_ 1077 LRWheelShield 3;
BA_ "GenSigSendType" SG_ 1077 RFWheelShield 3;
BA_ "GenSigSendType" SG_ 1077 RRWheelShield 3;
BA_ "GenSigSendType" SG_ 1077 FDC_BCM_AmbBrightSta_Sta 3;
BA_ "GenSigSendType" SG_ 1077 FDC_BCM_AmbColorSta_Sta 3;
BA_ "GenSigSendType" SG_ 1077 FDC_BCM_AmbDimEN_Sta 3;
BA_ "GenSigSendType" SG_ 1077 FDC_BCM_AmbFunEN_Sta 3;
BA_ "GenSigSendType" SG_ 1077 FDC_BCM_AmbLinkDriSta_Sta 3;
BA_ "GenSigSendType" SG_ 1077 FDC_BCM_AmbODAEN_Sta 3;
BA_ "GenSigSendType" SG_ 1077 FDC_BCM_AmbPwrWarnEN_Sta 3;
BA_ "GenSigSendType" SG_ 1077 FDC_BCM_AmbWelEN_Sta 3;
BA_ "GenSigSendType" SG_ 1077 FDC_BCM_UserNow_Sta 3;
BA_ "GenSigInvalidValue" SG_ 1077 FDC_BCM_TurnSwTSetSta_Sta 3;
BA_ "GenSigStartValue" SG_ 1077 FDC_BCM_TurnSwTSetSta_Sta 3;
BA_ "GenSigRoutingTimeoutValue_String" SG_ 1077 FDC_BCM_TurnSwTSetSta_Sta "0x3";
BA_ "GenSigInactiveValue" SG_ 1077 FDC_BCM_TurnSwTSetSta_Sta 3;
BA_ "GenSigRoutingTimeoutValue" SG_ 1077 FDC_BCM_TurnSwTSetSta_Sta 3;
BA_ "GenSigSendType" SG_ 1077 FDC_BCM_TurnSwTSetSta_Sta 3;
BA_ "GenSigInvalidValue" SG_ 1077 FDC_BCM_PTGOpenHeight_Sta 7;
BA_ "GenSigStartValue" SG_ 1077 FDC_BCM_PTGOpenHeight_Sta 7;
BA_ "GenSigRoutingTimeoutValue_String" SG_ 1077 FDC_BCM_PTGOpenHeight_Sta "0x7";
BA_ "GenSigInactiveValue" SG_ 1077 FDC_BCM_PTGOpenHeight_Sta 7;
BA_ "GenSigRoutingTimeoutValue" SG_ 1077 FDC_BCM_PTGOpenHeight_Sta 7;
BA_ "GenSigSendType" SG_ 1077 FDC_BCM_PTGOpenHeight_Sta 3;
BA_ "GenSigSendType" SG_ 1077 FDC_BCM_LockAlarm_Cmd 3;
BA_ "GenSigSendType" SG_ 1077 FDC_BCM_Acc1Sta_Sta 3;
BA_ "GenSigSendType" SG_ 1077 FDC_BCM_Acc2Sta_Sta 3;
BA_ "GenSigSendType" SG_ 1077 FDC_BCM_Acc3Sta_Sta 3;
BA_ "GenSigSendType" SG_ 1077 FDC_BCM_Acc4Sta_Sta 3;
BA_ "GenSigSendType" SG_ 1077 FDC_BCM_Acc5Sta_Sta 3;
BA_ "GenSigSendType" SG_ 1077 FDC_BCM_Key1Acc_Sta 3;
BA_ "GenSigSendType" SG_ 1077 FDC_BCM_Key2Acc_Sta 3;
BA_ "GenSigSendType" SG_ 1077 FDC_BCM_Key3Acc_Sta 3;
BA_ "GenSigSendType" SG_ 1077 FDC_BCM_Key4Acc_Sta 3;
BA_ "GenSigSendType" SG_ 1077 FDC_BCM_Key5Acc_Sta 3;
BA_ "GenSigSendType" SG_ 1077 FDC_BCM_Key6Acc_Sta 3;
BA_ "GenSigSendType" SG_ 1077 FDC_BCM_Key7Acc_Sta 3;
BA_ "GenSigSendType" SG_ 1077 FDC_BCM_Key8Acc_Sta 3;
BA_ "GenSigSendType" SG_ 1077 FDC_BCM_Key9Acc_Sta 3;
BA_ "GenSigSendType" SG_ 1077 FDC_BCM_Key10Acc_Sta 3;
BA_ "GenSigSendType" SG_ 1077 FDC_BCM_FollowMeENFun_Sta 3;
BA_ "GenSigSendType" SG_ 1077 FDC_BCM_RmLpModeENFun_Sta 3;
BA_ "GenSigSendType" SG_ 1077 FDC_BCM_WalkInUnLkEnFun_Sta 3;
BA_ "GenSigSendType" SG_ 1077 FDC_BCM_WalkOutLkEnFun_Sta 3;
BA_ "GenSigSendType" SG_ 1077 FDC_SPTG_SPTGENFun_Sta 3;
BA_ "GenSigInvalidValue" SG_ 1077 FDC_DKC_DkeyShowIVI_Sta 7;
BA_ "GenSigRoutingTimeoutValue_String" SG_ 1077 FDC_DKC_DkeyShowIVI_Sta "0x7";
BA_ "GenSigRoutingTimeoutValue" SG_ 1077 FDC_DKC_DkeyShowIVI_Sta 7;
BA_ "GenSigSendType" SG_ 1077 FDC_DKC_DkeyShowIVI_Sta 3;
BA_ "GenSigSendType" SG_ 1077 FDC_DKC_KeyMiss_Sta 3;
BA_ "GenSigSendType" SG_ 1077 FDC_DKC_UIDLowPower_Sta 3;
BA_ "GenSigRoutingTimeoutValue_String" SG_ 1077 FDC_FGS_AirInt_Sta "0x0";
BA_ "GenSigSendType" SG_ 1077 FDC_FGS_AirInt_Sta 3;
BA_ "GenSigRoutingTimeoutValue_String" SG_ 1077 FDC_FGS_FGSCh_Sta "0x0";
BA_ "GenSigSendType" SG_ 1077 FDC_FGS_FGSCh_Sta 3;
BA_ "GenSigRoutingTimeoutValue_String" SG_ 1077 FDC_FGS_IONSW_Sta "0x0";
BA_ "GenSigSendType" SG_ 1077 FDC_FGS_IONSW_Sta 3;
BA_ "GenSigSendType" SG_ 1077 FDC_BCM_CLWinLockDr_Sta 3;
BA_ "GenSigRoutingTimeoutValue_String" SG_ 1077 FDC_THCM_APTCWarning_Sta "0x0";
BA_ "GenSigSendType" SG_ 1077 FDC_THCM_APTCWarning_Sta 3;
BA_ "DataCenterDataType" SG_ 1077 FDC_THCM_APTCWarning_Sta "varchar(5)";
BA_ "GenSigRoutingTimeoutValue_String" SG_ 1077 FDC_THCM_APTCForceOFF_Sta "0x0";
BA_ "GenSigSendType" SG_ 1077 FDC_THCM_APTCForceOFF_Sta 3;
BA_ "GenSigInvalidValue" SG_ 1077 FDC_DKC_KeyNum_Sta 15;
BA_ "GenSigRoutingTimeoutValue_String" SG_ 1077 FDC_DKC_KeyNum_Sta "0xF";
BA_ "GenSigRoutingTimeoutValue" SG_ 1077 FDC_DKC_KeyNum_Sta 15;
BA_ "GenSigSendType" SG_ 1077 FDC_DKC_KeyNum_Sta 3;
BA_ "GenSigRoutingTimeoutValue_String" SG_ 1077 FDC_DKC_KeyType_Sta "0x0";
BA_ "GenSigSendType" SG_ 1077 FDC_DKC_KeyType_Sta 3;
BA_ "GenSigRoutingTimeoutValue_String" SG_ 1077 FDC_THCM_AirIntZ3_Sta "0x0";
BA_ "GenSigSendType" SG_ 1077 FDC_THCM_AirIntZ3_Sta 3;
BA_ "GenSigRoutingTimeoutValue_String" SG_ 1077 FDC_BCM_AutoLock_Sta "0x0";
BA_ "GenSigSendType" SG_ 1077 FDC_BCM_AutoLock_Sta 3;
BA_ "GenSigRoutingTimeoutValue_String" SG_ 1077 FDC_BCM_AutoUnlock_Sta "0x0";
BA_ "GenSigSendType" SG_ 1077 FDC_BCM_AutoUnlock_Sta 3;
BA_ "GenSigRoutingTimeoutValue_String" SG_ 1077 FDC_BCM_DSEATentryfset_Sta "0x0";
BA_ "GenSigSendType" SG_ 1077 FDC_BCM_DSEATentryfset_Sta 3;
BA_ "GenSigRoutingTimeoutValue_String" SG_ 1077 FDC_BCM_HBeamADB_Cmd "0x0";
BA_ "GenSigSendType" SG_ 1077 FDC_BCM_HBeamADB_Cmd 3;
BA_ "GenSigSendType" SG_ 1280 NM_FUSION_Node_ID 7;
BA_ "GenSigSendType" SG_ 1280 NM_FUSION_PNI 7;
BA_ "GenSigSendType" SG_ 1280 NM_FUSION_Active_WU 7;
BA_ "GenSigSendType" SG_ 1280 NM_FUSION_CSB 7;
BA_ "GenSigSendType" SG_ 1280 NM_FUSION_Rpt_Msg_Req 7;
BA_ "GenSigSendType" SG_ 1280 NM_FUSION_ERROR_State 7;
BA_ "GenSigSendType" SG_ 1666 DiagPhysReqToMeter 3;
BA_ "GenSigSendType" SG_ 1696 DiagPhysReqToIVI 3;
BA_ "GenSigSendType" SG_ 1714 DiagPhysReqToHMI 3;
BA_ "GenSigSendType" SG_ 2000 DiagFuncReqFT 3;
BA_ "GenSigInvalidValue" SG_ 1080 OTA_Progress_Rate 102;
BA_ "GenSigSendType" SG_ 1080 OTA_Progress_Rate 3;
BA_ "DataCenterDataType" SG_ 1080 OTA_Progress_Rate "array";
BA_ "GenSigSendType" SG_ 1080 OTA_DL_Available 3;
BA_ "GenSigSendType" SG_ 1080 OTA_Mode 3;
BA_ "GenSigSendType" SG_ 1080 OTA_Network_Type 3;
BA_ "GenSigSendType" SG_ 1080 OTA_MDA_Status 3;
BA_ "DataCenterDataType" SG_ 1080 OTA_MDA_Status "array";
BA_ "GenSigInvalidValue" SG_ 1080 OTA_Updating_ECU_8bit 30;
BA_ "GenSigSendType" SG_ 1080 OTA_Updating_ECU_8bit 3;
BA_ "DataCenterDataType" SG_ 1080 OTA_Updating_ECU_8bit "array";
BA_ "GenSigSendType" SG_ 1080 OTA_Update_Available 3;
BA_ "GenSigSendType" SG_ 1080 OTA_InVehicle_FW 3;
BA_ "GenSigSendType" SG_ 1080 OTA_DL_Speed 3;
BA_ "GenSigSendType" SG_ 1080 OTA_TBOXResetReq 3;
BA_ "GenSigSendType" SG_ 1080 OTA_Lock_Req 3;
BA_ "GenSigInvalidValue" SG_ 1080 OTA_Remained_Time 1082;
BA_ "GenSigRoutingTimeoutValue_String" SG_ 1080 OTA_Emergency_Sta "0x0";
BA_ "GenSigSendType" SG_ 1080 OTA_Emergency_Sta 3;
BA_ "DataCenterDataType" SG_ 517 SRR_ODA_Sta "varchar(25)";
BA_ "DataCenterDataType" SG_ 517 SRR_BSD_Sta "varchar(25)";
BA_ "DataCenterDataType" SG_ 517 SRR_RCTA_Sta "varchar(25)";
VAL_ 279 CreepSW_Sta 1 "On" 0 "Off";
VAL_ 279 EngageP_Fail 1 "Fail" 0 "Off";
VAL_ 279 DisengageP_Fail 1 "Fail" 0 "Off";
VAL_ 279 FalseNPrevent_Sta 1 "Enable" 0 "Disable";
VAL_ 279 DynoModeStaChk 2 "Invalid" 1 "Ready" 0 "Not ready";
VAL_ 279 CoastDwModeStaChk 2 "Invalid" 1 "Ready" 0 "Not ready";
VAL_ 279 DemoModeStaChk 2 "Invalid" 1 "Ready" 0 "Not ready";
VAL_ 279 MSA_Crl_Sta 7 "Pedal Override" 6 "Invalid" 5 "Error" 4 "Over Speed" 3 "Under Speed" 2 "Active" 1 "Standby" 0 "Off";
VAL_ 279 CC_Crl_Sta 7 "Pedal Override" 6 "Invalid" 5 "Error" 4 "Over Speed" 3 "Under Speed" 2 "Active" 1 "Standby" 0 "Off";
VAL_ 279 LVChrgFuncStaChk 2 "Invalid" 1 "On" 0 "Off";
VAL_ 279 ShiftGearPosn 7 "Reverse" 6 "Failure" 5 "Drive" 4 "Neutral" 3 "Not used" 2 "Not used" 1 "Invalid" 0 "Park";
VAL_ 279 PwrSta 7 "Invalid" 5 "READY" 4 "ON" 3 "STANDBY" 2 "OFF-After-Run" 1 "OFF-Charging" 0 "OFF";
VAL_ 279 XWDMode 2 "AWD" 1 "FWD" 0 "RWD";
VAL_ 279 CCU_ACLampSts 1 "Lamp ON" 0 "Lamp OFF";
VAL_ 279 CCU_EcoSts 1 "Lamp ON" 0 "Lamp OFF";
VAL_ 279 CCU_AutoMidLampSts 1 "Lamp ON" 0 "Lamp OFF";
VAL_ 279 CCU_AutoLampSts 1 "Lamp ON" 0 "Lamp OFF";
VAL_ 279 CCU_ACMaxLampSts 1 "Lamp ON" 0 "Lamp OFF";
VAL_ 279 CCU_RrOnOffLampSts 1 "Lamp ON" 0 "Lamp OFF";
VAL_ 279 sigWindDirZon1St 7 "NOT Set / Reserved" 6 "All open" 5 "Face + Screen" 4 "DEFOG" 3 "Foot + Screen" 2 "Foot" 1 "Bilevel" 0 "FACE";
VAL_ 279 CCU_FrtOnOffLampSts 1 "Lamp ON" 0 "Lamp OFF";
VAL_ 279 sigWindDirZon3St 7 "NOT Set / Reserved" 6 "All open" 5 "Face + Screen" 4 "DEFOG" 3 "Foot + Screen" 2 "Foot" 1 "Bilevel" 0 "FACE";
VAL_ 279 sigAirIntenZon1St 15 "Invalid" 14 "Reserved" 11 "Reserved" 10 "NOT set" 9 "Level 8" 8 "Level 7" 7 "Level 6" 6 "Level 5" 5 "Level 4" 4 "Level 3" 3 "Level 2" 2 "Level 1" 1 "OFF" 0 "NO display / No request";
VAL_ 279 sigAirIntenZon3St 15 "Invalid" 14 "Reserved" 11 "Reserved" 10 "NOT set" 9 "Level 8" 8 "Level 7" 7 "Level 6" 6 "Level 5" 5 "Level 4" 4 "Level 3" 3 "Level 2" 2 "Level 1" 1 "OFF" 0 "NO display / No request";
VAL_ 279 CCU_SyncLampSts 1 "Lamp ON" 0 "Lamp OFF";
VAL_ 279 sigDfrstSt 1 "ON" 0 "OFF";
VAL_ 279 sigRecircSt 1 "ON" 0 "OFF";
VAL_ 279 sigHvacSt 1 "ON" 0 "OFF";
VAL_ 279 VCUBrkSWSta 2 "Invalid" 1 "On" 0 "OFF";
VAL_ 279 sigAmbAirT 255 "Invalid";
VAL_ 279 FD_AGS_Cmd 208 "78^Deg" 240 "90^Deg" 176 "66^Deg" 144 "54^Deg" 112 "42^Deg" 80 "30^Deg" 48 "18^Deg" 16 "6^Deg" 224 "84^Deg" 192 "72^Deg" 160 "60^Deg" 128 "48^Deg" 96 "36^Deg" 64 "24^Deg" 32 "12^Deg" 0 "0^Deg";
VAL_ 279 SysPwrSta 10 "ON_HVChrg" 9 "OFF-C_LVChrg" 8 "HVChrgPre-action" 7 "Power_down" 6 "Power_up" 5 "READY" 4 "ON_NoChrg" 3 "STANDBY" 2 "OFF-A" 1 "OFF-C_HVChrg" 0 "OFF";
VAL_ 279 MCUActDisFail 1 "Fail" 0 "Normal";
VAL_ 279 PwrStaONTOIVIPopReq 1 "On" 0 "OFF";
VAL_ 279 VCUFLDoorSta 1 "Fail" 0 "Normal";
VAL_ 279 VCUFRDoorSta 1 "Fail" 0 "Normal";
VAL_ 279 VCURLDoorSta 1 "Fail" 0 "Normal";
VAL_ 279 VCURRDoorSta 1 "Fail" 0 "Normal";
VAL_ 279 HVRlyOpFail 1 "Fail" 0 "Normal";
VAL_ 279 SysAllowReadySta 1 "Not allow ready" 0 "Normal";
VAL_ 279 Req_V2LSwOn 1 "Request for V2L plug switch on" 0 "Not request for V2L plug switch on";
VAL_ 279 Req_V2L_IVI_Popup 7 "Request IVI popup 'Stop By Plug in'" 6 "Request IVI popup 'V2L Fault'" 5 "Request IVI popup 'V2L Time up'" 4 "Request IVI popup 'SOC is too low'" 3 "Request IVI popup 'Stop by V2L SOC Set'" 2 "Request IVI popup 'V2L plug-in and V2L SW off'" 1 "Request IVI popup 'Check V2L Plug'" 0 "Not request";
VAL_ 279 DISC_Sta 3 "Disable" 2 "Active" 1 "Standby" 0 "Off";
VAL_ 279 DISC_ButtSta 1 "on" 0 "off";
VAL_ 279 CCMSA_SpdWar 1 "On" 0 "Off";
VAL_ 279 VCUHoodSWSta 1 "Fail" 0 "Normal";
VAL_ 279 VCUTailgateSWSta 1 "Fail" 0 "Normal";
VAL_ 279 FD_EPB_Error 2 "Flash" 1 "On" 0 "Off";
VAL_ 279 FD_Park_Brake_Warning 2 "Flash" 1 "On" 0 "Off";
VAL_ 279 FD_TCS_Indicator 2 "Flash" 1 "On" 0 "Off";
VAL_ 279 FD_ABS_Warning 2 "Flash" 1 "On" 0 "Off";
VAL_ 279 FD_Steering_Warning 2 "Flash" 1 "On" 0 "Off";
VAL_ 279 FD_HV_Battery_Fault 2 "Flash" 1 "On" 0 "Off";
VAL_ 279 FD_EDrive_System 2 "Flash" 1 "On" 0 "Off";
VAL_ 279 FD_Battery_Charge_Warning 2 "Flash" 1 "On" 0 "Off";
VAL_ 279 FD_Power_limitation 2 "Flash" 1 "On" 0 "Off";
VAL_ 279 FD_Telltale_Fail 1 "Telltale fail" 0 "Normal";
VAL_ 279 FeatSetSpdFinal_raw32 19 "Reserved" 18 "Reserved" 17 "Reserved" 16 "Reserved" 15 "Reserved" 14 "Reserved" 13 "Reserved" 12 "Reserved" 11 "Reserved" 10 "Reserved" 9 "Reserved" 8 "Reserved" 7 "Reserved" 6 "Reserved" 5 "Reserved" 4 "Reserved" 3 "Reserved" 2 "Reserved" 1 "Dash Line" 0 "None";
VAL_ 279 Eng_ActvDmpDisabSta 2 "Invalid" 1 "On" 0 "Off";
VAL_ 279 Eng_CoastDwSta 2 "Invalid" 1 "On" 0 "Off";
VAL_ 279 Eng_PwrLockSta 2 "Invalid" 1 "Locked" 0 "Unlocked";
VAL_ 279 EDriveSysErr_AccPedalErr 1 "Error" 0 "Normal";
VAL_ 279 EDriveSysErr_MCUErr 1 "Error" 0 "Normal";
VAL_ 279 EDriveSysErr_ShifterErr 1 "Error" 0 "Normal";
VAL_ 279 EDriveSysErr_VCUErr 1 "Error" 0 "Normal";
VAL_ 279 Eng_AGSCloseSta 1 "Closed" 0 "Auto";
VAL_ 279 VehMalfunLevel 5 "Invalid" 4 "4th grade malfunction" 3 "3rd grade malfunction" 2 "2nd grade malfunction" 1 "1st grade malfunction" 0 "Normal";
VAL_ 279 AntitheftSta 3 "Alarm Status" 2 "Wait for Rearm Status" 1 "Arm Status" 0 "Disarm Status";
VAL_ 279 Dr_SeatSta 2 "Invalid" 1 "Seat occupied" 0 "Seat empty";
VAL_ 279 EVDriveMode 2 "Sport" 1 "Eco" 0 "Normal";
VAL_ 279 AllDoorSW 1 "Any Door Open" 0 "Close";
VAL_ 279 BCM_DoorLock_Sta 1 "Lock" 0 "Unlock";
VAL_ 279 BrakeLamp 1 "On" 0 "Off";
VAL_ 279 DoorLockIND 1 "On" 0 "Off";
VAL_ 279 DrDoorSW 1 "Open" 0 "Close";
VAL_ 279 FollowMe 1 "On" 0 "Off";
VAL_ 279 Fr_FogLamp 1 "On" 0 "Off";
VAL_ 279 HazardSW 1 "On" 0 "Off";
VAL_ 279 HoodSW 1 "Open" 0 "Close";
VAL_ 279 HVSysErr_IsolationErr 1 "Error" 0 "Normal";
VAL_ 279 HVSysErr_PackErr 1 "Error" 0 "Normal";
VAL_ 279 HVSysErr_RelayErr 1 "Error" 0 "Normal";
VAL_ 279 H_Beam 1 "On" 0 "Off";
VAL_ 279 LBSD 1 "On" 0 "Off";
VAL_ 279 LDRL 1 "On" 0 "Off";
VAL_ 279 LimphomeAct 1 "Active" 0 "Inactive";
VAL_ 279 LockSetting 1 "Unlock Single Door" 0 "Unlock All Door";
VAL_ 279 LTurnLP 1 "On" 0 "Off";
VAL_ 279 LVSysErr_PwrOutpErr 1 "Error" 0 "Normal";
VAL_ 279 L_Beam 1 "On" 0 "Off";
VAL_ 279 PAS_Sta_F_Sys 1 "Faliure" 0 "No Faliure";
VAL_ 279 PosLamp 1 "On" 0 "Off";
VAL_ 279 PsDoorSW 1 "Open" 0 "Close";
VAL_ 279 PwrStaErr 1 "Error" 0 "Normal";
VAL_ 279 RBSD 1 "On" 0 "Off";
VAL_ 279 RDRL 1 "On" 0 "Off";
VAL_ 279 ReverseLamp 1 "On" 0 "Off";
VAL_ 279 RLDoorSW 1 "Open" 0 "Close";
VAL_ 279 RRDoorSW 1 "Open" 0 "Close";
VAL_ 279 Rr_Defog 1 "On" 0 "Off";
VAL_ 279 Rr_FogLamp 1 "On" 0 "Off";
VAL_ 279 RTurnLP 1 "On" 0 "Off";
VAL_ 279 Tailgate_SW 1 "Open" 0 "Close";
VAL_ 279 FD_EBMErrSta 2 "Flash" 1 "On" 0 "Off";
VAL_ 279 APMDoorControlSta 1 "ON" 0 "OFF";
VAL_ 279 Req_Internal_V2L_Status_Lamp 3 "Fault" 2 "Working" 1 "Ready" 0 "No request";
VAL_ 279 VCU_OPDHold 1 "On" 0 "Off";
VAL_ 279 DimmerEN 1 "Enable" 0 "Disable";
VAL_ 279 FDC_VCU_PwrSaveReq_Cmd 1 "Request power save" 0 "No request";
VAL_ 279 FDC_THCM_LEVentY_Sta 127 "Invalid" 126 "OFF";
VAL_ 279 FDC_THCM_REVentY_Sta 127 "Invalid" 126 "OFF";
VAL_ 279 FDC_THCM_CLEVentY_Sta 127 "Invalid" 126 "OFF";
VAL_ 279 FDC_THCM_CREVentY_Sta 127 "Invalid" 126 "OFF";
VAL_ 279 FDC_THCM_LEVentZ_Sta 127 "Invalid" 126 "OFF";
VAL_ 279 FDC_THCM_REVentZ_Sta 127 "Invalid" 126 "OFF";
VAL_ 279 FDC_THCM_CLEVentZ_Sta 127 "Invalid" 126 "OFF";
VAL_ 279 FDC_THCM_CREVentZ_Sta 127 "Invalid" 126 "OFF";
VAL_ 279 FDC_THCM_LEVentMode_Sta 3 "Balanced" 2 "Sweep" 1 "Manual" 0 "No Request";
VAL_ 279 FDC_THCM_REVentMode_Sta 3 "Balanced" 2 "Sweep" 1 "Manual" 0 "No Request";
VAL_ 279 FDC_THCM_LVent_Sta 1 "ON" 0 "OFF";
VAL_ 279 FDC_THCM_CLVent_Sta 1 "ON" 0 "OFF";
VAL_ 279 FDC_THCM_RVent_Sta 1 "ON" 0 "OFF";
VAL_ 279 FDC_THCM_CRVent_Sta 1 "ON" 0 "OFF";
VAL_ 279 LVSilentChrgSta 3 "Fault" 2 "Charging completed" 1 "Charging" 0 "No action";
VAL_ 279 FDC_THCM_PreWPTCHeat_Sta 2 "Low Battery Warning" 1 "ON" 0 "OFF";
VAL_ 279 FDC_RAPS_ErrWarn_Sta 2 "RAPS_ErrWarn Lv2" 1 "RAPS_ErrWarn Lv1" 0 "Normal";
VAL_ 279 FDC_V2L_IVIV2LDischarg_Cmd 1 "V2L discharg" 0 "V2L not discharg";
VAL_ 279 FDC_BCM_HMIKey1Func_Sta 15 "Function 6" 14 "Function 5" 13 "Function 4" 12 "Function 3" 11 "Function 2" 10 "Function 1" 9 "Star Button" 8 "Passenger Ventilated and/or heated seats" 7 "Driver Ventilated and/or heated seats" 6 "Rear Defrost" 5 "HVAC Defrost" 4 "IVI Volume" 3 "HVAC Fan Level" 2 "Passenger Seat Temp Set" 1 "Driver Seat Temp Set" 0 "No Request";
VAL_ 279 FDC_BCM_HMIKey2Func_Sta 15 "Function 6" 14 "Function 5" 13 "Function 4" 12 "Function 3" 11 "Function 2" 10 "Function 1" 9 "Star Button" 8 "Passenger Ventilated and/or heated seats" 7 "Driver Ventilated and/or heated seats" 6 "Rear Defrost" 5 "HVAC Defrost" 4 "IVI Volume" 3 "HVAC Fan Level" 2 "Passenger Seat Temp Set" 1 "Driver Seat Temp Set" 0 "No Request";
VAL_ 279 FDC_BCM_HMIKey3Func_Sta 15 "Function 6" 14 "Function 5" 13 "Function 4" 12 "Function 3" 11 "Function 2" 10 "Function 1" 9 "Star Button" 8 "Passenger Ventilated and/or heated seats" 7 "Driver Ventilated and/or heated seats" 6 "Rear Defrost" 5 "HVAC Defrost" 4 "IVI Volume" 3 "HVAC Fan Level" 2 "Passenger Seat Temp Set" 1 "Driver Seat Temp Set" 0 "No Request";
VAL_ 279 FDC_BCM_HMIKey4Func_Sta 15 "Function 6" 14 "Function 5" 13 "Function 4" 12 "Function 3" 11 "Function 2" 10 "Function 1" 9 "Star Button" 8 "Passenger Ventilated and/or heated seats" 7 "Driver Ventilated and/or heated seats" 6 "Rear Defrost" 5 "HVAC Defrost" 4 "IVI Volume" 3 "HVAC Fan Level" 2 "Passenger Seat Temp Set" 1 "Driver Seat Temp Set" 0 "No Request";
VAL_ 279 FDC_BCM_HMIKey5Func_Sta 15 "Function 6" 14 "Function 5" 13 "Function 4" 12 "Function 3" 11 "Function 2" 10 "Function 1" 9 "Star Button" 8 "Passenger Ventilated and/or heated seats" 7 "Driver Ventilated and/or heated seats" 6 "Rear Defrost" 5 "HVAC Defrost" 4 "IVI Volume" 3 "HVAC Fan Level" 2 "Passenger Seat Temp Set" 1 "Driver Seat Temp Set" 0 "No Request";
VAL_ 279 FDC_BCM_HMIKey6Func_Sta 15 "Function 6" 14 "Function 5" 13 "Function 4" 12 "Function 3" 11 "Function 2" 10 "Function 1" 9 "Star Button" 8 "Passenger Ventilated and/or heated seats" 7 "Driver Ventilated and/or heated seats" 6 "Rear Defrost" 5 "HVAC Defrost" 4 "IVI Volume" 3 "HVAC Fan Level" 2 "Passenger Seat Temp Set" 1 "Driver Seat Temp Set" 0 "No Request";
VAL_ 279 FDC_BCM_HMIKey7Func_Sta 15 "Function 6" 14 "Function 5" 13 "Function 4" 12 "Function 3" 11 "Function 2" 10 "Function 1" 9 "Star Button" 8 "Passenger Ventilated and/or heated seats" 7 "Driver Ventilated and/or heated seats" 6 "Rear Defrost" 5 "HVAC Defrost" 4 "IVI Volume" 3 "HVAC Fan Level" 2 "Passenger Seat Temp Set" 1 "Driver Seat Temp Set" 0 "No Request";
VAL_ 279 FDC_BCM_HMIKey8Func_Sta 15 "Function 6" 14 "Function 5" 13 "Function 4" 12 "Function 3" 11 "Function 2" 10 "Function 1" 9 "Star Button" 8 "Passenger Ventilated and/or heated seats" 7 "Driver Ventilated and/or heated seats" 6 "Rear Defrost" 5 "HVAC Defrost" 4 "IVI Volume" 3 "HVAC Fan Level" 2 "Passenger Seat Temp Set" 1 "Driver Seat Temp Set" 0 "No Request";
VAL_ 279 LVSilentChrgReq 1 "Request LV silent charging" 0 "No request,";
VAL_ 279 FDC_BCM_AutoWipHSpdEN_Sta 1 "Enable" 0 "Disable";
VAL_ 279 FDC_VCU_LVChrgFreq_Sta 2 "Silent charge frequently LV2" 1 "Silent charge frequently LV1" 0 "Normal";
VAL_ 279 FDC_VCU_TrailerDisOPD_Sta 1 "On" 0 "Off";
VAL_ 279 FDC_VCU_LVStaTooLow_Sta 1 "LV state too low" 0 "Normal";
VAL_ 279 FDC_VCU_LVStaDropQuick_Sta 1 "LV state drop quickly" 0 "Normal";
VAL_ 435 VehSpeed 4095 "Invalid";
VAL_ 435 LF_WhlRotDir 3 "Standstill" 2 "Backward" 1 "Forward" 0 "Unknown/Standby";
VAL_ 435 RF_WhlRotDir 3 "Standstill" 2 "Backward" 1 "Forward" 0 "Unknown/Standby";
VAL_ 435 RF_PulseCount_V 1 "Invalid" 0 "Valid";
VAL_ 435 LF_PulseCount_V 1 "Invalid" 0 "Valid";
VAL_ 435 RR_PulseCount_V 1 "Invalid" 0 "Valid";
VAL_ 435 RR_WhlRotDir 3 "Standstill" 2 "Backward" 1 "Forward" 0 "Unknown/Standby";
VAL_ 435 LR_PulseCount_V 1 "Invalid" 0 "Valid";
VAL_ 435 LR_WhlRotDir 3 "Standstill" 2 "Backward" 1 "Forward" 0 "Unknown/Standby";
VAL_ 435 ESC_BeepReq 1 "Request" 0 "No Request";
VAL_ 435 ESC_OFF_Status 2 "TCS and ESC OFF" 1 "TCS OFF" 0 "Normal";
VAL_ 435 HDD_Failed 1 "Failed" 0 "Normal";
VAL_ 435 AVH_Failed 1 "Failed" 0 "Normal";
VAL_ 435 HSA_Failed 1 "Failed" 0 "Normal";
VAL_ 435 PBA_Failed 1 "Failed" 0 "Normal";
VAL_ 435 HBB_Failed 1 "Failed" 0 "Normal";
VAL_ 435 ESC_Failed 1 "Failed" 0 "Normal";
VAL_ 435 TCS_Failed 1 "Failed" 0 "Normal";
VAL_ 435 ABS_Failed 1 "Failed" 0 "Normal";
VAL_ 435 EBD_Failed 1 "Failed" 0 "Normal";
VAL_ 435 HDD_Active 1 "Active" 0 "Inactive";
VAL_ 435 ESS_Active 1 "Active" 0 "Inactive";
VAL_ 435 BTCS_Active 1 "Active" 0 "Inactive";
VAL_ 435 Amber_WnlmpSta 1 "Amber Wnlmp constant" 0 "Amber Wnlmp Off";
VAL_ 435 AVH_Active 1 "Active" 0 "Inactive";
VAL_ 435 HSA_Active 1 "Active" 0 "Inactive";
VAL_ 435 PBA_Active 1 "Active" 0 "Inactive";
VAL_ 435 HBB_Active 1 "Active" 0 "Inactive";
VAL_ 435 ABS_Active 1 "Active" 0 "Inactive";
VAL_ 435 ESC_WnlmpSta 2 "ESC lmp flash" 1 "ESC lmp permanent" 0 "ESC lmp Off";
VAL_ 435 ESC_Off_lmpSta 1 "ESC OFF lmp permanent" 0 "ESC OFF lmp Off";
VAL_ 435 ABS_WnlmpSta 1 "ABS Wnlmp constant" 0 "ABS Wnlmp Off";
VAL_ 435 Red_WnlmpSta 1 "Red Wnlmp constant" 0 "Red Wnlmp Off";
VAL_ 435 eBST_BeepReq 1 "Request" 0 "No Request";
VAL_ 435 eBST_RedWnlmpSta 1 "On" 0 "Off";
VAL_ 435 eBST_AmberWnlmpSta 1 "On" 0 "Off";
VAL_ 435 LowBrakeFluid_Sta 1 "Low" 0 "Normal";
VAL_ 435 HVBattVolt 8191 "Invalid";
VAL_ 435 DCDCAuxCur 4095 "Invalid";
VAL_ 435 DCDCAuxVolt 255 "Invalid";
VAL_ 435 Meter_Ind_VehSpeed 4095 "Invalid";
VAL_ 435 ESC_ADAS_Sta 6 "Haptic Brake" 5 "Vehicle Standstill" 4 "Vehicle Holding" 3 "Deceleration Control" 2 "AEB Emergency Brake" 1 "Prefill" 0 "Internal";
VAL_ 435 AEBAvail 1 "Available" 0 "Unavailable";
VAL_ 435 BrkDiscTempSta 1 "Over Temperature" 0 "Nomal";
VAL_ 435 BrkSw_Sta 1 "Active" 0 "Inactive";
VAL_ 435 BrkSw_V 1 "Invalid" 0 "Valid";
VAL_ 435 EBMErrSta 2 "Diagnostic Mode" 1 "Failed" 0 "Normal";
VAL_ 435 EBMRLampSta 2 "Flash" 1 "Permanent" 0 "Off";
VAL_ 435 LADB_Hibeam_Indication 1 "On" 0 "Off";
VAL_ 435 LADB_Operation_Status 1 "On" 0 "Off";
VAL_ 435 LADB_Warning 1 "On" 0 "Off";
VAL_ 435 LLB_Warning 1 "On" 0 "Off";
VAL_ 435 LAHB_Warning 1 "On" 0 "Off";
VAL_ 435 FLTurn_Light_Warning 1 "On" 0 "Off";
VAL_ 435 LDRL_Warning 1 "On" 0 "Off";
VAL_ 435 Lposition_Lamp_Warning 1 "On" 0 "Off";
VAL_ 435 RADB_Hibeam_Indication 1 "On" 0 "Off";
VAL_ 435 RADB_Operation_Status 1 "On" 0 "Off";
VAL_ 435 RADB_Warning 1 "On" 0 "Off";
VAL_ 435 RLB_Warning 1 "On" 0 "Off";
VAL_ 435 RAHB_Warning 1 "On" 0 "Off";
VAL_ 435 FRTurn_Light_Warning 1 "On" 0 "Off";
VAL_ 435 RDRL_Warning 1 "On" 0 "Off";
VAL_ 435 Rposition_Lamp_Warning 1 "On" 0 "Off";
VAL_ 435 CrashOutputSts 255 "Invalid" 62 "Rollover+Left+Right+Rear+Front" 60 "Rollover+Left+Right+Rear" 58 "Rollover+Left+Right+Front" 56 "Rollover+Left+Right" 54 "Rollover+Left+Rear+Front" 52 "Rollover+Left+Rear" 50 "Rollover+Left+Front" 48 "Rollover+Left" 46 "Rollover+Right+Rear+Front" 44 "Rollover+Right+Rear" 42 "Rollover+Right+Front" 40 "Rollover+Right" 38 "Rollover+Rear+Front" 36 "Rollover+Rear" 34 "Rollover+Front" 32 "Rollover" 30 "Left+Right+Rear+Front" 28 "Left+Right+Rear" 26 "Left+Right+Front" 24 "Left+Right" 22 "Left+Rear+Front" 20 "Left+Rear" 18 "Left+Front" 16 "Left" 14 "Right+Rear+Front" 12 "Right+Rear" 10 "Right+Front" 8 "Right" 6 "Rear+Front" 4 "Rear" 2 "Front" 0 "No Crash";
VAL_ 435 EpasFailed 2 "Perm Faild" 1 "Temp Faild" 0 "Not Faild";
VAL_ 435 AirBagFailCmd 1 "Lamp ON" 0 "Lamp OFF";
VAL_ 435 DriverSeatBeltCmd 1 "Lamp ON" 0 "Lamp OFF";
VAL_ 435 DrPMMLVOutPErrLmp 1 "Error" 0 "Normal";
VAL_ 435 DrPMMSysErrLmp 1 "Error" 0 "Normal";
VAL_ 435 DrSCPSysErrLmp 1 "Error" 0 "Normal";
VAL_ 435 FireDetErr 1 "Fault" 0 "Normal";
VAL_ 435 FrPMMLimpHomeActReq 1 "Error" 0 "Normal";
VAL_ 435 HVBattErr 1 "Battery Error" 0 "None";
VAL_ 435 PABSwitchCmd 1 "Lamp ON" 0 "Lamp OFF";
VAL_ 435 PsngrSeatBeltCmd 1 "Lamp ON" 0 "Lamp OFF";
VAL_ 435 RCenterSeatBeltCmd 1 "Lamp ON" 0 "Lamp OFF";
VAL_ 435 RDriverSeatBeltCmd 1 "Lamp ON" 0 "Lamp OFF";
VAL_ 435 RPsngrSeatBeltCmd 1 "Lamp ON" 0 "Lamp OFF";
VAL_ 435 SAS_V 1 "Valid" 0 "Invalid";
VAL_ 435 TLHPsngrSeatBeltCmd 1 "Lamp ON" 0 "Lamp OFF";
VAL_ 435 TRHPsngrSeatBeltCmd 1 "Lamp ON" 0 "Lamp OFF";
VAL_ 435 ABM_Passenger_ODS_Sta 1 "LAMP ON" 0 "LAMP OFF";
VAL_ 435 ABM_RearPassengerLH_ODS_Sta 1 "LAMP ON" 0 "LAMP OFF";
VAL_ 435 ABM_RearPassengerCTR_ODS_Sta 1 "LAMP ON" 0 "LAMP OFF";
VAL_ 435 ABM_RearPassengerRH_ODS_Sta 1 "LAMP ON" 0 "LAMP OFF";
VAL_ 435 LADBErr 1 "Error" 0 "Normal";
VAL_ 435 LH_BeamErr 1 "Error" 0 "Normal";
VAL_ 435 LL_BeamErr 1 "Error" 0 "Normal";
VAL_ 435 RADBErr 1 "Error" 0 "Normal";
VAL_ 435 RH_BeamErr 1 "Error" 0 "Normal";
VAL_ 435 RL_BeamErr 1 "Error" 0 "Normal";
VAL_ 435 RLTurnLPErr 1 "Error" 0 "Normal";
VAL_ 435 RRTurnLPErr 1 "Error" 0 "Normal";
VAL_ 435 FLTurnLPErr 1 "Error" 0 "Normal";
VAL_ 435 FRTurnLPErr 1 "Error" 0 "Normal";
VAL_ 372 ADAS_LFC_Warn_Sound 1 "Warning Sound" 0 "OFF";
VAL_ 372 ADAS_CAM_SpdLim 31 "80mph" 30 "75mph" 29 "70mph" 28 "65mph" 27 "60mph" 26 "55mph" 25 "50mph" 24 "45mph" 23 "40mph" 22 "35mph" 21 "30mph" 20 "25mph" 19 "20mph" 18 "15mph" 17 "10mph" 16 "160 km/h" 15 "150 km/h" 14 "140 km/h" 13 "130 km/h" 12 "120 km/h" 11 "110 km/h" 10 "100 km/h" 9 "90 km/h" 8 "80 km/h" 7 "70 km/h" 6 "60 km/h" 5 "50 km/h" 4 "40 km/h" 3 "30 km/h" 2 "20 km/h" 1 "10 km/h" 0 "No request";
VAL_ 372 ADAS_SLIF_SpdLim 31 "80mph" 30 "75mph" 29 "70mph" 28 "65mph" 27 "60mph" 26 "55mph" 25 "50mph" 24 "45mph" 23 "40mph" 22 "35mph" 21 "30mph" 20 "25mph" 19 "20mph" 18 "15mph" 17 "10mph" 16 "160 km/h" 15 "150 km/h" 14 "140 km/h" 13 "130 km/h" 12 "120 km/h" 11 "110 km/h" 10 "100 km/h" 9 "90 km/h" 8 "80 km/h" 7 "70 km/h" 6 "60 km/h" 5 "50 km/h" 4 "40 km/h" 3 "30 km/h" 2 "20 km/h" 1 "10 km/h" 0 "No request";
VAL_ 372 ADAS_ISA_Sta 6 "Invalid" 5 "Disable" 4 "Error" 3 "Blinking" 2 "Active" 1 "Standby" 0 "Off";
VAL_ 372 ADAS_WarningMsg 15 "reserve" 14 "reserve" 13 "reserve" 12 "reserve" 11 "reserve" 10 "reserve" 9 "reserve" 8 "reserve" 7 "Takeover Request" 6 "Disable to Engage FSRA" 5 "FSRA Disengaged" 4 "Available to resume Acceleration Control" 3 "Object Disappeared" 2 "reserve" 1 "reserve" 0 "None";
VAL_ 372 ACC_ObjDstLvl 4 "Level 4" 3 "Level 3" 2 "Level 2" 1 "Level 1" 0 "None";
VAL_ 372 ADAS_ACC_Sta 6 "Disable" 5 "Error" 4 "Shut-off" 3 "Override" 2 "Active" 1 "Standby" 0 "Off";
VAL_ 372 ADAS_AEBReq 3 "Request Level III" 2 "Request Level II" 1 "Request Level I" 0 "No Request";
VAL_ 372 ADAS_AEB_Sta 4 "Disable" 3 "Error" 2 "Active" 1 "Standby" 0 "Off";
VAL_ 372 ADAS_FCW_Sta 4 "Disable" 3 "Error" 2 "Active" 1 "Standby" 0 "Off";
VAL_ 372 ADAS_LaneModeL 1 "Detected" 0 "Not detected";
VAL_ 372 ADAS_LaneModeR 1 "Detected" 0 "Not detected";
VAL_ 372 ADAS_LDW_Sta 6 "Disable" 5 "Error" 4 "Right warning" 3 "Left warning" 2 "Active" 1 "Standby" 0 "Off";
VAL_ 372 ADAS_LFC_Sta 5 "Disable" 4 "Error" 3 "Green Blinking" 2 "Green" 1 "White" 0 "OFF";
VAL_ 372 ADAS_LKA_Sta 6 "Disable" 5 "Error" 4 "Right Assist" 3 "Left Assist" 2 "Active" 1 "Standby" 0 "Off";
VAL_ 372 ADAS_SLIF_Sta 5 "Disable" 4 "Invalid" 3 "Temporary Unavailable" 2 "System Fail" 1 "Normal (Default)" 0 "OFF";
VAL_ 372 ADAS_LFC_Hands_Off_Warning 3 "Automatic release warning" 2 "2nd Warning" 1 "1st Warning" 0 "OFF";
VAL_ 372 ACC_TakeoverReq 1 "request" 0 "no request";
VAL_ 372 ActBrkLamp_Sta 1 "On" 0 "Off";
VAL_ 372 ADAS_FCW_Mute 1 "Mute" 0 "No Mute";
VAL_ 372 ADAS_FltWrnReq 1 "Warning Request" 0 "No Warning";
VAL_ 372 ADAS_LDW_Mute 1 "Mute" 0 "No Mute";
VAL_ 372 LVDA_Mute_Sta 3 "Invalid" 2 "Mute" 1 "No Mute" 0 "Default";
VAL_ 372 LKA_HOD_Display_Warning 1 "Hands-off Warning" 0 "No Warning";
VAL_ 372 LKA_HOD_Sound_Warning 1 "Hands-off Warning" 0 "No Warning";
VAL_ 372 LVDA_ACCStatusInformation 1 "ACC is in stop-hold mode" 0 "Default";
VAL_ 372 LVDA_Disabled 1 "Disabled" 0 "Enabled";
VAL_ 372 LVDA_Failinfo 1 "Fail" 0 "No fail";
VAL_ 372 LVDA_Warning 1 "Warning" 0 "No warning";
VAL_ 372 ISA_WarningMsg 6 "Invalid" 5 "Disable to Engage ISA" 4 "ISA Disengaged" 3 "Available to resume ISA Control" 2 "reserve" 1 "reserve" 0 "None";
VAL_ 372 ForceLowBeam 2 "Invalid" 1 "Force Low Beam" 0 "No Request";
VAL_ 372 CameraBlockage 1 "Blockage" 0 "Normal";
VAL_ 372 HazardWarningReq 1 "Request" 0 "No Request";
VAL_ 372 LeftTurnLightReq 1 "Request" 0 "No Request";
VAL_ 372 Target_Type 4 "Truck" 3 "Two Wheel" 2 "Vehicle" 1 "Pedestrian" 0 "None";
VAL_ 372 RightTurnLightReq 1 "Request" 0 "No Request";
VAL_ 372 ADAS_FCW_Sensitivity 1 "High" 0 "Low";
VAL_ 372 ADAS_LDW_Sensitivity 1 "High" 0 "Low";
VAL_ 372 MCU_B_R_RealPwrKw_Sta 65535 "Invalid";
VAL_ 372 MCU_B_F_RealPwrKw_Sta 65535 "Invalid";
VAL_ 372 HVBSOH 255 "Invalid";
VAL_ 372 FDC_BCM_TimeGapLevel_Sta 4 "Level 4" 3 "Level 3" 2 "Level 2" 1 "Level 1" 0 "Off";
VAL_ 450 HVBChrgErr 255 "Invalid" 4 "EVFault" 3 "EVStop" 2 "EvseFAULT" 1 "SocMeetTarget" 0 "OK";
VAL_ 450 V2LSta 3 "Invalid" 2 "SW on" 1 "V2L Adapter Plug-in" 0 "No plug";
VAL_ 450 DisChrgPlugErr 2 "(un)lock request invalid" 1 "plug-in incomplete" 0 "Normal";
VAL_ 450 ExtChrgSta 3 "Fault" 2 "Charging Completed" 1 "Charging" 0 "No action";
VAL_ 450 ChrgPlugSta 3 "Plug-in dectected" 2 "DC Plug in" 1 "AC Plug in" 0 "No plug";
VAL_ 450 HVBOvrTempErr 1 "fault" 0 "No fault";
VAL_ 450 OBC_AC_Cur_Lim 3 "80A" 2 "45A" 1 "32A" 0 "16A";
VAL_ 450 HVBOvrTempWarn 2 "Warn2" 1 "Warn1" 0 "No fault";
VAL_ 450 Shifter_Fail_sta 3 "shifter failure" 2 "Hall failure" 1 "P button failure" 0 "normal";
VAL_ 450 Shifter_Handle_Cmd 255 "invalid" 7 "Reverse" 5 "Drive" 4 "Neutral" 2 "Park" 0 "Default";
VAL_ 450 OBCACVoltInf 4095 "Invalid";
VAL_ 450 OBCFaultSta 3 "Invalid" 2 "Any Fault" 1 "Working" 0 "Not Working";
VAL_ 450 FrntPTCLeActHeatPwr 255 "Invalid" 201 "~ 0xFE Invalid";
VAL_ 450 FrntPTCRiActHeatPwr 255 "Invalid" 201 "~ 0xFE Invalid";
VAL_ 450 FrntPTCRearLeActHeatPwr 255 "Invalid" 201 "-0xFE:Reserved";
VAL_ 450 FrntPTCRearRiActHeatPwr 255 "Invalid";
VAL_ 450 HVBContactorSta 1 "Closed" 0 "Open";
VAL_ 450 RLS_Lamp_Sta 1 "Lamps ON" 0 "Lamps OFF";
VAL_ 450 SWC_ACC_Sta 1 "Press" 0 "Release";
VAL_ 450 SWC_Down_Sta 1 "Press" 0 "Release";
VAL_ 450 SWC_RegenUp 1 "Press" 0 "Release";
VAL_ 450 SWC_Left_Sta 1 "Press" 0 "Release";
VAL_ 450 SWC_mode_Sta 1 "Press" 0 "Release";
VAL_ 450 SWC_Right_Sta 1 "Press" 0 "Release";
VAL_ 450 SWC_Trip_Sta 1 "Press" 0 "Release";
VAL_ 450 SWC_Up_Sta 1 "Press" 0 "Release";
VAL_ 450 SWC_LKA_Sta 1 "Press" 0 "Release";
VAL_ 450 SWC_Undefined_Sta 1 "Press" 0 "Release";
VAL_ 450 SWC_VR_Sta 1 "Press" 0 "Release";
VAL_ 450 ChargeInletLockSta 1 "Lock" 0 "Unlock";
VAL_ 450 COMP_ActualPwr 8191 "Invalid";
VAL_ 450 MainRlyPosSta 3 "Error" 2 "Closed" 1 "Open" 0 "None";
VAL_ 450 MainRlyNegSta 3 "Error" 2 "Closed" 1 "Open" 0 "None";
VAL_ 450 P_Dkey_Show_IVI 7 "invalid" 6 "IVI PHONE Green" 5 "IVI PHONE Red" 4 "IVI UID Green" 3 "IVI UID Red" 2 "IVI NFC Card Green" 1 "IVI NFC Card Red" 0 "Default";
VAL_ 450 P_KeyMiss 1 "Key Miss" 0 "Default";
VAL_ 450 P_UID_LowPower 1 "On" 0 "Off";
VAL_ 450 HVBMTempMax 255 "Invalid";
VAL_ 450 TBOX_NET_SIG_STR 8 "wifi comes back" 7 "wifi leaves home" 6 "Error" 5 "no signal" 4 "4 bars" 3 "3 bars" 2 "2 bars" 1 "1 bar" 0 "Invalid";
VAL_ 450 TBOX_TEST_STATUS 15 "Invalid" 8 "OTA updating" 7 "RS-232 Transceiver Failure" 6 "CAN Controller Failure" 5 "3G Module Failure" 4 "Flash Error" 3 "SIM Card Failed" 2 "ECU Internal Error" 1 "WM Self Test OK" 0 "WM Self Testing";
VAL_ 450 CbnPreACEnaReq 3 "Reserved" 2 "Not Set" 1 "Enable A/C" 0 "Disable A/C";
VAL_ 450 Re_Radio 1 "Radio turn on" 0 "Radio turn off";
VAL_ 450 TrailerModeSta 3 "YELLOW" 2 "RED" 1 "GREEN" 0 "OFF";
VAL_ 450 TrailerCheck 1 "Complete" 0 "Detecting";
VAL_ 450 SWC_RegenDown 1 "Press" 0 "Release";
VAL_ 450 FDC_BCM_FWipSw_Sta 7 "Invalid" 4 "AutoPlus" 3 "High" 2 "Low" 1 "Auto" 0 "OFF";
VAL_ 450 FDC_BCM_TurnSw_Sta 3 "Invalid" 2 "Right" 1 "Left" 0 "OFF";
VAL_ 450 FDC_BCM_DimSw 1 "On" 0 "Off";
VAL_ 450 OBCACCSLimit 255 "Invalid";
VAL_ 450 ZFR_BCM_ChargerDoorSW_Sta 1 "Open" 0 "Close";
VAL_ 450 DKC_KeyType_Sta 3 "Invalid" 2 "NFC" 1 "UID" 0 "No Request";
VAL_ 450 DKC_KeyNum_Sta 15 "Invalid" 14 "Key 14" 13 "Key 13" 12 "Key 12" 11 "Key 11" 10 "Key 10" 9 "Key 9" 8 "Key 8" 7 "Key 7" 6 "Key 6" 5 "Key 5" 4 "Key 4" 3 "Key 3" 2 "Key 2" 1 "Key 1" 0 "No Request";
VAL_ 450 ZFR_EChrg_Active_Sta 7 "Pinch Reverse" 6 "Stoped Halfway" 5 "Ready to Act" 4 "Power Closing" 3 "Power Opening" 2 "Fully Opened" 1 "Fully Closed" 0 "Signal Not Available";
VAL_ 450 ZFR_EChrg_Sys_Sta 3 "Signal Not Available" 2 "Abnormal" 1 "Normal" 0 "Uninitialized";
VAL_ 450 ZFR_EChrg_OperationDeny_Cmd 2 "Close deny" 1 "Open deny" 0 "Normal";
VAL_ 450 ZFR_EChrg_WashMode_Sta 1 "Active" 0 "Not active";
VAL_ 450 EBMSta 7 "Invalid" 6 "CompletelyReleased" 5 "Released" 4 "Releasing" 3 "Applying" 2 "HoldApplied" 1 "ParkApplied" 0 "Unknown";
VAL_ 528 USS_Sta_FCL 1 "Checked error" 0 "Checked OK";
VAL_ 528 USS_Sta_FCR 1 "Checked error" 0 "Checked OK";
VAL_ 528 USS_Sta_FLL 1 "Checked error" 0 "Checked OK";
VAL_ 528 USS_Sta_FLR 1 "Checked error" 0 "Checked OK";
VAL_ 528 USS_Sta_FML 1 "Checked error" 0 "Checked OK";
VAL_ 528 USS_Sta_FMR 1 "Checked error" 0 "Checked OK";
VAL_ 528 USS_Sta_RCL 1 "Checked error" 0 "Checked OK";
VAL_ 528 USS_Sta_RCR 1 "Checked error" 0 "Checked OK";
VAL_ 528 USS_Sta_RLL 1 "Checked error" 0 "Checked OK";
VAL_ 528 USS_Sta_RLR 1 "Checked error" 0 "Checked OK";
VAL_ 528 USS_Sta_RML 1 "Checked error" 0 "Checked OK";
VAL_ 528 USS_Sta_RMR 1 "Checked error" 0 "Checked OK";
VAL_ 528 PAS_A_FCR 4 "level 4 (Far distance)" 3 "level 3" 2 "level 2" 1 "level 1 (Near distance)" 0 "No signal";
VAL_ 528 PAS_A_FML 4 "level 4 (Far distance)" 3 "level 3" 2 "level 2" 1 "level 1 (Near distance)" 0 "No signal";
VAL_ 528 PAS_A_FMR 4 "level 4 (Far distance)" 3 "level 3" 2 "level 2" 1 "level 1 (Near distance)" 0 "No signal";
VAL_ 528 PAS_A_RCL 4 "level 4 (Far distance)" 3 "level 3" 2 "level 2" 1 "level 1 (Near distance)" 0 "No signal";
VAL_ 528 PAS_A_RCR 4 "level 4 (Far distance)" 3 "level 3" 2 "level 2" 1 "level 1 (Near distance)" 0 "No signal";
VAL_ 528 PAS_A_RML 4 "level 4 (Far distance)" 3 "level 3" 2 "level 2" 1 "level 1 (Near distance)" 0 "No signal";
VAL_ 528 PAS_A_RMR 4 "level 4 (Far distance)" 3 "level 3" 2 "level 2" 1 "level 1 (Near distance)" 0 "No signal";
VAL_ 528 PAS_SNSR_Layout 7 "PAS_R2" 6 "PAS_R2F2" 5 "PAS_R4" 4 "PAS_F2R4" 3 "PAS_F4R4" 2 "APA" 1 "APS" 0 "Nomassage";
VAL_ 528 PAS_D_FCL 255 "FarDistance" 150 "Max" 0 "Min";
VAL_ 528 PAS_D_FCR 255 "FarDistance" 150 "Max" 0 "Min";
VAL_ 528 PAS_D_FML 255 "FarDistance" 150 "Max" 0 "Min";
VAL_ 528 PAS_D_FMR 255 "FarDistance" 150 "Max" 0 "Min";
VAL_ 528 APS_ExitCondition 51 "ENUM_EXC_OSPARK" 50 "ENUM_EXC_DCTOOFARSlOTFIND" 49 "ENUM_EXC_TO4OBSTFRONT" 48 "ENUM_EXC_TO4OBSTREAR" 46 "ENUM_EXC_OCDRIVERINTERF" 45 "ENUM_EXC_OCPPSTOOSMALL" 44 "ENUM_EXC_OCDOORSOPEN" 43 "ENUM_EXC_OCSWITCHOFFAPA" 42 "ENUM_EXC_OCSWITCHOFFPA" 41 "ENUM_EXC_OCWRONGDIR" 40 "ENUM_EXC_OTEPSERROR" 39 "ENUM_EXC_OTEVCUERROR" 38 "ENUM_EXC_OTBRAKEERROR" 37 "ENUM_EXC_OTGEARERROR" 36 "ENUM_EXC_OTEPBERROR" 35 "ENUM_EXC_OTCANERROR" 34 "ENUM_EXC_OTAPAERROR" 33 "ENUM_EXC_OTSENSORERROR" 32 "ENUM_EXC_OTOEMERROR" 81 "ENUM_EXC_OSSCA" 80 "ENUM_EXC_OSSCAWARNING" 79 "ENUM_EXC_DCTOOFARSCA" 77 "ENUM_EXC_OCSCADOORSOPEN" 76 "ENUM_EXC_OCSCASWITCHOFFAPA" 75 "ENUM_EXC_OCSCASWITCHOFFPA" 74 "ENUM_EXC_OCSCAWRONGDIR" 73 "ENUM_EXC_OTSCACAMERAERROR" 72 "ENUM_EXC_OTSCAEPSERROR" 71 "ENUM_EXC_OTSCAEVCUERROR" 70 "ENUM_EXC_OTSCABRAKEERROR" 69 "ENUM_EXC_OTSCAGEARERROR" 68 "ENUM_EXC_OTSCAEPBERROR" 131 "ENUM_EXC_TO4STANDING" 67 "ENUM_EXC_OTSCACANERROR" 130 "ENUM_EXC_TO4STANDSTILL" 66 "ENUM_EXC_OTSCAAPAERROR" 129 "ENUM_EXC_OCGEARCOUNT" 65 "ENUM_EXC_OTSCASENSORERROR" 64 "ENUM_EXC_OTSCAOEMERROR" 0 "ENUM_EXC_NOERROR";
VAL_ 528 PAS_D_RCL 255 "FarDistance" 150 "Max" 0 "Min";
VAL_ 528 PAS_D_RCR 255 "FarDistance" 150 "Max" 0 "Min";
VAL_ 528 PAS_D_RML 255 "FarDistance" 150 "Max" 0 "Min";
VAL_ 528 PAS_D_RMR 255 "FarDistance" 150 "Max" 0 "Min";
VAL_ 528 APS_RQ_Display 48 "APS Cancelled because ABS or TCS active" 47 "APS Cancelled because the slope is too steep" 46 "APS Cancelled because Tailgate is opened" 45 "APS Cancelled because Hood is opened" 44 "APS Cancelled because gear position is wrong" 43 "APS Cancelled because POWER is not ready" 42 "Please make sure the doors are closed and the seat belts are fastened." 41 "APS Cancelled because IVI or AVM is not ready" 40 "Driver seat belt is not fastened" 39 "Operation Timeout 2 min Please take over the vehicle" 38 "Operation Timeout 6 min Please take over the vehicle" 37 "Operation Timeout 1 min Please take over the vehicle" 36 "VCU failed Please take over steering" 35 "APS Cancelled because driver enable the EPB" 34 "APS Cancelled because driver intervenes the acceleration pedal" 33 "APS Cancelled because driver Intervention gear Please take over steering" 32 "APS Cancelled because driver Intervention brake Please take over steering" 31 "APS Cancelled because driver Intervention steering Please take over steering" 30 "APS Cancelled by driver" 29 "APS Cancelled because found the unknow object Please take over steering" 28 "APS Cancelled because the door is opened Please take over steering" 27 "The gear is changing to R-gear" 26 "The gear is changing to D-gear" 25 "Vehicle moving backward" 24 "Vehicle moving forward" 23 "APS System Error Please take over steering" 22 "Steering assistant failed Please take over steering" 21 "ESC failed Please take over steering" 20 "Auto parking assistant active Please check around" 19 "Shift to P gear now" 18 "Parking Slot Undersize Please take over steering" 17 "Operation Timeout Please take over the vehicle" 16 "APS Cancelled Please take over the vehicle" 15 "APS Cancelled because the speed is too fast" 14 "Stop and ready for auto parking" 13 "Please drive forward" 12 "Vehicle stop" 11 "Parking achieved" 10 "Parking out Cancelled because the slot is too small" 9 "Obstacles appear on the way of driving" 8 "The left side perpendicular parking slot be found" 7 "The left side parallel parking slot be found" 6 "The right side perpendicular parking slot be found" 5 "The right side parallel parking slot be found" 4 "Searching for perpendicular parking slot on the left side" 3 "Searching for parallel parking slot on the left side" 2 "Searching for perpendicular parking slot on the right side" 1 "Searching for parallel parking slot on the right side" 0 "No message";
VAL_ 528 PAS_Chime 9 "APS change gear warning" 8 "R_USS Obstacle warning level 3" 7 "R_USS Obstacle warning level 2" 6 "R_USS Obstacle warning level 1" 5 "F_USS Obstacle warning level 3" 4 "F_USS Obstacle warning level 2" 3 "F_USS Obstacle warning level 1" 2 "PAS and APS check fault warning" 1 "PAS and APS check normal warning" 0 "No message";
VAL_ 528 PAS_A_FCL 4 "level 4 (Far distance)" 3 "level 3" 2 "level 2" 1 "level 1 (Near distance)" 0 "No signal";
VAL_ 528 APS_Sta_System 4 "Remote Actived" 3 "Failed" 2 "Active" 1 "Enable" 0 "Disable";
VAL_ 528 CAAS_Sta 4 "Shift Gear to P" 3 "Active" 2 "Enable" 1 "Disable" 0 "OFF";
VAL_ 528 FDC_VCU_RegenMode_Sta 7 "Invalid" 6 "One-Pedal" 5 "Level 5" 4 "Level 4" 3 "Level 3" 2 "Level 2" 1 "Level 1" 0 "Off";
VAL_ 528 FDC_VMC_SpdCtrlMode_Sta 5 "invalid" 4 "ISA" 3 "LIM" 2 "CC" 1 "ACC" 0 "OFF";
VAL_ 528 FDC_VMC_SpdCtrl_Sta 1 "ON" 0 "OFF";
VAL_ 528 VMC_VCU_CC_Crl_Sta 6 "Invalid" 5 "Error" 4 "Over Speed" 3 "Under Speed" 2 "Active" 1 "Standby" 0 "Off";
VAL_ 528 VMC_VCU_MSA_Crl_Sta 6 "Invalid" 5 "Error" 4 "Over Speed" 3 "Under Speed" 2 "Active" 1 "Standby" 0 "Off";
VAL_ 528 FDC_VCU_RegenLimInd_Sta 1 "ON" 0 "OFF";
VAL_ 528 FDC_VCU_SmartEco_Sta 1 "ON" 0 "OFF";
VAL_ 528 FDC_VCU_SmartEcoSpdLim_Sta 1 "ON" 0 "OFF";
VAL_ 528 DISC_DISCTargetSpd 4095 "Invalid";
VAL_ 528 FDC_VCU_SimSound_Cmd 4095 "Invalid";
VAL_ 823 ACChrgCurrDis 32767 "Invalid";
VAL_ 823 RemainChrgTime 4095 "Invalid";
VAL_ 823 HVBChrgPwr 1023 "Invalid";
VAL_ 823 HVBattSOCDis 255 "Invalid";
VAL_ 823 HVBattSOC 255 "Invalid";
VAL_ 823 Charge_Percent_Set 101 "Failed" 100 "Max" 0 "Min";
VAL_ 823 PTG_HW_Ver 31 "V31" 1 "V1" 0 "Invalid";
VAL_ 823 PTG_SW_Ver 31 "V31" 1 "V1" 0 "Invalid";
VAL_ 1077 TPMSWarnIndi 3 "Invalid" 2 "Indicator Flash" 1 "Indicator ON" 0 "Indicator OFF";
VAL_ 1077 TPMS_Res_Butt_Allow 1 "Allowable" 0 "Unallowable";
VAL_ 1077 AutoLTips 3 "Invalid" 2 "Auto location failed" 1 "Auto location seccessful" 0 "Normal";
VAL_ 1077 TPMS_Cali_Butt_Allow 1 "Allowable" 0 "Unallowable";
VAL_ 1077 CWheelTips 3 "invalid" 2 "Calibrate Wheel failed" 1 "Calibrate Wheel success" 0 "Normal";
VAL_ 1077 LRWheelTemp 255 "Invalid";
VAL_ 1077 RRWheelTemp 255 "Invalid";
VAL_ 1077 LFWheelTemp 255 "Invalid";
VAL_ 1077 RFWheelTemp 255 "Invalid";
VAL_ 1077 LRWheelPress 255 "Invalid" 250 "Max" 0 "Min";
VAL_ 1077 RRWheelPress 255 "Invalid" 250 "Max" 0 "Min";
VAL_ 1077 LFWheelPress 255 "Invalid" 250 "Max" 0 "Min";
VAL_ 1077 RFWheelPress 255 "Invalid" 250 "Max" 0 "Min";
VAL_ 1077 LRWheelDebug 1 "Receive" 0 "Normal";
VAL_ 1077 RRWheelDebug 1 "Receive" 0 "Normal";
VAL_ 1077 LFWheelDebug 1 "Receive" 0 "Normal";
VAL_ 1077 RFWheelDebug 1 "Receive" 0 "Normal";
VAL_ 1077 LRBatWarn 1 "Low" 0 "Normal";
VAL_ 1077 RRBatWarn 1 "Low" 0 "Normal";
VAL_ 1077 LFBatWarn 1 "Low" 0 "Normal";
VAL_ 1077 RFBatWarn 1 "Low" 0 "Normal";
VAL_ 1077 LRSensorFail 1 "Fail" 0 "Normal";
VAL_ 1077 RRSensorFail 1 "Fail" 0 "Normal";
VAL_ 1077 LFSensorFail 1 "Fail" 0 "Normal";
VAL_ 1077 RFSensorFail 1 "Fail" 0 "Normal";
VAL_ 1077 LRWheelTmpIndi 1 "overheated" 0 "Normal";
VAL_ 1077 RRWheelTmpIndi 1 "overheated" 0 "Normal";
VAL_ 1077 LFWheelTmpIndi 1 "overheated" 0 "Normal";
VAL_ 1077 RFWheelTmpIndi 1 "overheated" 0 "Normal";
VAL_ 1077 LRPressIndi 3 "invalid" 2 "pressure too low" 1 "pressure too high" 0 "Normal";
VAL_ 1077 RRPressIndi 3 "invalid" 2 "pressure too low" 1 "pressure too high" 0 "Normal";
VAL_ 1077 LFPressIndi 3 "invalid" 2 "pressure too low" 1 "pressure too high" 0 "Normal";
VAL_ 1077 RFPressIndi 3 "invalid" 2 "pressure too low" 1 "pressure too high" 0 "Normal";
VAL_ 1077 LFWheelShield 1 "disappear" 0 "appear";
VAL_ 1077 LRWheelShield 1 "disappear" 0 "appear";
VAL_ 1077 RFWheelShield 1 "disappear" 0 "appear";
VAL_ 1077 RRWheelShield 1 "disappear" 0 "appear";
VAL_ 1077 FDC_BCM_AmbBrightSta_Sta 101 "~0x7F Invalid";
VAL_ 1077 FDC_BCM_AmbColorSta_Sta 63 "Red(255,0,0)" 62 "IndianRed(205,92,92)" 61 "LightCoral(240,128,128)" 60 "Tomato(255,99,71)" 59 "OrangeRed(255,69,0)" 58 "Coral(255,127,80)" 57 "LightSalmon(255,160,122)" 56 "DarkOrange(255,140,0)" 55 "Bisque(255,228,196)" 54 "NavajoWhite(255,222,173)" 53 "BlanchedAlmond(255,235,205)" 52 "Gold(255,215,0)" 51 "LemonChiffon(255,250,205)" 50 "Yellow(255,255,0)" 49 "LightYellow(255,255,224)" 48 "Ivory(255,255,240)" 47 "LightGoldenrodYellow(250,250,210)" 46 "Beige(245,245,220)" 45 "GreenYellow(173,255,47)" 44 "Chartreuse(127,255,0)" 43 "Lime(0,255,0)" 42 "LimeGreen(50,205,50)" 41 "PaleGreen(152,251,152)" 40 "LightGreen(144,238,144)" 39 "SeaGreen(46,139,87)" 38 "SpringGreen(60,179,113)" 37 "MediumSpringGreen(0,255,127)" 36 "MediumAquamarine(0,250,154)" 35 "Auqamarin(127,255,170)" 34 "MediumTurquoise(72,209,204)" 33 "DarkCyan(0,139,139)" 32 "DarkTurquoise(0,206,209)" 31 "Cyan(0,255,255)" 30 "PaleTurquoise(175,238,238)" 29 "DeepSkyBlue(0,191,255)" 28 "SkyBlue(135,206,235)" 27 "LightSkyBlue(135,206,250)" 26 "DoderBlue(30,144,255)" 25 "CornflowerBlue(100,149,237)" 24 "RoyalBlue(65,105,225)" 23 "Navy(0,0,128)" 22 "DarkBlue(0,0,139)" 21 "MidnightBlue(25,25,112)" 20 "MediumBlue(0,0,205)" 19 "Blue(0,0,255)" 18 "DarkSlateBlue(72,61,139)" 17 "SlateBlue(106,90,205)" 16 "MediumSlateBlue(123,104,238)" 15 "MediumPurple(147,112,219)" 14 "BlueViolet(138,43,226)" 13 "Indigo(75,0,130)" 12 "DarkOrchid(153,50,204)" 11 "DarkVoilet(148,0,211)" 10 "MediumOrchid(186,85,211)" 9 "DarkMagenta(139,0,139)" 8 "Magenta(255,0,255)" 7 "Violet(238,130,238)" 6 "Orchid(218,112,214)" 5 "MediumVioletRed(199,21,133)" 4 "DeepPink(255,20,147)" 3 "HotPink(255,105,180)" 2 "PaleVioletRed(219,112,147)" 1 "Crimson(220,20,60)" 0 "LightPink(255,182,193)";
VAL_ 1077 FDC_BCM_AmbDimEN_Sta 1 "Enable" 0 "Disable";
VAL_ 1077 FDC_BCM_AmbFunEN_Sta 1 "Enable" 0 "Disable";
VAL_ 1077 FDC_BCM_AmbLinkDriSta_Sta 1 "Enable" 0 "Disable";
VAL_ 1077 FDC_BCM_AmbODAEN_Sta 1 "Enable" 0 "Disable";
VAL_ 1077 FDC_BCM_AmbPwrWarnEN_Sta 1 "Enable" 0 "Disable";
VAL_ 1077 FDC_BCM_AmbWelEN_Sta 1 "Enable" 0 "Disable";
VAL_ 1077 FDC_BCM_UserNow_Sta 7 "Rent" 6 "Guest" 5 "User 5" 4 "User 4" 3 "User 3" 2 "User 2" 1 "User 1" 0 "Invalid";
VAL_ 1077 FDC_BCM_TurnSwTSetSta_Sta 3 "Undefiend" 2 "7 times" 1 "5 times" 0 "3 times";
VAL_ 1077 FDC_BCM_PTGOpenHeight_Sta 7 "Invalid" 6 "Invalid" 5 "Invalid" 4 "Set by User" 3 "Lv3(80%)" 2 "Lv2(60%)" 1 "Lv1(40%)" 0 "Full Open";
VAL_ 1077 FDC_BCM_LockAlarm_Cmd 2 "Lock Fail" 1 "Lock" 0 "No Request";
VAL_ 1077 FDC_BCM_Acc1Sta_Sta 2 "Deleted" 1 "Exist" 0 "Not Exist";
VAL_ 1077 FDC_BCM_Acc2Sta_Sta 2 "Deleted" 1 "Exist" 0 "Not Exist";
VAL_ 1077 FDC_BCM_Acc3Sta_Sta 2 "Deleted" 1 "Exist" 0 "Not Exist";
VAL_ 1077 FDC_BCM_Acc4Sta_Sta 2 "Deleted" 1 "Exist" 0 "Not Exist";
VAL_ 1077 FDC_BCM_Acc5Sta_Sta 2 "Deleted" 1 "Exist" 0 "Not Exist";
VAL_ 1077 FDC_BCM_Key1Acc_Sta 7 "Rent" 6 "Guest" 5 "User 5" 4 "User 4" 3 "User 3" 2 "User 2" 1 "User 1" 0 "Not Linked";
VAL_ 1077 FDC_BCM_Key2Acc_Sta 7 "Rent" 6 "Guest" 5 "User 5" 4 "User 4" 3 "User 3" 2 "User 2" 1 "User 1" 0 "Not Linked";
VAL_ 1077 FDC_BCM_Key3Acc_Sta 7 "Rent" 6 "Guest" 5 "User 5" 4 "User 4" 3 "User 3" 2 "User 2" 1 "User 1" 0 "Not Linked";
VAL_ 1077 FDC_BCM_Key4Acc_Sta 7 "Rent" 6 "Guest" 5 "User 5" 4 "User 4" 3 "User 3" 2 "User 2" 1 "User 1" 0 "Not Linked";
VAL_ 1077 FDC_BCM_Key5Acc_Sta 7 "Rent" 6 "Guest" 5 "User 5" 4 "User 4" 3 "User 3" 2 "User 2" 1 "User 1" 0 "Not Linked";
VAL_ 1077 FDC_BCM_Key6Acc_Sta 7 "Rent" 6 "Guest" 5 "User 5" 4 "User 4" 3 "User 3" 2 "User 2" 1 "User 1" 0 "Not Linked";
VAL_ 1077 FDC_BCM_Key7Acc_Sta 7 "Rent" 6 "Guest" 5 "User 5" 4 "User 4" 3 "User 3" 2 "User 2" 1 "User 1" 0 "Not Linked";
VAL_ 1077 FDC_BCM_Key8Acc_Sta 7 "Rent" 6 "Guest" 5 "User 5" 4 "User 4" 3 "User 3" 2 "User 2" 1 "User 1" 0 "Not Linked";
VAL_ 1077 FDC_BCM_Key9Acc_Sta 7 "Rent" 6 "Guest" 5 "User 5" 4 "User 4" 3 "User 3" 2 "User 2" 1 "User 1" 0 "Not Linked";
VAL_ 1077 FDC_BCM_Key10Acc_Sta 7 "Rent" 6 "Guest" 5 "User 5" 4 "User 4" 3 "User 3" 2 "User 2" 1 "User 1" 0 "Not Linked";
VAL_ 1077 FDC_BCM_FollowMeENFun_Sta 1 "Enable" 0 "Disable";
VAL_ 1077 FDC_BCM_RmLpModeENFun_Sta 1 "Enable" 0 "Disable";
VAL_ 1077 FDC_BCM_WalkInUnLkEnFun_Sta 1 "Enable" 0 "Disable";
VAL_ 1077 FDC_BCM_WalkOutLkEnFun_Sta 1 "Enable" 0 "Disable";
VAL_ 1077 FDC_SPTG_SPTGENFun_Sta 1 "Enable" 0 "Disable";
VAL_ 1077 FDC_DKC_DkeyShowIVI_Sta 7 "invalid" 6 "IVI PHONE Green" 5 "IVI PHONE Red" 4 "IVI UID Green" 3 "IVI UID Red" 2 "IVI NFC Card Green" 1 "IVI NFC Card Red" 0 "Default";
VAL_ 1077 FDC_DKC_KeyMiss_Sta 1 "Key Miss" 0 "Default";
VAL_ 1077 FDC_DKC_UIDLowPower_Sta 1 "On" 0 "Off";
VAL_ 1077 FDC_FGS_AirInt_Sta 3 "LV3" 2 "LV2" 1 "LV1" 0 "Inactive";
VAL_ 1077 FDC_FGS_FGSCh_Sta 3 "Channel 3" 2 "Channel 2" 1 "Channel 1" 0 "No Command";
VAL_ 1077 FDC_FGS_IONSW_Sta 1 "ON" 0 "OFF";
VAL_ 1077 FDC_BCM_CLWinLockDr_Sta 1 "ON" 0 "OFF";
VAL_ 1077 FDC_THCM_APTCWarning_Sta 1 "Error" 0 "Normal";
VAL_ 1077 FDC_THCM_APTCForceOFF_Sta 1 "Error" 0 "Noraml";
VAL_ 1077 FDC_DKC_KeyNum_Sta 15 "Invalid" 14 "Key 14" 13 "Key 13" 12 "Key 12" 11 "Key 11" 10 "Key 10" 9 "Key 9" 8 "Key 8" 7 "Key 7" 6 "Key 6" 5 "Key 5" 4 "Key 4" 3 "Key 3" 2 "Key 2" 1 "Key 1" 0 "No Request";
VAL_ 1077 FDC_DKC_KeyType_Sta 3 "Phone Key (reserve)" 2 "NFC" 1 "UID" 0 "No Request";
VAL_ 1077 FDC_THCM_AirIntZ3_Sta 4 "Level 3" 3 "Level 2" 2 "Level 1" 1 "OFF" 0 "Invalid";
VAL_ 1077 FDC_BCM_AutoLock_Sta 1 "Enable" 0 "Disable";
VAL_ 1077 FDC_BCM_AutoUnlock_Sta 1 "Enable" 0 "Disable";
VAL_ 1077 FDC_BCM_DSEATentryfset_Sta 1 "ON" 0 "OFF";
VAL_ 1077 FDC_BCM_HBeamADB_Cmd 3 "HBeam" 2 "ADB" 1 "StandBy" 0 "OFF";
VAL_ 1280 NM_FUSION_PNI 1 "NM PDU contains Partial Network request information" 0 "NM PDU contains no Partial Network request information";
VAL_ 1280 NM_FUSION_Active_WU 1 "Node has woken up the network (active Wakeup)" 0 "Node has not woken up the network (passive wakeup)";
VAL_ 1280 NM_FUSION_CSB 1 "Start of synchronized shutdown is requested by main coordinator" 0 "Start of synchronized shutdown is not requested by main coordinator";
VAL_ 1280 NM_FUSION_Rpt_Msg_Req 1 "Repeat Message State requested" 0 "Repeat Message State not requested";
VAL_ 1280 NM_FUSION_ERROR_State 8 "BUS OFF_L2" 4 "BUS OFF_L1" 2 "ERROR PASSIVE" 1 "ERROR ACTIVE" 0 "Inactive";
VAL_ 1080 OTA_Progress_Rate 102 "Invalid" 101 "Not in progress";
VAL_ 1080 OTA_DL_Available 1 "Ready for Download" 0 "Not Ready";
VAL_ 1080 OTA_Mode 1 "OTA mode" 0 "Normal mode";
VAL_ 1080 OTA_Network_Type 3 "Undefine" 2 "WiFi" 1 "LTE" 0 "Network Not Available";
VAL_ 1080 OTA_MDA_Status 15 "Undefine" 14 "Vehicle Reversed" 13 "OTA Task Finished" 12 "Vehicle Update Complete" 11 "Update Failed" 10 "Download Failed" 9 "Wait Arm" 8 "Download Suspend" 7 "Vehicle Roll-Back" 6 "Vehicle Updating" 5 "Wait Update" 4 "Campaign Downloading" 3 "Wait Download" 2 "Ask Campaign" 1 "Wait Network" 0 "Not Ready";
VAL_ 1080 OTA_Updating_ECU_8bit 255 "Invalid" 43 "CSW" 42 "Meter" 41 "WCM" 40 "LDM_RR" 39 "LDM_RL" 38 "LDM_FR" 37 "LDM_FL" 36 "BodyZone_Ps" 35 "BodyZone_Dr" 34 "DKC_UWB3" 33 "DKC_UWB2" 32 "DKC_UWB1" 31 "DKC_NFC" 30 "DKC_BLE" 29 "HMI" 28 "W_PTC" 27 "EBM" 26 "AIRPTC" 25 "E_Compressor" 24 "Shifter" 23 "TELLTALE" 22 "MRR" 21 "SRR_M" 20 "FCM" 19 "EPS" 18 "EOP_F" 17 "EOP_R" 16 "MCU_F" 15 "MCU_R" 14 "eBST" 13 "ESC" 12 "ABM" 11 "PSEAT" 10 "DSEAT" 9 "PTG" 8 "CCU" 7 "BMS" 6 "DKC" 5 "Zone_Dr" 4 "Zone_Fr" 3 "T-Box" 2 "IVI" 1 "FDC" 0 "No action";
VAL_ 1080 OTA_Update_Available 1 "Ready for Update" 0 "Not Ready";
VAL_ 1080 OTA_InVehicle_FW 2 "FW Need Update" 1 "FW Up to Date" 0 "Not Confirm";
VAL_ 1080 OTA_TBOXResetReq 1 "Request reset" 0 "No request";
VAL_ 1080 OTA_Lock_Req 1 "Lock Request" 0 "No action";
VAL_ 1080 OTA_Remained_Time 1081 "No action";
VAL_ 1080 OTA_Permit_Agreed 1 "Confirmed" 0 "Not Confirm";
VAL_ 1080 OTA_Debug_Code 63 "Backend unreachable" 56 "ECU upgrade stuck" 40 "Invalid parameter" 55 "ECU invalid data" 54 "ECU timeout" 53 "ECU unreachable" 51 "Method not support" 50 "Unknown error" 65 "Backend invalid data" 64 "Backend timeout" 0 "Normal state";
VAL_ 1080 OTA_Emergency_Sta 2 "Emergency - Lock Mode" 1 "Emergency - Limp Mode" 0 "Normal";
VAL_ 517 SRR_ODA_Sta 5 "Disable" 4 "Blockage" 3 "Failure" 2 "Active" 1 "Standby" 0 "Off";
VAL_ 517 SRR_BSD_Sta 5 "Disable" 4 "Blockage" 3 "Failure" 2 "Active" 1 "Standby" 0 "Off";
VAL_ 517 SRR_RCTA_Sta 5 "Disable" 4 "Blockage" 3 "Failure" 2 "Active" 1 "Standby" 0 "Off";
VAL_ 517 SRR_ODA_WarnR 2 "Flash" 1 "Lit" 0 "No Warning";
VAL_ 517 SRR_ODA_WarnL 2 "Flash" 1 "Lit" 0 "No Warning";
VAL_ 517 SRR_ODA_SoundR 1 "On" 0 "Off";
VAL_ 517 SRR_ODA_SoundL 1 "On" 0 "Off";
VAL_ 517 SRR_ODA_Mute 1 "Mute" 0 "No Mute";
VAL_ 517 SRR_BSD_WarnR 2 "Flash" 1 "Lit" 0 "No Warning";
VAL_ 517 SRR_BSD_WarnL 2 "Flash" 1 "Lit" 0 "No Warning";
VAL_ 517 SRR_BSD_SoundR 1 "On" 0 "Off";
VAL_ 517 SRR_BSD_SoundL 1 "On" 0 "Off";
VAL_ 517 SRR_BSD_Mute 1 "Mute" 0 "No Mute";
VAL_ 517 SRR_RCTA_WarnR 1 "Warning" 0 "No Warning";
VAL_ 517 SRR_RCTA_WarnL 1 "Warning" 0 "No Warning";
